VERSION ""

NS_ :

BS_:

BU_: AuxInput VT TECU TC Sprayer GPS
VAL_TABLE_ FMI 21 "Data Drifted Low" 20 "Data Drifted High" 31 "Not available" 19 "Received network data in error" 18 "Below normal (moderatels severe)" 17 "Below normal (least severe)" 16 "Above normal (moderately severe)" 15 "Above normal (least severe)" 14 "Special intstructions" 13 "Out of calibration" 12 "Bad intelligent device" 11 "Root cause not known" 10 "Abnormal rate of change" 9 "Abnormal update rate" 8 "Abnormal frequency" 7 "Mechanical system not responding" 6 "Current above normal" 5 "Current below normal" 4 "Voltage below normal" 3 "Voltage above normal" 2 "Data erratic" 1 "Below normal (most severe)" 0 "Above normal (most severe)" ;

BO_ 3221225472 VECTOR__INDEPENDENT_SIG_MSG: 0 Vector__XXX
 SG_ ErrorCodeLockUnlockMask9 : 0|1@1+ (1,0) [0|1] "" Vector__XXX
 SG_ CertificationYear : 0|6@1+ (1,2000) [2000|2061] "year" Vector__XXX
 SG_ CertificateRevision : 0|3@1+ (1,0) [0|7] "" Vector__XXX
 SG_ CertificateLaboratoryType : 0|3@1+ (1,0) [0|7] "" Vector__XXX
 SG_ CertificationLaboratoryID : 0|11@1+ (1,0) [0|2047] "" Vector__XXX
 SG_ CertTypeVTWorkingSetMember : 0|1@1+ (1,0) [0|1] "" Vector__XXX
 SG_ CertTypeVTWorkingSetMaster : 0|1@1+ (1,0) [0|1] "" Vector__XXX
 SG_ CertTypeVirtualTerminal : 0|1@1+ (1,0) [0|1] "" Vector__XXX
 SG_ CertTypeClass3ECU : 0|1@1+ (1,0) [0|1] "" Vector__XXX
 SG_ CertTypeTECUClass3 : 0|1@1+ (1,0) [0|1] "" Vector__XXX
 SG_ CertTypeTECUClass2 : 0|1@1+ (1,0) [0|1] "" Vector__XXX
 SG_ CertTypeTECUClass1 : 0|1@1+ (1,0) [0|1] "" Vector__XXX
 SG_ CertTypeMinimumECU : 0|1@1+ (1,0) [0|1] "" Vector__XXX
 SG_ CertTypeGPSReceiver : 0|1@1+ (1,0) [0|1] "" Vector__XXX
 SG_ CertTypeFileServer : 0|1@1+ (1,0) [0|1] "" Vector__XXX
 SG_ CertTypeTCWorkingSetMember : 0|1@1+ (1,0) [0|1] "" Vector__XXX
 SG_ CertTypeTCWorkingSetMaster : 0|1@1+ (1,0) [0|1] "" Vector__XXX
 SG_ CertTypeTaskController : 0|1@1+ (1,0) [0|1] "" Vector__XXX
 SG_ CertificationReferenceNumber : 0|16@1+ (1,0) [0|65535] "" Vector__XXX
 SG_ CertificationYear : 0|6@1+ (1,2000) [2000|2061] "year" Vector__XXX
 SG_ CertificateRevision : 0|3@1+ (1,0) [0|7] "" Vector__XXX
 SG_ CertificateLaboratoryType : 0|3@1+ (1,0) [0|7] "" Vector__XXX
 SG_ CertificationLaboratoryID : 0|11@1+ (1,0) [0|2047] "" Vector__XXX
 SG_ CertTypeVTWorkingSetMember : 0|1@1+ (1,0) [0|1] "" Vector__XXX
 SG_ CertTypeVTWorkingSetMaster : 0|1@1+ (1,0) [0|1] "" Vector__XXX
 SG_ CertTypeVirtualTerminal : 0|1@1+ (1,0) [0|1] "" Vector__XXX
 SG_ CertTypeClass3ECU : 0|1@1+ (1,0) [0|1] "" Vector__XXX
 SG_ CertTypeTECUClass3 : 0|1@1+ (1,0) [0|1] "" Vector__XXX
 SG_ CertTypeTECUClass2 : 0|1@1+ (1,0) [0|1] "" Vector__XXX
 SG_ CertTypeTECUClass1 : 0|1@1+ (1,0) [0|1] "" Vector__XXX
 SG_ CertTypeMinimumECU : 0|1@1+ (1,0) [0|1] "" Vector__XXX
 SG_ CertTypeGPSReceiver : 0|1@1+ (1,0) [0|1] "" Vector__XXX
 SG_ CertTypeFileServer : 0|1@1+ (1,0) [0|1] "" Vector__XXX
 SG_ CertTypeTCWorkingSetMember : 0|1@1+ (1,0) [0|1] "" Vector__XXX
 SG_ CertTypeTCWorkingSetMaster : 0|1@1+ (1,0) [0|1] "" Vector__XXX
 SG_ CertTypeTaskController : 0|1@1+ (1,0) [0|1] "" Vector__XXX
 SG_ CertificationReferenceNumber : 0|16@1+ (1,0) [0|65535] "" Vector__XXX
 SG_ CertificationYear : 0|6@1+ (1,2000) [2000|2061] "year" Vector__XXX
 SG_ CertificateRevision : 0|3@1+ (1,0) [0|7] "" Vector__XXX
 SG_ CertificateLaboratoryType : 0|3@1+ (1,0) [0|7] "" Vector__XXX

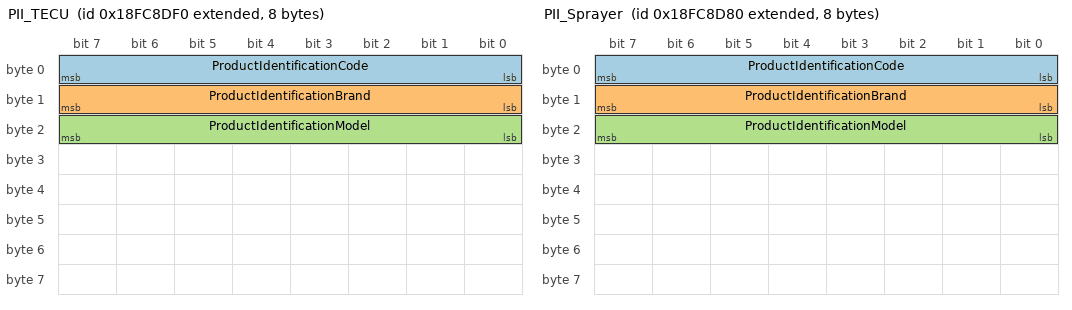
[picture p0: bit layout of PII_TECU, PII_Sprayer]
BO_ 2566688240 PII_TECU: 8 TECU
 SG_ ProductIdentificationCode : 0|8@1- (1,0) [0|0] "" Vector__XXX
 SG_ ProductIdentificationBrand : 8|8@1- (1,0) [0|0] "" Vector__XXX
 SG_ ProductIdentificationModel : 16|8@1- (1,0) [0|0] "" Vector__XXX

BO_ 2566688128 PII_Sprayer: 8 Sprayer
 SG_ ProductIdentificationCode : 0|8@1- (1,0) [0|0] "" Vector__XXX
 SG_ ProductIdentificationBrand : 8|8@1- (1,0) [0|0] "" Vector__XXX
 SG_ ProductIdentificationModel : 16|8@1- (1,0) [0|0] "" Vector__XXX

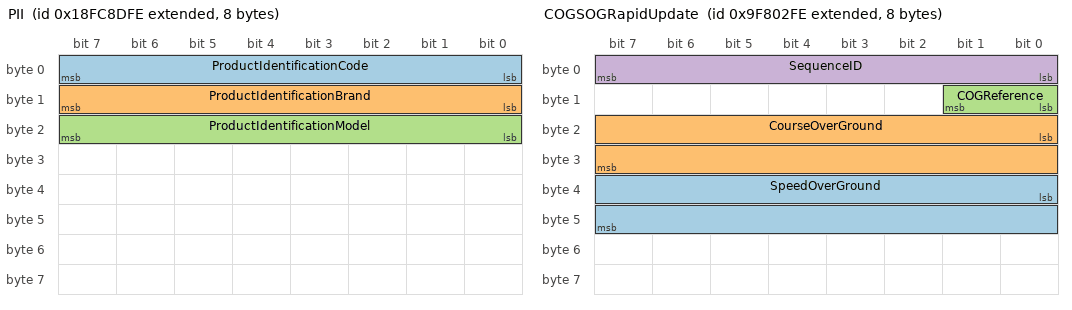
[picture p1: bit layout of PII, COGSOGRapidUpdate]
BO_ 2566688254 PII: 8 Vector__XXX
 SG_ ProductIdentificationCode : 0|8@1- (1,0) [0|0] "" Vector__XXX
 SG_ ProductIdentificationBrand : 8|8@1- (1,0) [0|0] "" Vector__XXX
 SG_ ProductIdentificationModel : 16|8@1- (1,0) [0|0] "" Vector__XXX

BO_ 2566734464 ICC_Sprayer: 8 Sprayer
 SG_ CertLaboratoryType_FirstDef m0 : 9|3@1+ (1,0) [0|7] "" Vector__XXX
 SG_ TestProtocolRevision_MSBits m1 : 11|2@1+ (1,0) [0|0] "" Vector__XXX
 SG_ MessageRevision M : 47|1@1+ (1,0) [0|0] "" Vector__XXX
 SG_ CertLaboratoryType_SecondDef m1 : 9|2@1+ (1,0) [0|3] "" Vector__XXX
 SG_ TestProtocolRevision : 6|3@1+ (1,0) [0|7] "" Vector__XXX
 SG_ TestProtocolPublicationYear : 0|6@1+ (1,2000) [2000|2061] "year" Vector__XXX
 SG_ CertificationLaboratoryID : 13|11@1+ (1,0) [0|2047] "" Vector__XXX
 SG_ CertTypeVTWorkingSetMember m0 : 24|1@1+ (1,0) [0|1] "" Vector__XXX
 SG_ CertTypeVTWorkingSetMaster m0 : 25|1@1+ (1,0) [0|1] "" Vector__XXX
 SG_ CertTypeVirtualTerminal m0 : 26|1@1+ (1,0) [0|1] "" Vector__XXX
 SG_ CertTypeClass3ECU m0 : 27|1@1+ (1,0) [0|1] "" Vector__XXX
 SG_ CertTypeTECUClass3 m0 : 28|1@1+ (1,0) [0|1] "" Vector__XXX
 SG_ CertTypeTECUClass2 m0 : 29|1@1+ (1,0) [0|1] "" Vector__XXX
 SG_ CertTypeTECUClass1 m0 : 30|1@1+ (1,0) [0|1] "" Vector__XXX
 SG_ CertTypeMinimumECU m0 : 31|1@1+ (1,0) [0|1] "" Vector__XXX
 SG_ CertTypeGPSReceiver m0 : 35|1@1+ (1,0) [0|1] "" Vector__XXX
 SG_ CertTypeFileServer m0 : 36|1@1+ (1,0) [0|1] "" Vector__XXX
 SG_ CertTypeTCWorkingSetMember m0 : 37|1@1+ (1,0) [0|1] "" Vector__XXX
 SG_ CertTypeTCWorkingSetMaster m0 : 38|1@1+ (1,0) [0|1] "" Vector__XXX
 SG_ CertTypeTaskController m0 : 39|1@1+ (1,0) [0|1] "" Vector__XXX
 SG_ CertificationReferenceNumber : 48|16@1+ (1,0) [0|65535] "" Vector__XXX

BO_ 2566734576 ICC_TECU: 8 TECU
 SG_ CertLaboratoryType_FirstDef m0 : 9|3@1+ (1,0) [0|7] "" Vector__XXX
 SG_ TestProtocolRevision_MSBits m1 : 11|2@1+ (1,0) [0|0] "" Vector__XXX
 SG_ MessageRevision M : 47|1@1+ (1,0) [0|0] "" Vector__XXX
 SG_ CertLaboratoryType_SecondDef m1 : 9|2@1+ (1,0) [0|3] "" Vector__XXX
 SG_ TestProtocolRevision : 6|3@1+ (1,0) [0|7] "" Vector__XXX
 SG_ TestProtocolPublicationYear : 0|6@1+ (1,2000) [2000|2061] "year" Vector__XXX
 SG_ CertificationLaboratoryID : 13|11@1+ (1,0) [0|2047] "" Vector__XXX
 SG_ CertTypeVTWorkingSetMember m0 : 24|1@1+ (1,0) [0|1] "" Vector__XXX
 SG_ CertTypeVTWorkingSetMaster m0 : 25|1@1+ (1,0) [0|1] "" Vector__XXX
 SG_ CertTypeVirtualTerminal m0 : 26|1@1+ (1,0) [0|1] "" Vector__XXX
 SG_ CertTypeClass3ECU m0 : 27|1@1+ (1,0) [0|1] "" Vector__XXX
 SG_ CertTypeTECUClass3 m0 : 28|1@1+ (1,0) [0|1] "" Vector__XXX
 SG_ CertTypeTECUClass2 m0 : 29|1@1+ (1,0) [0|1] "" Vector__XXX
 SG_ CertTypeTECUClass1 m0 : 30|1@1+ (1,0) [0|1] "" Vector__XXX
 SG_ CertTypeMinimumECU m0 : 31|1@1+ (1,0) [0|1] "" Vector__XXX
 SG_ CertTypeGPSReceiver m0 : 35|1@1+ (1,0) [0|1] "" Vector__XXX
 SG_ CertTypeFileServer m0 : 36|1@1+ (1,0) [0|1] "" Vector__XXX
 SG_ CertTypeTCWorkingSetMember m0 : 37|1@1+ (1,0) [0|1] "" Vector__XXX
 SG_ CertTypeTCWorkingSetMaster m0 : 38|1@1+ (1,0) [0|1] "" Vector__XXX
 SG_ CertTypeTaskController m0 : 39|1@1+ (1,0) [0|1] "" Vector__XXX
 SG_ CertificationReferenceNumber : 48|16@1+ (1,0) [0|65535] "" Vector__XXX

BO_ 2365391614 AISO: 8 Vector__XXX
 SG_ StopAllImplOpTransitionNum : 48|8@1+ (1,0) [0|0] "" Vector__XXX
 SG_ StopAllImplOpSwitchState : 56|2@1- (1,0) [0|3] "" Vector__XXX

BO_ 2632384130 VT12_AuxInput: 34 AuxInput
 SG_ UnsupportedVtFunction m253 : 8|8@1+ (1,0) [0|255] "" Vector__XXX
 SG_ AssignedAttribute2OfSet1 m39 : 105|1@1+ (1,0) [0|1] "" Vector__XXX
 SG_ AssignedAttribute1OfSet1 m39 : 104|1@1+ (1,0) [0|1] "" Vector__XXX
 SG_ FunctionAttributeOfSet1 m39 : 96|8@1+ (1,0) [0|255] "" Vector__XXX
 SG_ AuxiliaryFunctionObjectID m36 : 96|16@1+ (1,0) [0|65535] "" Vector__XXX
 SG_ NumberOfInstancesOfSet1 m39 : 88|8@1+ (1,0) [0|255] "" Vector__XXX
 SG_ NumberOfDifferentSetsOfUnit1 m39 : 80|8@1+ (1,0) [0|255] "" Vector__XXX
 SG_ AuxiliaryInputObjectID m36 : 80|16@1+ (1,0) [0|65535] "" Vector__XXX
 SG_ StoreAsPreferredAssignment m36 : 79|1@1+ (1,0) [0|1] "" Vector__XXX
 SG_ ErrorCodeChangeAttribute5 m175 : 76|1@1+ (1,0) [0|1] "" Vector__XXX
 SG_ AuxiliaryFunctionType m36 : 72|4@1+ (1,0) [0|15] "" Vector__XXX
 SG_ SelfConfigurableAddress m36 : 71|1@1+ (1,0) [0|1] "" Vector__XXX
 SG_ DeviceClassInstance m36 : 67|4@1+ (1,0) [0|15] "" Vector__XXX
 SG_ IndustryGroup m36 : 64|3@1+ (1,0) [0|7] "" Vector__XXX
 SG_ FontType_ProportionalFont m195 : 63|1@1+ (1,0) [0|1] "" Vector__XXX
 SG_ FontType_FlashHidden m195 : 62|1@1+ (1,0) [0|1] "" Vector__XXX
 SG_ FontType_FlashInverted m195 : 61|1@1+ (1,0) [0|1] "" Vector__XXX
 SG_ FontType_InvertedText m195 : 60|1@1+ (1,0) [0|1] "" Vector__XXX
 SG_ ErrorCodeChangePolygonScale5 m183 : 60|1@1+ (1,0) [0|1] "" Vector__XXX
 SG_ FontType_ItalicsText m195 : 59|1@1+ (1,0) [0|1] "" Vector__XXX
 SG_ FontType_UnderlinedText m195 : 58|1@1+ (1,0) [0|1] "" Vector__XXX
 SG_ FontType_CrossedOutText m195 : 57|1@1+ (1,0) [0|1] "" Vector__XXX
 SG_ DeviceClass m36 : 57|7@1+ (1,0) [0|127] "" Vector__XXX
 SG_ OperatingState2 m38 : 57|1@1+ (1,0) [0|1] "" Vector__XXX
 SG_ VTFunctionCode m254 : 56|8@1+ (1,0) [0|255] "" Vector__XXX
 SG_ FontType_BoldText m195 : 56|1@1+ (1,0) [0|1] "" Vector__XXX
 SG_ NumberOfPhysicalSoftKeys m194 : 56|8@1+ (1,0) [0|255] "" Vector__XXX
 SG_ NumberOfRanges m193 : 56|8@1+ (1,0) [0|255] "" Vector__XXX
 SG_ ErrorCodeChangePolygonScale1 m183 : 56|1@1+ (1,0) [0|1] "" Vector__XXX
 SG_ OperatingState1 m38 : 56|1@1+ (1,0) [0|1] "" Vector__XXX
 SG_ VTBusyCode8 m254 : 55|1@1+ (1,0) [0|1] "" Vector__XXX
 SG_ FontSize_128x192 m195 : 54|1@1+ (1,0) [0|1] "" Vector__XXX
 SG_ VTBusyCode7 m254 : 54|1@1+ (1,0) [0|1] "" Vector__XXX
 SG_ FontSize_128x128 m195 : 53|1@1+ (1,0) [0|1] "" Vector__XXX
 SG_ VTBusyCode5 m254 : 52|1@1+ (1,0) [0|1] "" Vector__XXX
 SG_ FontSize_96x128 m195 : 52|1@1+ (1,0) [0|1] "" Vector__XXX
 SG_ ErrorCodeGetSupportedWideChars2 m193 : 52|1@1+ (1,0) [0|1] "" Vector__XXX
 SG_ ErrorCodeChangeListItem5 m177 : 52|1@1+ (1,0) [0|1] "" Vector__XXX
 SG_ ErrorCodeChangeListItem4 m177 : 51|1@1+ (1,0) [0|1] "" Vector__XXX
 SG_ VTBusyCode4 m254 : 51|1@1+ (1,0) [0|1] "" Vector__XXX
 SG_ FontSize_64x96 m195 : 51|1@1+ (1,0) [0|1] "" Vector__XXX
 SG_ ErrorCodeObjectPool4 m18 : 51|1@1+ (1,0) [0|1] "" Vector__XXX
 SG_ VTBusyCode3 m254 : 50|1@1+ (1,0) [0|1] "" Vector__XXX
 SG_ FontSize_64x64 m195 : 50|1@1+ (1,0) [0|1] "" Vector__XXX
 SG_ ErrorCodeChangeListItem3 m177 : 50|1@1+ (1,0) [0|1] "" Vector__XXX
 SG_ ErrorCodeObjectPool3 m18 : 50|1@1+ (1,0) [0|1] "" Vector__XXX
 SG_ VTBusyCode2 m254 : 49|1@1+ (1,0) [0|1] "" Vector__XXX
 SG_ FontSize_48x64 m195 : 49|1@1+ (1,0) [0|1] "" Vector__XXX
 SG_ ErrorCodeChangeListItem2 m177 : 49|1@1+ (1,0) [0|1] "" Vector__XXX
 SG_ ErrorCodeObjectPool2 m18 : 49|1@1+ (1,0) [0|1] "" Vector__XXX
 SG_ VTBusyCode1 m254 : 48|1@1+ (1,0) [0|1] "" Vector__XXX
 SG_ NrOfYPixelsInDataAreaMask m199 : 48|16@1+ (1,0) [0|65535] "" Vector__XXX
 SG_ FontSize_32x48 m195 : 48|1@1+ (1,0) [0|1] "" Vector__XXX
 SG_ NumberOfPossibleVirtualSoftKeys m194 : 48|8@1+ (1,0) [0|255] "" Vector__XXX
 SG_ ErrorCodeGetSupportedWideChars1 m193 : 48|1@1+ (1,0) [0|1] "" Vector__XXX
 SG_ ErrorCodeChangeListItem1 m177 : 48|1@1+ (1,0) [0|1] "" Vector__XXX
 SG_ Function m36 : 48|8@1+ (1,0) [0|255] "" Vector__XXX
 SG_ ErrorCodeObjectPool1 m18 : 48|1@1+ (1,0) [0|1] "" Vector__XXX
 SG_ VTChangeActiveMaskParentID m6 : 48|16@1+ (1,0) [0|65535] "" Vector__XXX
 SG_ ButtonKeyCode m1 : 48|8@1+ (1,0) [0|255] "" Vector__XXX
 SG_ SoftKeyCode m0 : 48|8@1+ (1,0) [0|255] "" Vector__XXX
 SG_ BooleanValue m33 : 48|8@1+ (1,0) [0|2] "" Vector__XXX
 SG_ Status_2 m9 : 48|8@1+ (1,0) [0|1] "" Vector__XXX
 SG_ ErrorCodeVTChangeSoftKeyMask6 m7 : 46|1@1+ (1,0) [0|1] "" Vector__XXX
 SG_ FontSize_32x32 m195 : 46|1@1+ (1,0) [0|1] "" Vector__XXX
 SG_ FontSize_24x32 m195 : 45|1@1+ (1,0) [0|1] "" Vector__XXX
 SG_ FontSize_16x24 m195 : 44|1@1+ (1,0) [0|1] "" Vector__XXX
 SG_ ErrorCodeChangePosInvalidError m180 : 44|1@1+ (1,0) [0|1] "" Vector__XXX
 SG_ ErrorCodeChangeSoftKeyMask5 m174 : 44|1@1+ (1,0) [0|1] "" Vector__XXX
 SG_ ErrorCodeChangeChildLocation5 m165 : 44|1@1+ (1,0) [0|1] "" Vector__XXX
 SG_ ErrorCodeVTChangeSoftKeyMask5 m7 : 44|1@1+ (1,0) [0|1] "" Vector__XXX
 SG_ ErrorCodeChangeStrValueInUse m179 : 44|1@1+ (1,0) [0|1] "" Vector__XXX
 SG_ ErrorCodeVtObjPoolError4 m240 : 43|1@1+ (1,0) [0|1] "" Vector__XXX
 SG_ FontSize_16x16 m195 : 43|1@1+ (1,0) [0|1] "" Vector__XXX
 SG_ ErrorCodeChangeStrError m179 : 43|1@1+ (1,0) [0|1] "" Vector__XXX
 SG_ ErrorCodeChangeSoftKeyMask4 m174 : 43|1@1+ (1,0) [0|1] "" Vector__XXX
 SG_ FunctionInstance m36 : 43|5@1+ (1,0) [0|31] "" Vector__XXX
 SG_ ErrorCodeVTChangeSoftKeyMask4 m7 : 43|1@1+ (1,0) [0|1] "" Vector__XXX
 SG_ ErrorCodeVtObjPoolError3 m240 : 42|1@1+ (1,0) [0|1] "" Vector__XXX
 SG_ FontSize_12x16 m195 : 42|1@1+ (1,0) [0|1] "" Vector__XXX
 SG_ ErrorCodeChangeStrTooLong m179 : 42|1@1+ (1,0) [0|1] "" Vector__XXX
 SG_ ErrorCodeChangeSoftKeyMask3 m174 : 42|1@1+ (1,0) [0|1] "" Vector__XXX
 SG_ ErrorCodeVTChangeSoftKeyMask3 m7 : 42|1@1+ (1,0) [0|1] "" Vector__XXX
 SG_ ErrorCodeVtObjPoolError2 m240 : 41|1@1+ (1,0) [0|1] "" Vector__XXX
 SG_ FontSize_8x12 m195 : 41|1@1+ (1,0) [0|1] "" Vector__XXX
 SG_ ErrorCodeChangePosInvalidObject m180 : 41|1@1+ (1,0) [0|1] "" Vector__XXX
 SG_ ErrorCodeChangeStrObjectID m179 : 41|1@1+ (1,0) [0|1] "" Vector__XXX
 SG_ ErrorCodeChangeSoftKeyMask2 m174 : 41|1@1+ (1,0) [0|1] "" Vector__XXX
 SG_ ErrorCodeChangeChildLocation2 m165 : 41|1@1+ (1,0) [0|1] "" Vector__XXX
 SG_ ErrorCodeVTChangeSoftKeyMask2 m7 : 41|1@1+ (1,0) [0|1] "" Vector__XXX
 SG_ ErrorCodeVtObjPoolError1 m240 : 40|1@1+ (1,0) [0|1] "" Vector__XXX
 SG_ AcknowledgmentDeleteVersion m210 : 40|4@1+ (1,0) [0|8] "" Vector__XXX
 SG_ AcknowledgmentLoadVersion m209 : 40|4@1+ (1,0) [0|8] "" Vector__XXX
 SG_ AcknowledgmentStoreVersion m208 : 40|4@1+ (1,0) [0|8] "" Vector__XXX
 SG_ FontSize_8x8 m195 : 40|1@1+ (1,0) [0|1] "" Vector__XXX
 SG_ YDotsForSoftKeyDescriptor m194 : 40|8@1+ (1,0) [0|255] "" Vector__XXX
 SG_ NewHeigthAttribute m183 : 40|16@1+ (1,0) [0|0] "" Vector__XXX
 SG_ ErrorCodeChangePosInvalidParent m180 : 40|1@1+ (1,0) [0|1] "" Vector__XXX
 SG_ ErrorCodeChangeSoftKeyMask1 m174 : 40|1@1+ (1,0) [0|1] "" Vector__XXX
 SG_ ErrorCodeChangeChildLocation1 m165 : 40|1@1+ (1,0) [0|1] "" Vector__XXX
 SG_ Value2 m38 : 40|16@1+ (1,0) [0|65535] "" Vector__XXX
 SG_ ECUInstance m36 : 40|3@1+ (1,0) [0|7] "" Vector__XXX
 SG_ TouchState m2 : 40|8@1+ (1,0) [0|255] "" Vector__XXX
 SG_ ErrorCodeVTChangeSoftKeyMask1 m7 : 40|1@1+ (1,0) [0|1] "" Vector__XXX
 SG_ ErrorCodeSelectObject6 m162 : 37|1@1+ (1,0) [0|1] "" Vector__XXX
 SG_ ErrorCodeGraphicsContextCmd5 m184 : 36|1@1+ (1,0) [0|1] "" Vector__XXX
 SG_ ErrorCodeChangePriority3 m176 : 36|1@1+ (1,0) [0|1] "" Vector__XXX
 SG_ ErrorCodeChangeAttribute4 m175 : 35|1@1+ (1,0) [0|1] "" Vector__XXX
 SG_ ErrorCodeChangeColour3 m167 : 36|1@1+ (1,0) [0|1] "" Vector__XXX
 SG_ ErrorCodeSelectObject5 m162 : 36|1@1+ (1,0) [0|1] "" Vector__XXX
 SG_ ErrorCodeEnableDisableObj4 m161 : 36|1@1+ (1,0) [0|1] "" Vector__XXX
 SG_ ErrorCodeGraphicsContextCmd4 m184 : 35|1@1+ (1,0) [0|1] "" Vector__XXX
 SG_ ErrorCodeSelectObject4 m162 : 35|1@1+ (1,0) [0|1] "" Vector__XXX
 SG_ ErrorCodeEnableDisableObj3 m161 : 35|1@1+ (1,0) [0|1] "" Vector__XXX
 SG_ ErrorCodeHideShowObj3 m160 : 35|1@1+ (1,0) [0|1] "" Vector__XXX
 SG_ ErrorCodeGraphicsContextCmd3 m184 : 34|1@1+ (1,0) [0|1] "" Vector__XXX
 SG_ ErrorCodeChangeAttribute3 m175 : 34|1@1+ (1,0) [0|1] "" Vector__XXX
 SG_ ErrorCodeSelectObject3 m162 : 34|1@1+ (1,0) [0|1] "" Vector__XXX
 SG_ ErrorCodeEnableDisableObj2 m161 : 34|1@1+ (1,0) [0|1] "" Vector__XXX
 SG_ ErrorCodeGraphicsContextCmd2 m184 : 33|1@1+ (1,0) [0|1] "" Vector__XXX
 SG_ ErrorCodeChangePriority2 m176 : 33|1@1+ (1,0) [0|1] "" Vector__XXX
 SG_ ErrorCodeChangeAttribute2 m175 : 33|1@1+ (1,0) [0|1] "" Vector__XXX
 SG_ ErrorCodeChangeColour2 m167 : 33|1@1+ (1,0) [0|1] "" Vector__XXX
 SG_ ErrorCodeSelectObject2 m162 : 33|1@1+ (1,0) [0|1] "" Vector__XXX
 SG_ ErrorCodeEnableDisableObj1 m161 : 33|1@1+ (1,0) [0|1] "" Vector__XXX
 SG_ ErrorCodeHideShowObj2 m160 : 33|1@1+ (1,0) [0|1] "" Vector__XXX
 SG_ VisibleSoftKeyMaskObjectID m254 : 32|16@1+ (1,0) [0|65535] "" Vector__XXX
 SG_ NrOfXPixelsInDataAreaMask m199 : 32|16@1+ (1,0) [0|65535] "" Vector__XXX
 SG_ XDotsForSoftKeyDescriptor m194 : 32|8@1+ (1,0) [0|255] "" Vector__XXX
 SG_ LastWideChar m193 : 32|16@1+ (1,0) [0|65535] "" Vector__XXX
 SG_ ErrorCodeGraphicsContextCmd1 m184 : 32|1@1+ (1,0) [0|1] "" Vector__XXX
 SG_ NewObjectID m177 : 32|16@1+ (1,0) [0|65535] "" Vector__XXX
 SG_ ErrorCodeChangePriority1 m176 : 32|1@1+ (1,0) [0|1] "" Vector__XXX
 SG_ ErrorCodeChangeAttribute1 m175 : 32|1@1+ (1,0) [0|1] "" Vector__XXX
 SG_ ValueOfTheObject m168 : 32|32@1+ (1,0) [0|2704] "" Vector__XXX
 SG_ ErrorCodeChangeColour1 m167 : 32|1@1+ (1,0) [0|1] "" Vector__XXX
 SG_ ErrorCodeSelectObject1 m162 : 32|1@1+ (1,0) [0|1] "" Vector__XXX
 SG_ ErrorCodeHideShowObj1 m160 : 32|1@1+ (1,0) [0|1] "" Vector__XXX
 SG_ ObjectIdOfFaultyObject m18 : 32|16@1+ (1,0) [0|65535] "" Vector__XXX
 SG_ VTChangeActiveMaskErrorID m6 : 32|16@1+ (1,0) [0|65535] "" Vector__XXX
 SG_ VTChangeNumericValueValue m5 : 32|32@1+ (1,0) [0|4294967295] "" Vector__XXX
 SG_ VTSelectInputObjectIsEdited m3 : 32|1@1+ (1,0) [0|1] "" Vector__XXX
 SG_ ButtonObjectParentID m1 : 32|16@1+ (1,0) [0|65535] "" Vector__XXX
 SG_ KeyObjectParentID m0 : 32|16@1+ (1,0) [0|65535] "" Vector__XXX
 SG_ NumTransitionsDisabledToEnabled m33 : 32|16@1+ (1,0) [0|65535] "" Vector__XXX
 SG_ ObjectID_2 m9 : 32|16@1+ (1,0) [0|65535] "" Vector__XXX
 SG_ Hardware6 m199 : 29|1@1+ (1,0) [0|1] "" Vector__XXX
 SG_ ErrorCodeChangeFont6 m170 : 29|1@1+ (1,0) [0|1] "" Vector__XXX
 SG_ ManufacturerCode m36 : 29|11@1+ (1,0) [0|2047] "" Vector__XXX
 SG_ ErrorCodePoolDeleted m6 : 29|1@1+ (1,0) [0|1] "" Vector__XXX
 SG_ Hardware5 m199 : 28|1@1+ (1,0) [0|1] "" Vector__XXX
 SG_ ErrorCodeChangeActiveMask5 m173 : 28|1@1+ (1,0) [0|1] "" Vector__XXX
 SG_ ErrorCodeChangeFillAttributes5 m172 : 28|1@1+ (1,0) [0|1] "" Vector__XXX
 SG_ ErrorCodeChangeLineAttribute4 m171 : 28|1@1+ (1,0) [0|1] "" Vector__XXX
 SG_ ErrorCodeChangeFont5 m170 : 28|1@1+ (1,0) [0|1] "" Vector__XXX
 SG_ ErrorCodeChangeEditPoint3 m169 : 28|1@1+ (1,0) [0|1] "" Vector__XXX
 SG_ ErrorCodeObjToSize4 m166 : 28|1@1+ (1,0) [0|1] "" Vector__XXX
 SG_ ErrorCodeEscapeObj2 m146 : 28|1@1+ (1,0) [0|1] "" Vector__XXX
 SG_ ErrorCodeAnyOtherError m6 : 28|1@1+ (1,0) [0|1] "" Vector__XXX
 SG_ ErrorCodeVTEsc2 m4 : 28|1@1+ (1,0) [0|1] "" Vector__XXX
 SG_ ErrorCodeChangeNumValue4 m168 : 28|1@1+ (1,0) [0|1] "" Vector__XXX
 SG_ Hardware4 m199 : 27|1@1+ (1,0) [0|1] "" Vector__XXX
 SG_ ErrorCodeChangeActiveMask4 m173 : 27|1@1+ (1,0) [0|1] "" Vector__XXX
 SG_ ErrorCodeChangeFillAttributes4 m172 : 27|1@1+ (1,0) [0|1] "" Vector__XXX
 SG_ ErrorCodeChangeFont4 m170 : 27|1@1+ (1,0) [0|1] "" Vector__XXX
 SG_ ErrorCodeMaskOrChildObjectError m6 : 27|1@1+ (1,0) [0|1] "" Vector__XXX
 SG_ ErrorCodeChangeNumValue3 m168 : 26|1@1+ (1,0) [0|1] "" Vector__XXX
 SG_ Hardware3 m199 : 26|1@1+ (1,0) [0|1] "" Vector__XXX
 SG_ ErrorCodeChangePoygonPoint3 m182 : 26|1@1+ (1,0) [0|1] "" Vector__XXX
 SG_ ErrorCodeChangeActiveMask3 m173 : 26|1@1+ (1,0) [0|1] "" Vector__XXX
 SG_ ErrorCodeChangeFillAttributes3 m172 : 26|1@1+ (1,0) [0|1] "" Vector__XXX
 SG_ ErrorCodeChangeLineAttribute3 m171 : 26|1@1+ (1,0) [0|1] "" Vector__XXX
 SG_ ErrorCodeChangeFont3 m170 : 26|1@1+ (1,0) [0|1] "" Vector__XXX
 SG_ ErrorCodeObjToSize3 m166 : 26|1@1+ (1,0) [0|1] "" Vector__XXX
 SG_ ErrorCodeMissingObjects m6 : 26|1@1+ (1,0) [0|1] "" Vector__XXX
 SG_ ErrorCodeExecuteExtendedMacro3 m188 : 26|1@1+ (1,0) [0|1] "" Vector__XXX
 SG_ Hardware2 m199 : 25|1@1+ (1,0) [0|1] "" Vector__XXX
 SG_ ErrorCodeSelectColourMap2 m186 : 25|1@1+ (1,0) [0|1] "" Vector__XXX
 SG_ ErrorCodeChangePoygonPoint2 m182 : 25|1@1+ (1,0) [0|1] "" Vector__XXX
 SG_ ErrorCodeChangeActiveMask2 m173 : 25|1@1+ (1,0) [0|1] "" Vector__XXX
 SG_ ErrorCodeChangeFillAttributes2 m172 : 25|1@1+ (1,0) [0|1] "" Vector__XXX
 SG_ ErrorCodeChangeLineAttribute2 m171 : 25|1@1+ (1,0) [0|1] "" Vector__XXX
 SG_ ErrorCodeChangeFont2 m170 : 25|1@1+ (1,0) [0|1] "" Vector__XXX
 SG_ ErrorCodeChangeEditPoint2 m169 : 25|1@1+ (1,0) [0|1] "" Vector__XXX
 SG_ ErrorCodeChangeNumValue2 m168 : 25|1@1+ (1,0) [0|1] "" Vector__XXX
 SG_ ErrorCodeObjToSize2 m166 : 25|1@1+ (1,0) [0|1] "" Vector__XXX
 SG_ ErrorCodeExecuteExtendedMacro2 m188 : 25|1@1+ (1,0) [0|1] "" Vector__XXX
 SG_ ObjectIDOfFaultyObject m240 : 24|16@1+ (1,0) [0|65535] "" Vector__XXX
 SG_ Hardware1 m199 : 24|1@1+ (1,0) [0|1] "" Vector__XXX
 SG_ ErrorCodeSelectColourMap1 m186 : 24|1@1+ (1,0) [0|1] "" Vector__XXX
 SG_ AttributeID m185 : 24|8@1+ (1,0) [0|0] "" Vector__XXX
 SG_ SubCommandID m184 : 24|8@1+ (1,0) [0|0] "" Vector__XXX
 SG_ NewWidthAttribute m183 : 24|16@1+ (1,0) [0|65535] "" Vector__XXX
 SG_ ErrorCodeChangePoygonPoint1 m182 : 24|1@1+ (1,0) [0|1] "" Vector__XXX
 SG_ ChangeChildPositionObjectID m180 : 24|16@1+ (1,0) [0|65535] "" Vector__XXX
 SG_ ChangeStringValueObjectID m179 : 24|16@1+ (1,0) [0|65535] "" Vector__XXX
 SG_ ListIndex m177 : 24|8@1+ (1,0) [0|255] "" Vector__XXX
 SG_ NewPriority m176 : 24|8@1+ (1,0) [0|255] "" Vector__XXX
 SG_ AttributeToChangeID m175 : 24|8@1+ (1,0) [0|65535] "" Vector__XXX
 SG_ SoftKeyMaskObjectID m174 : 24|16@1+ (1,0) [0|65535] "" Vector__XXX
 SG_ ErrorCodeChangeActiveMask1 m173 : 24|1@1+ (1,0) [0|1] "" Vector__XXX
 SG_ ErrorCodeChangeFillAttributes1 m172 : 24|1@1+ (1,0) [0|1] "" Vector__XXX
 SG_ ErrorCodeChangeLineAttribute1 m171 : 24|1@1+ (1,0) [0|1] "" Vector__XXX
 SG_ ErrorCodeChangeFont1 m170 : 24|1@1+ (1,0) [0|1] "" Vector__XXX
 SG_ ErrorCodeChangeEditPoint1 m169 : 24|1@1+ (1,0) [0|1] "" Vector__XXX
 SG_ ErrorCodeChangeNumValue1 m168 : 24|1@1+ (1,0) [0|1] "" Vector__XXX
 SG_ NewBackgroundColour m167 : 24|8@1+ (1,0) [0|255] "" Vector__XXX
 SG_ ErrorCodeObjToSize1 m166 : 24|1@1+ (1,0) [0|1] "" Vector__XXX
 SG_ ChangeChildLocationObjectID m165 : 24|16@1+ (1,0) [0|65535] "" Vector__XXX
 SG_ ObjectSelectStatus m162 : 24|8@1+ (1,0) [0|2] "" Vector__XXX
 SG_ ObjectEnableStatus m161 : 24|8@1+ (1,0) [0|1] "" Vector__XXX
 SG_ ObjectShowStatus m160 : 24|8@1+ (1,0) [0|1] "" Vector__XXX
 SG_ ErrorCodeEscapeObj1 m146 : 24|1@1+ (1,0) [0|1] "" Vector__XXX
 SG_ AuxInputEnable m37 : 24|8@1+ (1,0) [0|1] "" Vector__XXX
 SG_ Value1 m38 : 24|16@1+ (1,0) [0|65535] "" Vector__XXX
 SG_ EnteredStringValue m8 : 24|8@1+ (1,0) [0|255] "" Vector__XXX
 SG_ VTChangeSoftKeyMaskObjectID m7 : 24|16@1+ (1,0) [0|65535] "" Vector__XXX
 SG_ ErrorCodeVTEsc1 m4 : 24|1@1+ (1,0) [0|1] "" Vector__XXX
 SG_ VTSelectInputObjectStatus m3 : 24|8@1+ (1,0) [0|1] "" Vector__XXX
 SG_ YPosition m2 : 24|16@1+ (1,0) [0|65535] "" Vector__XXX
 SG_ Status_1 m9 : 24|8@1+ (1,0) [0|1] "" Vector__XXX
 SG_ ErrorCodeExecuteExtendedMacro1 m188 : 24|1@1+ (1,0) [0|1] "" Vector__XXX
 SG_ ErrorCodeLockUnlockMask8 m189 : 23|1@1+ (1,0) [0|1] "" Vector__XXX
 SG_ ErrorCodeLockUnlockMask7 m189 : 22|1@1+ (1,0) [0|1] "" Vector__XXX
 SG_ ErrorCodeLockUnlockMask6 m189 : 21|1@1+ (1,0) [0|1] "" Vector__XXX
 SG_ ErrorCodeLockUnlockMask5 m189 : 20|1@1+ (1,0) [0|1] "" Vector__XXX
 SG_ ErrorCodeLockUnlockMask4 m189 : 19|1@1+ (1,0) [0|1] "" Vector__XXX
 SG_ ErrorCodeExecuteMacro3 m190 : 18|1@1+ (1,0) [0|1] "" Vector__XXX
 SG_ ErrorCodeLockUnlockMask3 m189 : 18|1@1+ (1,0) [0|1] "" Vector__XXX
 SG_ ErrorCodeExecuteMacro2 m190 : 17|1@1+ (1,0) [0|1] "" Vector__XXX
 SG_ ErrorCodeLockUnlockMask2 m189 : 17|1@1+ (1,0) [0|1] "" Vector__XXX
 SG_ NameOfAuxiliaryUnit1 m39 : 16|64@1+ (1,0) [0|0] "" Vector__XXX
 SG_ ExtendedVersionLables m211 : 16|256@1+ (1,0) [0|7.20575940379279E+016] "" Vector__XXX
 SG_ VisibleDataOrAlarmMaskObjectID m254 : 16|16@1+ (1,0) [0|65535] "" Vector__XXX
 SG_ VersionLables m224 : 16|56@1+ (1,0) [0|0] "" Vector__XXX
 SG_ SupportedGraphicMode m199 : 16|8@1+ (1,0) [0|2] "" Vector__XXX
 SG_ FirstWideChar m193 : 16|16@1+ (1,0) [0|65535] "" Vector__XXX
 SG_ MemoryStatus m192 : 16|8@1+ (1,0) [0|1] "" Vector__XXX
 SG_ ErrorCodeExecuteMacro1 m190 : 16|1@1+ (1,0) [0|1] "" Vector__XXX
 SG_ ErrorCodeLockUnlockMask1 m189 : 16|1@1+ (1,0) [0|1] "" Vector__XXX
 SG_ ParentObjectIDOfFaultyObject m18 : 16|16@1+ (1,0) [0|65535] "" Vector__XXX
 SG_ ButtonObjectID m1 : 16|16@1+ (1,0) [0|65535] "" Vector__XXX
 SG_ KeyObjectID m0 : 16|16@1+ (1,0) [0|65535] "" Vector__XXX
 SG_ AuxFunctObjOfFaultyAssignment m34 : 16|16@1- (1,0) [0|65535] "" Vector__XXX
 SG_ AnalogValue m33 : 16|16@1+ (1,0) [0|65535] "" Vector__XXX
 SG_ BckgndColourUserLayoutSoftkeyMas m196 : 16|8@1+ (1,0) [0|255] "" Vector__XXX
 SG_ ErrorCodeSetObjectLabel6 m181 : 13|1@1+ (1,0) [0|1] "" Vector__XXX
 SG_ ErrorCodeSetObjectLabel5 m181 : 12|1@1+ (1,0) [0|1] "" Vector__XXX
 SG_ ErrorCodeDeleteObjectPool2 m178 : 12|1@1+ (1,0) [0|1] "" Vector__XXX
 SG_ ErrorCodeAudioVolume2 m164 : 12|1@1+ (1,0) [0|1] "" Vector__XXX
 SG_ ErrorCodeControlAudioDevice2 m163 : 12|1@1+ (1,0) [0|1] "" Vector__XXX
 SG_ ErrorCodeEndOfObjectPool3 m18 : 12|1@1+ (1,0) [0|1] "" Vector__XXX
 SG_ AuxPreferredAssignmentRespError5 m34 : 12|1@1+ (1,0) [0|1] "" Vector__XXX
 SG_ ErrorCodeSetObjectLabel4 m181 : 11|1@1+ (1,0) [0|1] "" Vector__XXX
 SG_ AuxPreferredAssignmentRespError4 m34 : 11|1@1+ (1,0) [0|1] "" Vector__XXX
 SG_ ErrorCodeSetObjectLabel3 m181 : 10|1@1+ (1,0) [0|1] "" Vector__XXX
 SG_ AuxPreferredAssignmentRespError3 m34 : 10|1@1+ (1,0) [0|1] "" Vector__XXX
 SG_ ErrorCodeSetObjectLabel2 m181 : 9|1@1+ (1,0) [0|1] "" Vector__XXX
 SG_ AuxPreferredAssignmentRespError2 m34 : 9|1@1+ (1,0) [0|1] "" Vector__XXX
 SG_ ErrorCodeEndOfObjectPool2 m18 : 9|1@1+ (1,0) [0|1] "" Vector__XXX
 SG_ SourceAdressOfActiveWSM m254 : 8|8@1+ (1,0) [0|255] "" Vector__XXX
 SG_ ParentIDOfFaultyObject m240 : 8|16@1+ (1,0) [0|65535] "" Vector__XXX
 SG_ NrOfVersionStrings m224 : 8|8@1+ (1,0) [0|255] "" Vector__XXX
 SG_ NavigationSoftKeys m194 : 8|8@1+ (1,0) [0|254] "" Vector__XXX
 SG_ CodePlane m193 : 8|8@1+ (1,0) [0|16] "" Vector__XXX
 SG_ VersionNumberISO11783Part6 m192 : 8|8@1+ (1,0) [0|255] "" Vector__XXX
 SG_ MacroObjectID m190 : 8|8@1+ (1,0) [0|255] "" Vector__XXX
 SG_ LockUnlockCommand m189 : 8|8@1+ (1,0) [0|1] "" Vector__XXX
 SG_ ColourMapObjectID m186 : 8|16@1+ (1,0) [0|65535] "" Vector__XXX
 SG_ ObjectToGetAttributeID m185 : 8|16@1+ (1,0) [0|65535] "" Vector__XXX
 SG_ GraphicsContextObjectID m184 : 8|16@1+ (1,0) [0|65535] "" Vector__XXX
 SG_ PolygonObjectToScaleID m183 : 8|16@1+ (1,0) [0|65535] "" Vector__XXX
 SG_ PolygonObjectToChangeID m182 : 8|16@1+ (1,0) [0|65535] "" Vector__XXX
 SG_ ErrorCodeSetObjectLabel1 m181 : 8|1@1+ (1,0) [0|1] "" Vector__XXX
 SG_ ChangeChildPositionParentObjectI m180 : 8|16@1+ (1,0) [0|65535] "" Vector__XXX
 SG_ ErrorCodeDeleteObjectPool1 m178 : 8|1@1+ (1,0) [0|1] "" Vector__XXX
 SG_ ListInputObjectID m177 : 8|16@1+ (1,0) [0|65535] "" Vector__XXX
 SG_ AlarmMaskObjectID m176 : 8|16@1+ (1,0) [0|65535] "" Vector__XXX
 SG_ ObjectToChangeAttributeID m175 : 8|16@1+ (1,0) [0|65535] "" Vector__XXX
 SG_ DataOrAlarmMaskObjectID m174 : 8|16@1+ (1,0) [0|65535] "" Vector__XXX
 SG_ ActiveMaskObjectID m173 : 8|16@1+ (1,0) [0|0] "" Vector__XXX
 SG_ ObjectToChangeFillAttributesID m172 : 8|16@1+ (1,0) [0|65535] "" Vector__XXX
 SG_ ObjectToChangeLineAttributeID m171 : 8|16@1+ (1,0) [0|65535] "" Vector__XXX
 SG_ ObjectToChangeFontID m170 : 8|16@1+ (1,0) [0|65535] "" Vector__XXX
 SG_ ObjectToChangeEndPointID m169 : 8|16@1+ (1,0) [0|65535] "" Vector__XXX
 SG_ ObjectToChangeNumValueID m168 : 8|16@1+ (1,0) [0|65535] "" Vector__XXX
 SG_ ObjectToChangeColourID m167 : 8|16@1+ (1,0) [0|65535] "" Vector__XXX
 SG_ ObjectToSizeID m166 : 8|16@1+ (1,0) [0|65535] "" Vector__XXX
 SG_ ChangeChildLocationParentObjectI m165 : 8|16@1+ (1,0) [0|65535] "" Vector__XXX
 SG_ ErrorCodeAudioVolume1 m164 : 8|1@1+ (1,0) [0|1] "" Vector__XXX
 SG_ ErrorCodeControlAudioDevice1 m163 : 8|1@1+ (1,0) [0|1] "" Vector__XXX
 SG_ SelectInputObjectID m162 : 8|16@1+ (1,0) [0|65535] "" Vector__XXX
 SG_ ObjectToEnableDisableID m161 : 8|16@1+ (1,0) [0|65535] "" Vector__XXX
 SG_ ObjectToHideShowID m160 : 8|16@1+ (1,0) [0|65535] "" Vector__XXX
 SG_ ObjectEscapeID m146 : 8|16@1+ (1,0) [0|65535] "" Vector__XXX
 SG_ InputStatusObjectId m37 : 8|16@1+ (1,0) [0|255] "" Vector__XXX
 SG_ AuxPreferredAssignmentRespError1 m34 : 8|1@1+ (1,0) [0|1] "" Vector__XXX
 SG_ InputObjectId m38 : 8|16@1+ (1,0) [0|255] "" Vector__XXX
 SG_ IdentityNumber m36 : 8|21@1+ (1,0) [0|2097150] "" Vector__XXX
 SG_ ErrorCodeEndOfObjectPool1 m18 : 8|1@1+ (1,0) [0|1] "" Vector__XXX
 SG_ ObjectToChangeStringID m8 : 8|16@1+ (1,0) [0|65535] "" Vector__XXX
 SG_ VTChangeSoftKeyMaskParentID m7 : 8|16@1+ (1,0) [0|65535] "" Vector__XXX
 SG_ VTChangeActiveMaskObjectID m6 : 8|16@1+ (1,0) [0|65535] "" Vector__XXX
 SG_ VTChangeNumericValueObjectID m5 : 8|16@1+ (1,0) [0|65535] "" Vector__XXX
 SG_ VTEscObjectID m4 : 8|16@1+ (1,0) [0|65535] "" Vector__XXX
 SG_ VTSelectInputObjectID m3 : 8|16@1+ (1,0) [0|65535] "" Vector__XXX
 SG_ XPosition m2 : 8|16@1+ (1,0) [0|65535] "" Vector__XXX
 SG_ ButtonActivationCode m1 : 8|8@1+ (1,0) [0|2] "" Vector__XXX
 SG_ KeyActivationCode m0 : 8|8@1+ (1,0) [0|2] "" Vector__XXX
 SG_ TerminationCause m10 : 8|8@1+ (1,0) [0|255] "" Vector__XXX
 SG_ InputNumber m33 : 8|8@1+ (1,0) [0|250] "" Vector__XXX
 SG_ ObjectID_1 m9 : 8|16@1+ (1,0) [0|65535] "" Vector__XXX
 SG_ BckgndColourUserLayoutDataMask m196 : 8|8@1+ (1,0) [0|255] "" Vector__XXX
 SG_ NumberOfSupportedObjects m197 : 8|8@1+ (1,0) [0|255] "" Vector__XXX
 SG_ BootTime m199 : 8|8@1+ (1,0) [0|255] "s" Vector__XXX
 SG_ NumberOfAuxiliaryUnits m39 : 8|8@1+ (1,0) [0|255] "" Vector__XXX
 SG_ MacroObjectID_2 m188 : 8|16@1+ (1,0) [0|65535] "" Vector__XXX
 SG_ VTFunctionVTtoECU M : 0|8@1+ (1,0) [0|255] "" Vector__XXX

BO_ 2565799554 ACL_AuxInput: 8 AuxInput
 SG_ ArbitraryAddressCapable : 63|1@1+ (1,0) [0|1] "" Vector__XXX
 SG_ IndustryGroup M : 60|3@1+ (1,0) [0|7] "" Vector__XXX
 SG_ VehicleSystemInstance : 56|4@1+ (1,0) [0|15] "" Vector__XXX
 SG_ Function : 40|8@1+ (1,0) [0|255] "" Vector__XXX
 SG_ FunctionInstance : 35|5@1+ (1,0) [0|31] "" Vector__XXX
 SG_ ECUInstance : 32|3@1+ (1,0) [0|7] "" Vector__XXX
 SG_ ManufacturerCode : 21|11@1+ (1,0) [0|2047] "" Vector__XXX
 SG_ IdentityNumber : 0|21@1+ (1,0) [0|2097150] "" Vector__XXX
 SG_ VehicleSystem m0 : 49|7@1+ (1,0) [0|127] "" Vector__XXX
 SG_ VehicleSystem5 m5 : 49|7@1+ (1,0) [0|127] "" Vector__XXX
 SG_ VehicleSystem4 m4 : 49|7@1+ (1,0) [0|127] "" Vector__XXX
 SG_ VehicleSystem3 m3 : 49|7@1+ (1,0) [0|127] "" Vector__XXX
 SG_ VehicleSystem2 m2 : 49|7@1+ (1,0) [0|127] "" Vector__XXX
 SG_ VehicleSystem1 m1 : 49|7@1+ (1,0) [0|127] "" Vector__XXX

BO_ 2565340802 VT21_AuxInput: 8 AuxInput
 SG_ VTFunctionECUtoVT M : 0|8@1+ (1,0) [0|255] "" Vector__XXX
 SG_ KeyActivationCode m0 : 8|8@1+ (1,0) [0|2] "" Vector__XXX
 SG_ KeyObjectParentID m0 : 32|16@1+ (1,0) [0|65535] "" Vector__XXX
 SG_ KeyObjectID m0 : 16|16@1+ (1,0) [0|65535] "" Vector__XXX
 SG_ SoftKeyCode m0 : 48|8@1+ (1,0) [0|255] "" Vector__XXX
 SG_ ButtonActivationCode m1 : 8|8@1+ (1,0) [0|2] "" Vector__XXX
 SG_ ButtonObjectID m1 : 16|16@1+ (1,0) [0|65535] "" Vector__XXX
 SG_ ButtonObjectParentID m1 : 32|16@1+ (1,0) [0|65535] "" Vector__XXX
 SG_ ButtonKeyCode m1 : 48|8@1+ (1,0) [0|255] "" Vector__XXX
 SG_ XPosition m2 : 8|16@1+ (1,0) [0|65535] "" Vector__XXX
 SG_ YPosition m2 : 24|16@1+ (1,0) [0|65535] "" Vector__XXX
 SG_ TouchState m2 : 40|8@1+ (1,0) [0|255] "" Vector__XXX
 SG_ VTSelectInputObjectID m3 : 8|16@1+ (1,0) [0|65535] "" Vector__XXX
 SG_ VTSelectInputObjectStatus m3 : 24|8@1+ (1,0) [0|1] "" Vector__XXX
 SG_ VTEscObjectID m4 : 8|16@1+ (1,0) [0|65535] "" Vector__XXX
 SG_ VTChangeNumericValueObjectID m5 : 8|16@1+ (1,0) [0|65535] "" Vector__XXX
 SG_ VTChangeNumericValueValue m5 : 32|32@1+ (1,0) [0|4294967295] "" Vector__XXX
 SG_ VTChangeActiveMaskObjectID m6 : 8|16@1+ (1,0) [0|65535] "" Vector__XXX
 SG_ VTChangeSoftKeyMaskParentID m7 : 8|16@1+ (1,0) [0|65535] "" Vector__XXX
 SG_ VTChangeSoftKeyMaskObjectID m7 : 24|16@1+ (1,0) [0|65535] "" Vector__XXX
 SG_ ObjectToChangeStringValueID m8 : 24|16@1+ (1,0) [0|65535] "" Vector__XXX
 SG_ DisplayActivationStatus1 m9 : 8|1@1+ (1,0) [0|1] "" Vector__XXX
 SG_ VisibleDataAlarmMaskID m9 : 16|16@1+ (1,0) [0|65535] "" Vector__XXX
 SG_ VisibleSoftKeyMaskID m9 : 32|16@1+ (1,0) [0|65535] "" Vector__XXX
 SG_ ObjectPoolRecord m17 : 8|56@1+ (1,0) [0|3338120000] "" Vector__XXX
 SG_ AuxiliaryFunctionObjectID m32 : 8|16@1+ (1,0) [0|65535] "" Vector__XXX
 SG_ AssignmentErrorNotAccepted m32 : 24|1@1+ (1,0) [0|1] "" Vector__XXX
 SG_ NumberOfInpuUnits m34 : 8|8@1+ (1,0) [0|255] "" Vector__XXX
 SG_ IsEnabled m33 : 48|8@1+ (1,0) [0|255] "" Vector__XXX
 SG_ AuxModelIdentification m35 : 8|16@1+ (1,0) [0|65535] "" Vector__XXX
 SG_ InputStatusObjectId m37 : 8|16@1+ (1,0) [0|255] "" Vector__XXX
 SG_ AuxInputEnable m37 : 24|8@1+ (1,0) [0|1] "" Vector__XXX
 SG_ AuxErrorInvalidInputID m37 : 32|1@1+ (1,0) [0|1] "" Vector__XXX
 SG_ AuxErrorAnyOther m37 : 33|1@1+ (1,0) [0|1] "" Vector__XXX
 SG_ ObjectToShowHideID m160 : 8|16@1+ (1,0) [0|65535] "" Vector__XXX
 SG_ ShowOrHide m160 : 24|8@1+ (1,0) [0|1] "" Vector__XXX
 SG_ ObjectoEnableDisbaleID m161 : 8|16@1+ (1,0) [0|65535] "" Vector__XXX
 SG_ EnableOrDisable m161 : 24|8@1+ (1,0) [0|1] "" Vector__XXX
 SG_ SelectInputObjectID m162 : 8|16@1+ (1,0) [0|65535] "" Vector__XXX
 SG_ SetFocusOpenForEditing m162 : 24|8@1+ (1,0) [0|255] "" Vector__XXX
 SG_ NumberOfRepetitions_Audio m163 : 8|8@1+ (1,0) [0|255] "" Vector__XXX
 SG_ Frequency_Audio m163 : 16|16@1+ (1,0) [0|65535] "hz" Vector__XXX
 SG_ OnTimeDuration_Audio m163 : 32|16@1+ (1,0) [0|65535] "ms" Vector__XXX
 SG_ OffTimeDuration_Audio m163 : 48|16@1+ (1,0) [0|65535] "ms" Vector__XXX
 SG_ AudioVolume m164 : 8|8@1+ (1,0) [0|100] "%" Vector__XXX
 SG_ ParentObjectID m165 : 8|16@1+ (1,0) [0|65535] "" Vector__XXX
 SG_ ObjectToMoveID m165 : 24|16@1+ (1,0) [0|65535] "" Vector__XXX
 SG_ XPosChangeTopLeft m165 : 40|8@1+ (1,-127) [-127|128] "" Vector__XXX
 SG_ YPosChangeTopLeft m165 : 48|8@1+ (1,-127) [-127|128] "" Vector__XXX
 SG_ ObjectToSizeID m166 : 8|16@1+ (1,0) [0|65535] "" Vector__XXX
 SG_ NewWidth m166 : 24|16@1+ (1,0) [0|65535] "" Vector__XXX
 SG_ NewHeight m166 : 40|16@1+ (1,0) [0|65535] "" Vector__XXX
 SG_ ObjectToChangeColourID m167 : 8|16@1+ (1,0) [0|65535] "" Vector__XXX
 SG_ NewBackgroundColour m167 : 24|8@1+ (1,0) [0|255] "" Vector__XXX
 SG_ ObjectToChangeNumValueID m168 : 8|16@1+ (1,0) [0|65535] "" Vector__XXX
 SG_ NewValue m168 : 32|32@1+ (1,0) [0|65535] "" Vector__XXX
 SG_ ObjectToChangeEndPointID m169 : 8|16@1+ (1,0) [0|65535] "" Vector__XXX
 SG_ Width m169 : 24|16@1+ (1,0) [0|65535] "" Vector__XXX
 SG_ Height m169 : 40|16@1+ (1,0) [0|65535] "" Vector__XXX
 SG_ LineDirection m169 : 56|8@1+ (1,0) [0|1] "" Vector__XXX
 SG_ ObjectToChangeFontID m170 : 8|16@1+ (1,0) [0|65535] "" Vector__XXX
 SG_ FontColour m170 : 24|8@1+ (1,0) [0|255] "" Vector__XXX
 SG_ FontSize m170 : 32|8@1+ (1,0) [0|255] "" Vector__XXX
 SG_ FontType m170 : 40|8@1+ (1,0) [0|255] "" Vector__XXX
 SG_ FontStyle m170 : 48|8@1+ (1,0) [0|255] "" Vector__XXX
 SG_ ObjectToChangeLineAttributesID m171 : 8|16@1+ (1,0) [0|65535] "" Vector__XXX
 SG_ LineColour m171 : 24|8@1+ (1,0) [0|255] "" Vector__XXX
 SG_ LineWidth m171 : 32|8@1+ (1,0) [0|255] "" Vector__XXX
 SG_ LineArt m171 : 40|16@1+ (1,0) [0|65535] "" Vector__XXX
 SG_ ObjectToChangeFillAttributesID m172 : 8|16@1+ (1,0) [0|65535] "" Vector__XXX
 SG_ FillType m172 : 24|8@1+ (1,0) [0|255] "" Vector__XXX
 SG_ FillColour m172 : 32|8@1+ (1,0) [0|255] "" Vector__XXX
 SG_ FillPatternObjectID m172 : 40|16@1+ (1,0) [0|65535] "" Vector__XXX
 SG_ WorkingSetObjectID m173 : 8|16@1+ (1,0) [0|65535] "" Vector__XXX
 SG_ NewActiveMaskObjectID m173 : 24|16@1+ (1,0) [0|65535] "" Vector__XXX
 SG_ MaskType m174 : 8|8@1+ (1,0) [0|255] "" Vector__XXX
 SG_ DataOrAlarmMaskObjectID m174 : 16|16@1+ (1,0) [0|65535] "" Vector__XXX
 SG_ NewSoftKeyMaskObjectID m174 : 32|16@1+ (1,0) [0|65535] "" Vector__XXX
 SG_ ObjectToChangeAttributeID m175 : 8|16@1+ (1,0) [0|65535] "" Vector__XXX
 SG_ AttributeID m175 : 24|8@1+ (1,0) [0|16777200] "" Vector__XXX
 SG_ NewAttributeValue m175 : 32|32@1+ (1,0) [0|0] "" Vector__XXX
 SG_ AlarmMaskObjectID m176 : 8|16@1+ (1,0) [0|65535] "" Vector__XXX
 SG_ NewPriority m176 : 24|8@1+ (1,0) [0|255] "" Vector__XXX
 SG_ ListInputObjectID m177 : 8|16@1+ (1,0) [0|65535] "" Vector__XXX
 SG_ ListIndex m177 : 24|8@1+ (1,0) [0|255] "" Vector__XXX
 SG_ NewObjectID m177 : 32|16@1+ (1,0) [0|65535] "" Vector__XXX
 SG_ ObjectToChangeStringValueID m179 : 8|16@1+ (1,0) [0|65535] "" Vector__XXX
 SG_ NewStringValue m179 : 24|16@1+ (1,0) [0|65535] "" Vector__XXX
 SG_ ParentObjectID m180 : 8|16@1+ (1,0) [0|65535] "" Vector__XXX
 SG_ ObjectToMoveID m180 : 24|16@1+ (1,0) [0|65535] "" Vector__XXX
 SG_ XPosChangeTopLeftLong m180 : 40|16@1- (1,0) [-32768|32767] "" Vector__XXX
 SG_ YPosChangeTopLeftLong m180 : 56|16@1- (1,0) [-32768|32767] "" Vector__XXX
 SG_ ObjectToAssociateLabelWithID m181 : 8|16@1+ (1,0) [0|65535] "" Vector__XXX
 SG_ StringVariableObjectID m181 : 24|16@1+ (1,0) [0|65535] "" Vector__XXX
 SG_ GraphicRepresentationObjectID m181 : 48|16@1+ (1,0) [0|255] "" Vector__XXX
 SG_ FontType m181 : 40|8@1+ (1,0) [0|255] "" Vector__XXX
 SG_ PolygonObjectToChangeID m182 : 8|16@1+ (1,0) [0|65535] "" Vector__XXX
 SG_ IndexOfThePointToReplace m182 : 24|8@1+ (1,0) [0|255] "" Vector__XXX
 SG_ NewValueX m182 : 32|16@1+ (1,0) [0|65535] "" Vector__XXX
 SG_ NewValueY m182 : 48|16@1+ (1,0) [0|65535] "" Vector__XXX
 SG_ PolygonObjectToScaleID m183 : 8|16@1+ (1,0) [0|65535] "" Vector__XXX
 SG_ NewWidthAttribute m183 : 24|16@1+ (1,0) [0|65535] "" Vector__XXX
 SG_ NewHeigthAttribute m183 : 40|16@1+ (1,0) [0|0] "" Vector__XXX
 SG_ GraphicsContextObjectID m184 : 8|16@1+ (1,0) [0|65535] "" Vector__XXX
 SG_ SubCommandID m184 : 24|8@1+ (1,0) [0|0] "" Vector__XXX
 SG_ ObjectToGetAttributeID m185 : 8|16@1+ (1,0) [0|65535] "" Vector__XXX
 SG_ AttributeID m185 : 24|8@1+ (1,0) [0|0] "" Vector__XXX
 SG_ ColourMapObjectID m186 : 8|16@1+ (1,0) [0|65535] "" Vector__XXX
 SG_ LockUnlockCommand m189 : 8|8@1+ (1,0) [0|1] "" Vector__XXX
 SG_ ObjectIDOfDataMaskToLock m189 : 16|16@1+ (1,0) [0|65535] "" Vector__XXX
 SG_ LockTimeout m189 : 32|16@1+ (1,0) [0|65535] "" Vector__XXX
 SG_ MacroObjecID m190 : 8|8@1+ (1,0) [0|255] "" Vector__XXX
 SG_ MemoryRequired m192 : 16|24@1+ (1,0) [0|16777200] "" Vector__XXX
 SG_ CodePlane m193 : 8|8@1+ (1,0) [0|16] "" Vector__XXX
 SG_ FirstWideChar m193 : 16|16@1+ (1,0) [0|65535] "" Vector__XXX
 SG_ LastWideChar m193 : 32|16@1+ (1,0) [0|65535] "" Vector__XXX
 SG_ VersionLabelToStore m208 : 8|56@1+ (1,0) [0|3338120000] "" Vector__XXX
 SG_ VersionLabelToLoad m209 : 8|56@1+ (1,0) [0|3338120000] "" Vector__XXX
 SG_ VersionLabelToDelete m210 : 8|56@1+ (1,0) [0|3338120000] "" Vector__XXX
 SG_ WSMaintenanceInitiating m255 : 8|1@1+ (1,0) [0|1] "" Vector__XXX
 SG_ WSMaintenanceBitmask m255 : 15|1@1+ (1,0) [0|1] "" Vector__XXX

BO_ 2314732286 COGSOGRapidUpdate: 8 Vector__XXX
 SG_ SpeedOverGround : 32|16@1+ (0.01,0) [0|655.35] "m/s" Vector__XXX
 SG_ CourseOverGround : 16|16@1+ (0.005729577,0) [0|0] "deg" Vector__XXX
 SG_ COGReference : 8|2@1+ (1,0) [0|3] "" Vector__XXX
 SG_ SequenceID : 0|8@1+ (1,0) [0|255] "" Vector__XXX

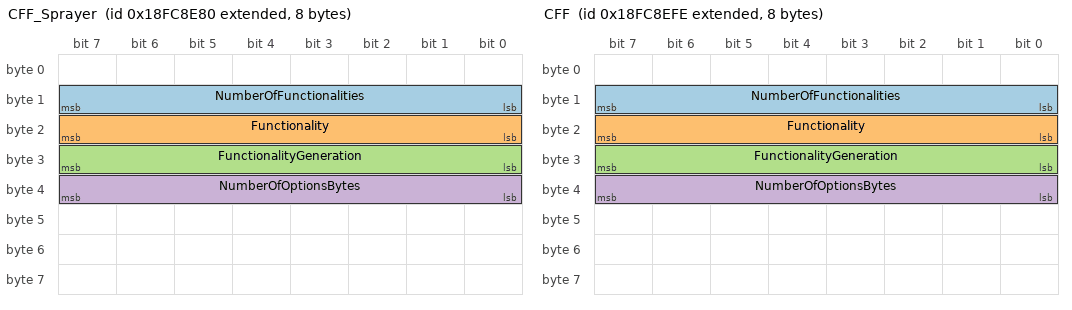
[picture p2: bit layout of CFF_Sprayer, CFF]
BO_ 2566688384 CFF_Sprayer: 8 Sprayer
 SG_ NumberOfFunctionalities : 8|8@1- (1,0) [1|255] "" Vector__XXX
 SG_ Functionality : 16|8@1- (1,0) [0|255] "" Vector__XXX
 SG_ FunctionalityGeneration : 24|8@1- (1,0) [1|255] "" Vector__XXX
 SG_ NumberOfOptionsBytes : 32|8@1- (1,0) [0|255] "" Vector__XXX

BO_ 2566688510 CFF: 8 Vector__XXX
 SG_ NumberOfFunctionalities : 8|8@1- (1,0) [1|255] "" Vector__XXX
 SG_ Functionality : 16|8@1- (1,0) [0|255] "" Vector__XXX
 SG_ FunctionalityGeneration : 24|8@1- (1,0) [1|255] "" Vector__XXX
 SG_ NumberOfOptionsBytes : 32|8@1- (1,0) [0|255] "" Vector__XXX

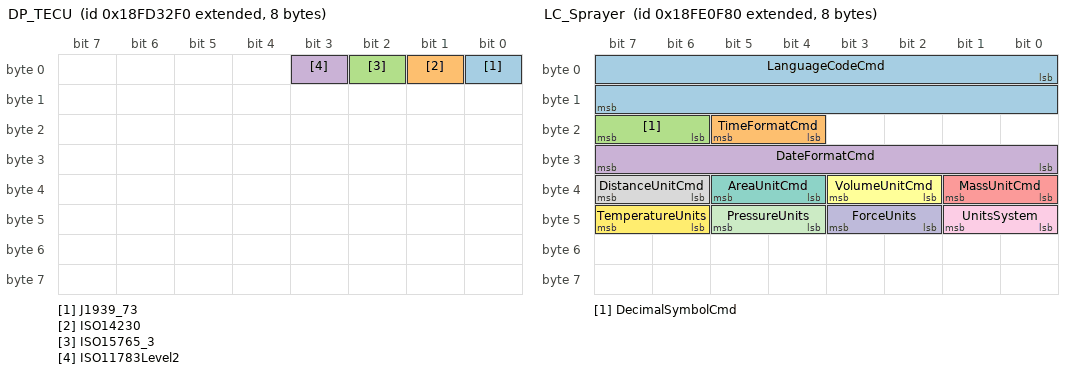
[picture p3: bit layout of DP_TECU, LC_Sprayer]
BO_ 2566730480 DP_TECU: 8 TECU
 SG_ J1939_73 : 0|1@1+ (1,0) [0|1] "" Vector__XXX
 SG_ ISO14230 : 1|1@1+ (1,0) [0|1] "" Vector__XXX
 SG_ ISO15765_3 : 2|1@1+ (1,0) [0|1] "" Vector__XXX
 SG_ ISO11783Level2 : 3|1@1+ (1,0) [0|1] "" Vector__XXX

BO_ 2566839024 SOFT_TECU: 1700 TECU
 SG_ SoftwareID3 : 24|8@1+ (1,0) [0|255] "" Vector__XXX
 SG_ SoftwareID2 : 16|8@1+ (1,0) [0|255] "" Vector__XXX
 SG_ SoftwareID1 : 8|8@1+ (1,0) [0|255] "" Vector__XXX
 SG_ NmbrOfSftwrIdentificationFields : 0|8@1+ (1,0) [0|250] "steps" Vector__XXX

BO_ 2566768112 ECUID_TECU: 1024 TECU
 SG_ ECUHardwareID : 40|8@1+ (1,0) [0|255] "" Vector__XXX
 SG_ ECUManufacturerName : 32|8@1+ (1,0) [0|255] "" Vector__XXX
 SG_ ECUType : 24|8@1+ (1,0) [0|255] "" Vector__XXX
 SG_ ECULocation : 16|8@1+ (1,0) [0|255] "" Vector__XXX
 SG_ ECUSerialNumber : 8|8@1+ (1,0) [0|255] "" Vector__XXX
 SG_ ECUPartNumber : 0|8@1+ (1,0) [0|255] "" Vector__XXX

BO_ 2566786944 LC_Sprayer: 8 Sprayer
 SG_ LanguageCodeCmd : 0|16@1+ (1,0) [0|16383] "" Vector__XXX
 SG_ TimeFormatCmd : 20|2@1+ (1,0) [0|3] "" Vector__XXX
 SG_ DecimalSymbolCmd : 22|2@1+ (1,0) [0|3] "" Vector__XXX
 SG_ DateFormatCmd : 24|8@1+ (1,0) [0|255] "" Vector__XXX
 SG_ MassUnitCmd : 32|2@1+ (1,0) [0|3] "" Vector__XXX
 SG_ VolumeUnitCmd : 34|2@1+ (1,0) [0|3] "" Vector__XXX
 SG_ AreaUnitCmd : 36|2@1+ (1,0) [0|3] "" Vector__XXX
 SG_ DistanceUnitCmd : 38|2@1+ (1,0) [0|3] "" Vector__XXX
 SG_ UnitsSystem : 40|2@1+ (1,0) [0|3] "" Vector__XXX
 SG_ ForceUnits : 42|2@1+ (1,0) [0|3] "" Vector__XXX
 SG_ PressureUnits : 44|2@1+ (1,0) [0|3] "" Vector__XXX
 SG_ TemperatureUnits : 46|2@1+ (1,0) [0|3] "" Vector__XXX

BO_ 2566843632 VI_TECU: 200 TECU
 SG_ VehicleIdentificationNumber : 0|8@1+ (1,0) [0|255] "" Vector__XXX

BO_ 2566843520 VI_Sprayer: 200 Sprayer
 SG_ VehicleIdentificationNumber : 0|8@1+ (1,0) [0|255] "" Vector__XXX

BO_ 2566835328 DM3_Sprayer: 0 Sprayer

BO_ 2566835072 DM2_Sprayer: 22 Sprayer
 SG_ DTC5 : 144|32@1+ (1,0) [0|4294967295] "" Vector__XXX
 SG_ DTC4 : 112|32@1+ (1,0) [0|4294967295] "" Vector__XXX
 SG_ DTC3 : 80|32@1+ (1,0) [0|4294967295] "" Vector__XXX
 SG_ DTC2 : 48|32@1+ (1,0) [0|4294967295] "" Vector__XXX
 SG_ DTC1 : 16|32@1+ (1,0) [0|4294967295] "" Vector__XXX
 SG_ MalfunctionIndicatorLampStatus : 6|2@1+ (1,0) [0|3] "" Vector__XXX
 SG_ RedStopLampState : 4|2@1+ (1,0) [0|3] "" Vector__XXX
 SG_ AmberWarningLampStatus : 2|2@1+ (1,0) [0|3] "" Vector__XXX
 SG_ ProtectLampStatus : 0|2@1+ (1,0) [0|3] "" Vector__XXX
 SG_ FlashRedStopLamp : 12|2@1+ (1,0) [0|3] "" Vector__XXX
 SG_ FlashProtectLamp : 8|2@1+ (1,0) [0|3] "" Vector__XXX
 SG_ FlashMalfuncIndicatorLamp : 14|2@1+ (1,0) [0|3] "" Vector__XXX
 SG_ FlashAmberWarningLamp : 10|2@1+ (1,0) [0|3] "" Vector__XXX

BO_ 2566834816 DM1_Sprayer: 22 Sprayer
 SG_ DTC5 : 144|32@1+ (1,0) [0|4294967295] "" Vector__XXX
 SG_ DTC4 : 112|32@1+ (1,0) [0|4294967295] "" Vector__XXX
 SG_ DTC3 : 80|32@1+ (1,0) [0|4294967295] "" Vector__XXX
 SG_ DTC2 : 48|32@1+ (1,0) [0|4294967295] "" Vector__XXX
 SG_ DTC1 : 16|32@1+ (1,0) [0|4294967295] "" Vector__XXX
 SG_ FlashRedStopLamp : 12|2@1+ (1,0) [0|3] "" Vector__XXX
 SG_ FlashProtectLamp : 8|2@1+ (1,0) [0|3] "" Vector__XXX
 SG_ FlashMalfuncIndicatorLamp : 14|2@1+ (1,0) [0|3] "" Vector__XXX
 SG_ FlashAmberWarningLamp : 10|2@1+ (1,0) [0|3] "" Vector__XXX
 SG_ MalfunctionIndicatorLampStatus : 6|2@1+ (1,0) [0|3] "" Vector__XXX
 SG_ AmberWarningLampStatus : 2|2@1+ (1,0) [0|3] "" Vector__XXX
 SG_ RedStopLampState : 4|2@1+ (1,0) [0|3] "" Vector__XXX
 SG_ ProtectLampStatus : 0|2@1+ (1,0) [0|3] "" Vector__XXX

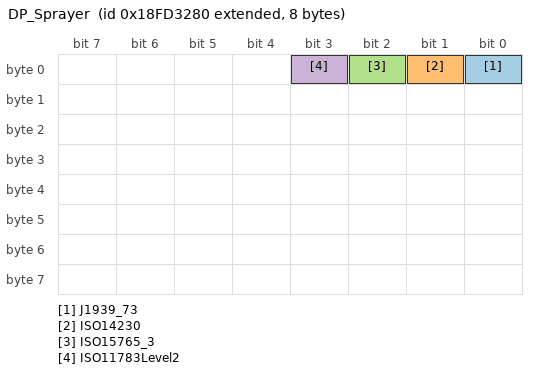
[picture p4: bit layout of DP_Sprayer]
BO_ 2566730368 DP_Sprayer: 8 Sprayer
 SG_ J1939_73 : 0|1@1+ (1,0) [0|1] "" Vector__XXX
 SG_ ISO14230 : 1|1@1+ (1,0) [0|1] "" Vector__XXX
 SG_ ISO15765_3 : 2|1@1+ (1,0) [0|1] "" Vector__XXX
 SG_ ISO11783Level2 : 3|1@1+ (1,0) [0|1] "" Vector__XXX

BO_ 2566838912 SOFT_Sprayer: 1700 Sprayer
 SG_ SoftwareID3 : 24|8@1+ (1,0) [0|255] "" Vector__XXX
 SG_ SoftwareID2 : 16|8@1+ (1,0) [0|255] "" Vector__XXX
 SG_ SoftwareID1 : 8|8@1+ (1,0) [0|255] "" Vector__XXX
 SG_ NmbrOfSftwrIdentificationFields : 0|8@1+ (1,0) [0|250] "steps" Vector__XXX

BO_ 2566768000 ECUID_Sprayer: 1024 Sprayer
 SG_ ECUHardwareID : 40|8@1+ (1,0) [0|255] "" Vector__XXX
 SG_ ECUManufacturerName : 32|8@1+ (1,0) [0|255] "" Vector__XXX
 SG_ ECUType : 24|8@1+ (1,0) [0|255] "" Vector__XXX
 SG_ ECULocation : 16|8@1+ (1,0) [0|255] "" Vector__XXX
 SG_ ECUSerialNumber : 8|8@1+ (1,0) [0|255] "" Vector__XXX
 SG_ ECUPartNumber : 0|8@1+ (1,0) [0|255] "" Vector__XXX

BO_ 2566835440 DM3_TECU: 0 TECU

BO_ 2566835184 DM2_TECU: 22 TECU
 SG_ DTC5 : 144|32@1+ (1,0) [0|4294967295] "" Vector__XXX
 SG_ DTC4 : 112|32@1+ (1,0) [0|4294967295] "" Vector__XXX
 SG_ DTC3 : 80|32@1+ (1,0) [0|4294967295] "" Vector__XXX
 SG_ DTC2 : 48|32@1+ (1,0) [0|4294967295] "" Vector__XXX
 SG_ DTC1 : 16|32@1+ (1,0) [0|4294967295] "" Vector__XXX
 SG_ MalfunctionIndicatorLampStatus : 6|2@1+ (1,0) [0|3] "" Vector__XXX
 SG_ RedStopLampState : 4|2@1+ (1,0) [0|3] "" Vector__XXX
 SG_ AmberWarningLampStatus : 2|2@1+ (1,0) [0|3] "" Vector__XXX
 SG_ ProtectLampStatus : 0|2@1+ (1,0) [0|3] "" Vector__XXX
 SG_ FlashRedStopLamp : 12|2@1+ (1,0) [0|3] "" Vector__XXX
 SG_ FlashProtectLamp : 8|2@1+ (1,0) [0|3] "" Vector__XXX
 SG_ FlashMalfuncIndicatorLamp : 14|2@1+ (1,0) [0|3] "" Vector__XXX
 SG_ FlashAmberWarningLamp : 10|2@1+ (1,0) [0|3] "" Vector__XXX

BO_ 2566834928 DM1_TECU: 22 TECU
 SG_ DTC5 : 144|32@1+ (1,0) [0|4294967295] "" Vector__XXX
 SG_ DTC4 : 112|32@1+ (1,0) [0|4294967295] "" Vector__XXX
 SG_ DTC3 : 80|32@1+ (1,0) [0|4294967295] "" Vector__XXX
 SG_ DTC2 : 48|32@1+ (1,0) [0|4294967295] "" Vector__XXX
 SG_ DTC1 : 16|32@1+ (1,0) [0|4294967295] "" Vector__XXX
 SG_ FlashRedStopLamp : 12|2@1+ (1,0) [0|3] "" Vector__XXX
 SG_ FlashProtectLamp : 8|2@1+ (1,0) [0|3] "" Vector__XXX
 SG_ FlashMalfuncIndicatorLamp : 14|2@1+ (1,0) [0|3] "" Vector__XXX
 SG_ FlashAmberWarningLamp : 10|2@1+ (1,0) [0|3] "" Vector__XXX
 SG_ MalfunctionIndicatorLampStatus : 6|2@1+ (1,0) [0|3] "" Vector__XXX
 SG_ AmberWarningLampStatus : 2|2@1+ (1,0) [0|3] "" Vector__XXX
 SG_ RedStopLampState : 4|2@1+ (1,0) [0|3] "" Vector__XXX
 SG_ ProtectLampStatus : 0|2@1+ (1,0) [0|3] "" Vector__XXX

CM_ BU_ AuxInput "Auxiliary Key Input";
CM_ BU_ VT "Virtual Terminal";
CM_ BU_ TECU "Tractor ECU";
CM_ BU_ TC "Task Controller";
CM_ BU_ Sprayer "Sprayer Implement";
CM_ BU_ GPS "GPS Receiver";
CM_ BO_ 3221225472 "This is a message for not used signals, created by Vector CANdb++ DBC OLE DB Provider.";
CM_ SG_ 3221225472 CertificationYear "ISOBUS compliance certification yearISOBUS compliance certification yearISOBUS compliance certification year";
CM_ SG_ 3221225472 CertificateRevision "ISOBUS compliance certificate revisionISOBUS compliance certificate revisionISOBUS compliance certificate revision";
CM_ SG_ 3221225472 CertificateLaboratoryType "ISOBUS compliance certificate laboratory typeISOBUS compliance certificate laboratory typeISOBUS compliance certificate laboratory type";
CM_ SG_ 3221225472 CertificationLaboratoryID "ISOBUS Compliance certification laboratory IDISOBUS Compliance certification laboratory ID";
CM_ SG_ 3221225472 CertTypeVTWorkingSetMember "ISOBUS Compliance certification type - VT working set memberISOBUS Compliance certification type - VT working set member";
CM_ SG_ 3221225472 CertTypeVTWorkingSetMaster "ISOBUS Compliance certification type - VT working set masterISOBUS Compliance certification type - VT working set master";
CM_ SG_ 3221225472 CertTypeVirtualTerminal "ISOBUS Compliance certification type - Virtual terminalISOBUS Compliance certification type - Virtual terminal";
CM_ SG_ 3221225472 CertTypeClass3ECU "ISOBUS Compliance certification type - Class 3 ECUISOBUS Compliance certification type - Class 3 ECU";
CM_ SG_ 3221225472 CertTypeTECUClass3 "ISOBUS Compliance certification type - TECU Class 3ISOBUS Compliance certification type - TECU Class 3";
CM_ SG_ 3221225472 CertTypeTECUClass2 "ISOBUS Compliance certification type - TECU Class 2ISOBUS Compliance certification type - TECU Class 2";
CM_ SG_ 3221225472 CertTypeTECUClass1 "ISOBUS Compliance certification type - TECU Class 1ISOBUS Compliance certification type - TECU Class 1";
CM_ SG_ 3221225472 CertTypeMinimumECU "ISOBUS Compliance certification type - Minimum ECUISOBUS Compliance certification type - Minimum ECU";
CM_ SG_ 3221225472 CertTypeGPSReceiver "ISOBUS Compliance certification type - GPS receiverISOBUS Compliance certification type - GPS receiver";
CM_ SG_ 3221225472 CertTypeFileServer "ISOBUS Compliance certification type - File serverISOBUS Compliance certification type - File server";
CM_ SG_ 3221225472 CertTypeTCWorkingSetMember "ISOBUS Compliance certification type - TC working set memberISOBUS Compliance certification type - TC working set member";
CM_ SG_ 3221225472 CertTypeTCWorkingSetMaster "ISOBUS Compliance certification type - TC working set masterISOBUS Compliance certification type - TC working set master";
CM_ SG_ 3221225472 CertTypeTaskController "ISOBUS Compliance certification type - Task ControllerISOBUS Compliance certification type - Task Controller";
CM_ SG_ 3221225472 CertificationReferenceNumber "ISOBUS Compliance certification reference numberISOBUS Compliance certification reference number";
CM_ BO_ 2566688240 "Product Identification Information: Each control function of a product shall respond with the same product identification information when it 
receives the Request PGN message for this PGN.";
CM_ SG_ 2566688240 ProductIdentificationCode "The Product Identification Code as assigned by the manufacturer correspondents with the number on the type 
plate of a product.";
CM_ SG_ 2566688240 ProductIdentificationBrand "Specifies  the  brand  of  a  product.  
The  combination  of  the  Product Identification Code and the Product Identification Brand shall make the product unique in the world.";
CM_ SG_ 2566688240 ProductIdentificationModel "The Product Identification Model specifies a unique product within a Brand. ";
CM_ BO_ 2566688128 "Product Identification Information: Each control function of a product shall respond with the same product identification information when it 
receives the Request PGN message for this PGN.";
CM_ SG_ 2566688128 ProductIdentificationCode "The Product Identification Code as assigned by the manufacturer correspondents with the number on the type 
plate of a product.";
CM_ SG_ 2566688128 ProductIdentificationBrand "Specifies  the  brand  of  a  product.  
The  combination  of  the  Product Identification Code and the Product Identification Brand shall make the product unique in the world.";
CM_ SG_ 2566688128 ProductIdentificationModel "The Product Identification Model specifies a unique product within a Brand. ";
CM_ BO_ 2566688254 "Product Identification Information: Each control function of a product shall respond with the same product identification information when it 
receives the Request PGN message for this PGN.";
CM_ SG_ 2566688254 ProductIdentificationCode "The Product Identification Code as assigned by the manufacturer correspondents with the number on the type 
plate of a product.";
CM_ SG_ 2566688254 ProductIdentificationBrand "Specifies  the  brand  of  a  product.  
The  combination  of  the  Product Identification Code and the Product Identification Brand shall make the product unique in the world.";
CM_ SG_ 2566688254 ProductIdentificationModel "The Product Identification Model specifies a unique product within a Brand. ";
CM_ BO_ 2566734464 "ISOBUS compliance certification";
CM_ SG_ 2566734464 CertLaboratoryType_FirstDef "Approving body for the certification laboratory.";
CM_ SG_ 2566734464 MessageRevision "This parameter distinguishes the format of the ISOBUS Compliance Certification message in the second 
edition from the format in the third and later editions.";
CM_ SG_ 2566734464 CertLaboratoryType_SecondDef "Approving body for the certification laboratory.";
CM_ SG_ 2566734464 TestProtocolRevision "ISOBUS compliance certificate revision";
CM_ SG_ 2566734464 TestProtocolPublicationYear "ISOBUS compliance certification year";
CM_ SG_ 2566734464 CertificationLaboratoryID "ISOBUS Compliance certification laboratory ID";
CM_ SG_ 2566734464 CertTypeVTWorkingSetMember "ISOBUS Compliance certification type - VT working set member";
CM_ SG_ 2566734464 CertTypeVTWorkingSetMaster "ISOBUS Compliance certification type - VT working set master";
CM_ SG_ 2566734464 CertTypeVirtualTerminal "ISOBUS Compliance certification type - Virtual terminal";
CM_ SG_ 2566734464 CertTypeClass3ECU "ISOBUS Compliance certification type - Class 3 ECU";
CM_ SG_ 2566734464 CertTypeTECUClass3 "ISOBUS Compliance certification type - TECU Class 3";
CM_ SG_ 2566734464 CertTypeTECUClass2 "ISOBUS Compliance certification type - TECU Class 2";
CM_ SG_ 2566734464 CertTypeTECUClass1 "ISOBUS Compliance certification type - TECU Class 1";
CM_ SG_ 2566734464 CertTypeMinimumECU "ISOBUS Compliance certification type - Minimum ECU";
CM_ SG_ 2566734464 CertTypeGPSReceiver "ISOBUS Compliance certification type - GPS receiver";
CM_ SG_ 2566734464 CertTypeFileServer "ISOBUS Compliance certification type - File server";
CM_ SG_ 2566734464 CertTypeTCWorkingSetMember "ISOBUS Compliance certification type - TC working set member";
CM_ SG_ 2566734464 CertTypeTCWorkingSetMaster "ISOBUS Compliance certification type - TC working set master";
CM_ SG_ 2566734464 CertTypeTaskController "ISOBUS Compliance certification type - Task Controller";
CM_ SG_ 2566734464 CertificationReferenceNumber "ISOBUS Compliance certification reference number";
CM_ BO_ 2566734576 "ISOBUS compliance certification";
CM_ SG_ 2566734576 CertLaboratoryType_FirstDef "Approving body for the certification laboratory.";
CM_ SG_ 2566734576 MessageRevision "This parameter distinguishes the format of the ISOBUS Compliance Certification message in the second 
edition from the format in the third and later editions.";
CM_ SG_ 2566734576 CertLaboratoryType_SecondDef "Approving body for the certification laboratory.";
CM_ SG_ 2566734576 TestProtocolRevision "ISOBUS compliance certificate revision";
CM_ SG_ 2566734576 TestProtocolPublicationYear "ISOBUS compliance certification year";
CM_ SG_ 2566734576 CertificationLaboratoryID "ISOBUS Compliance certification laboratory ID";
CM_ SG_ 2566734576 CertTypeVTWorkingSetMember "ISOBUS Compliance certification type - VT working set member";
CM_ SG_ 2566734576 CertTypeVTWorkingSetMaster "ISOBUS Compliance certification type - VT working set master";
CM_ SG_ 2566734576 CertTypeVirtualTerminal "ISOBUS Compliance certification type - Virtual terminal";
CM_ SG_ 2566734576 CertTypeClass3ECU "ISOBUS Compliance certification type - Class 3 ECU";
CM_ SG_ 2566734576 CertTypeTECUClass3 "ISOBUS Compliance certification type - TECU Class 3";
CM_ SG_ 2566734576 CertTypeTECUClass2 "ISOBUS Compliance certification type - TECU Class 2";
CM_ SG_ 2566734576 CertTypeTECUClass1 "ISOBUS Compliance certification type - TECU Class 1";
CM_ SG_ 2566734576 CertTypeMinimumECU "ISOBUS Compliance certification type - Minimum ECU";
CM_ SG_ 2566734576 CertTypeGPSReceiver "ISOBUS Compliance certification type - GPS receiver";
CM_ SG_ 2566734576 CertTypeFileServer "ISOBUS Compliance certification type - File server";
CM_ SG_ 2566734576 CertTypeTCWorkingSetMember "ISOBUS Compliance certification type - TC working set member";
CM_ SG_ 2566734576 CertTypeTCWorkingSetMaster "ISOBUS Compliance certification type - TC working set master";
CM_ SG_ 2566734576 CertTypeTaskController "ISOBUS Compliance certification type - Task Controller";
CM_ SG_ 2566734576 CertificationReferenceNumber "ISOBUS Compliance certification reference number";
CM_ BO_ 2365391614 " All implements stop operations switch state";
CM_ SG_ 2365391614 StopAllImplOpTransitionNum "This parameter indicates the number of transitions from Permit (01) to Stop (00) since power up of 
the Stop all implement operations parameter. The parameter resets to zero on the next transition after 
reporting the maximum value.";
CM_ BO_ 2632384130 "VT to ECU";
CM_ SG_ 2632384130 AuxiliaryFunctionType "Auxiliary function type of assigned auxiliary input";
CM_ SG_ 2632384130 VTChangeActiveMaskParentID "Parent object ID of error object ID";
CM_ SG_ 2632384130 VTChangeActiveMaskErrorID "Object ID containing error";
CM_ SG_ 2632384130 NumTransitionsDisabledToEnabled "Number of transitions of disabled to enabled";
CM_ SG_ 2632384130 ErrorCodePoolDeleted "VT change mask error code: Pool being deleted";
CM_ SG_ 2632384130 ErrorCodeAnyOtherError "VT change mask error code: Any other error";
CM_ SG_ 2632384130 AuxInputEnable "Auxiliary Input Enable";
CM_ SG_ 2632384130 AnalogValue "Analog value of 0xFFFF if input type is boolean";
CM_ BO_ 2565799554 "Address Claimed";
CM_ BO_ 2565340802 "ECU to VT";
CM_ SG_ 2565340802 AuxModelIdentification "Model Identification Code of the Auxiliary Input Unit";
CM_ SG_ 2565340802 AuxInputEnable "Auxiliary Input Enable";
CM_ SG_ 2565340802 AuxErrorInvalidInputID "Invalid Auxiliary Input Object ID";
CM_ SG_ 2565340802 AuxErrorAnyOther "Any other error";
CM_ BO_ 2314732286 "Course Over Ground (COG) and Speed Over Ground (SOG).";
CM_ SG_ 2314732286 CourseOverGround "The direction of the path over ground actually followed by a vessel.";
CM_ BO_ 2566688384 "This message identifies all the functionalities, functionality generation and functionality options, supported by 
control functions.";
CM_ SG_ 2566688384 Functionality "This parameter reports which functionalities are supported by a control function connected to the ISO 11783 
network. ";
CM_ SG_ 2566688384 FunctionalityGeneration "This parameter reports the generation of the functionality provided by a control function connected to the ISO 11783 network.";
CM_ SG_ 2566688384 NumberOfOptionsBytes "This parameter reports the number of bytes that follow to report which options are supported by a functionality 
provided  by  a  control  function  connected  to  the  ISO  11783  network.";
CM_ BO_ 2566688510 "This message identifies all the functionalities, functionality generation and functionality options, supported by 
control functions.";
CM_ SG_ 2566688510 Functionality "This parameter reports which functionalities are supported by a control function connected to the ISO 11783 
network. ";
CM_ SG_ 2566688510 FunctionalityGeneration "This parameter reports the generation of the functionality provided by a control function connected to the ISO 11783 network.";
CM_ SG_ 2566688510 NumberOfOptionsBytes "This parameter reports the number of bytes that follow to report which options are supported by a functionality 
provided  by  a  control  function  connected  to  the  ISO  11783  network.";
CM_ BO_ 2566730480 "ECU diagnostic protocol";
CM_ SG_ 2566730480 J1939_73 "J1939-73";
CM_ SG_ 2566730480 ISO14230 "ISO 14230 (KWP 2000 over K line)";
CM_ SG_ 2566730480 ISO15765_3 "ISO 15765-3 (UDS on CAN)";
CM_ SG_ 2566730480 ISO11783Level2 "ISO 11783 Level 2";
CM_ BO_ 2566839024 "Software Identification";
CM_ SG_ 2566839024 SoftwareID3 "Software ID";
CM_ SG_ 2566839024 SoftwareID2 "Software ID";
CM_ SG_ 2566839024 SoftwareID1 "Software ID";
CM_ SG_ 2566839024 NmbrOfSftwrIdentificationFields "Number of software identification designators represented in the software identification parameter group.";
CM_ BO_ 2566768112 "ECU Identification Information";
CM_ BO_ 2566786944 "Language Command";
CM_ BO_ 2566843632 "Vehicle Identification";
CM_ BO_ 2566843520 "Vehicle Identification";
CM_ BO_ 2566835328 "Diagnostic data clear/reset of previously active DTCs.";
CM_ BO_ 2566835072 "Previously active diagnostic trouble codes";
CM_ SG_ 2566835072 DTC5 "Diagnostic Trouble Code";
CM_ SG_ 2566835072 DTC4 "Diagnostic Trouble Code";
CM_ SG_ 2566835072 DTC3 "Diagnostic Trouble Code";
CM_ SG_ 2566835072 DTC2 "Diagnostic Trouble Code";
CM_ SG_ 2566835072 DTC1 "Diagnostic Trouble Code";
CM_ SG_ 2566835072 MalfunctionIndicatorLampStatus "A lamp used to relay only emissions-related trouble code information.";
CM_ SG_ 2566835072 RedStopLampState "This lamp is uesed to relay trouble code information that is of a severe enought condition that it warrants stopping the vehicle.";
CM_ SG_ 2566835072 AmberWarningLampStatus "This lamp is used to relay trouble code information that is reporting a problem with the vehicle system but the vehicle need
not be immediately stopped.";
CM_ SG_ 2566835072 ProtectLampStatus "This lamp is used to relay trouble code informatio that is reporting a problem with a vehicle system that is most
probably not electronic subsystem related.";
CM_ SG_ 2566835072 FlashRedStopLamp "This parameter provides the capability to flash the RSL (SPN 3039).";
CM_ SG_ 2566835072 FlashProtectLamp "This parameter provides the capability to flash the engine protect lamp (SPN 3041).";
CM_ SG_ 2566835072 FlashMalfuncIndicatorLamp "This parameter provides the capability to flash the MIL (SPN 3038).";
CM_ SG_ 2566835072 FlashAmberWarningLamp "This parameter provides the capability to flash the AWL (SPN 3040). ";
CM_ BO_ 2566834816 "Active diagnostic trouble codes";
CM_ SG_ 2566834816 DTC5 "Diagnostic Trouble Code";
CM_ SG_ 2566834816 DTC4 "Diagnostic Trouble Code";
CM_ SG_ 2566834816 DTC3 "Diagnostic Trouble Code";
CM_ SG_ 2566834816 DTC2 "Diagnostic Trouble Code";
CM_ SG_ 2566834816 DTC1 "Diagnostic Trouble Code";
CM_ SG_ 2566834816 FlashRedStopLamp "This parameter provides the capability to flash the RSL (SPN 3039).";
CM_ SG_ 2566834816 FlashProtectLamp "This parameter provides the capability to flash the engine protect lamp (SPN 3041).";
CM_ SG_ 2566834816 FlashMalfuncIndicatorLamp "This parameter provides the capability to flash the MIL (SPN 3038).";
CM_ SG_ 2566834816 FlashAmberWarningLamp "This parameter provides the capability to flash the AWL (SPN 3040). ";
CM_ SG_ 2566834816 MalfunctionIndicatorLampStatus "A lamp used to relay only emissions-related trouble code information.";
CM_ SG_ 2566834816 AmberWarningLampStatus "This lamp is used to relay trouble code information that is reporting a problem with the vehicle system but the vehicle need
not be immediately stopped.";
CM_ SG_ 2566834816 RedStopLampState "This lamp is uesed to relay trouble code information that is of a severe enought condition that it warrants stopping the vehicle.";
CM_ SG_ 2566834816 ProtectLampStatus "This lamp is used to relay trouble code informatio that is reporting a problem with a vehicle system that is most
probably not electronic subsystem related.";
CM_ BO_ 2566730368 "ECU diagnostic protocol";
CM_ SG_ 2566730368 J1939_73 "J1939-73";
CM_ SG_ 2566730368 ISO14230 "ISO 14230 (KWP 2000 over K line)";
CM_ SG_ 2566730368 ISO15765_3 "ISO 15765-3 (UDS on CAN)";
CM_ SG_ 2566730368 ISO11783Level2 "ISO 11783 Level 2";
CM_ BO_ 2566838912 "Software Identification";
CM_ SG_ 2566838912 SoftwareID3 "Software ID";
CM_ SG_ 2566838912 SoftwareID2 "Software ID";
CM_ SG_ 2566838912 SoftwareID1 "Software ID";
CM_ SG_ 2566838912 NmbrOfSftwrIdentificationFields "Number of software identification designators represented in the software identification parameter group.";
CM_ BO_ 2566768000 "ECU Identification Information";
CM_ BO_ 2566835440 "Diagnostic data clear/reset of previously active DTCs.";
CM_ BO_ 2566835184 "Previously active diagnostic trouble codes";
CM_ SG_ 2566835184 DTC5 "Diagnostic Trouble Code";
CM_ SG_ 2566835184 DTC4 "Diagnostic Trouble Code";
CM_ SG_ 2566835184 DTC3 "Diagnostic Trouble Code";
CM_ SG_ 2566835184 DTC2 "Diagnostic Trouble Code";
CM_ SG_ 2566835184 DTC1 "Diagnostic Trouble Code";
CM_ SG_ 2566835184 MalfunctionIndicatorLampStatus "A lamp used to relay only emissions-related trouble code information.";
CM_ SG_ 2566835184 RedStopLampState "This lamp is uesed to relay trouble code information that is of a severe enought condition that it warrants stopping the vehicle.";
CM_ SG_ 2566835184 AmberWarningLampStatus "This lamp is used to relay trouble code information that is reporting a problem with the vehicle system but the vehicle need
not be immediately stopped.";
CM_ SG_ 2566835184 ProtectLampStatus "This lamp is used to relay trouble code informatio that is reporting a problem with a vehicle system that is most
probably not electronic subsystem related.";
CM_ SG_ 2566835184 FlashRedStopLamp "This parameter provides the capability to flash the RSL (SPN 3039).";
CM_ SG_ 2566835184 FlashProtectLamp "This parameter provides the capability to flash the engine protect lamp (SPN 3041).";
CM_ SG_ 2566835184 FlashMalfuncIndicatorLamp "This parameter provides the capability to flash the MIL (SPN 3038).";
CM_ SG_ 2566835184 FlashAmberWarningLamp "This parameter provides the capability to flash the AWL (SPN 3040). ";
CM_ BO_ 2566834928 "Active diagnostic trouble codes";
CM_ SG_ 2566834928 DTC5 "Diagnostic Trouble Code";
CM_ SG_ 2566834928 DTC4 "Diagnostic Trouble Code";
CM_ SG_ 2566834928 DTC3 "Diagnostic Trouble Code";
CM_ SG_ 2566834928 DTC2 "Diagnostic Trouble Code";
CM_ SG_ 2566834928 DTC1 "Diagnostic Trouble Code";
CM_ SG_ 2566834928 FlashRedStopLamp "This parameter provides the capability to flash the RSL (SPN 3039).";
CM_ SG_ 2566834928 FlashProtectLamp "This parameter provides the capability to flash the engine protect lamp (SPN 3041).";
CM_ SG_ 2566834928 FlashMalfuncIndicatorLamp "This parameter provides the capability to flash the MIL (SPN 3038).";
CM_ SG_ 2566834928 FlashAmberWarningLamp "This parameter provides the capability to flash the AWL (SPN 3040). ";
CM_ SG_ 2566834928 MalfunctionIndicatorLampStatus "A lamp used to relay only emissions-related trouble code information.";
CM_ SG_ 2566834928 AmberWarningLampStatus "This lamp is used to relay trouble code information that is reporting a problem with the vehicle system but the vehicle need
not be immediately stopped.";
CM_ SG_ 2566834928 RedStopLampState "This lamp is uesed to relay trouble code information that is of a severe enought condition that it warrants stopping the vehicle.";
CM_ SG_ 2566834928 ProtectLampStatus "This lamp is used to relay trouble code informatio that is reporting a problem with a vehicle system that is most
probably not electronic subsystem related.";
BA_DEF_ SG_  "GenSigStartValue" INT -2147483648 2147483647;
BA_DEF_ SG_  "GenSigSendType" ENUM  "Cyclic","OnWrite","OnWriteWithRepetition","OnChange","OnChangeWithRepetition","IfActive","IfActiveWithRepetition","NoSigSendType";
BA_DEF_ BU_  "ISO11783PDDVersion" ENUM  "0","1","2","3";
BA_DEF_ BU_  "ISO11783IOPVersion" ENUM  "0","1","2","3","4";
BA_DEF_  "ISO11783_12_SpecVersion" STRING ;
BA_DEF_ SG_  "SigType" ENUM  "Default","Range","RangeSigned","ASCII","Discrete","Control","ReferencePGN","DTC","StringDelimiter","StringLength","StringLengthControl";
BA_DEF_  "DatabaseVersion" STRING ;
BA_DEF_ SG_  "SPN" INT 0 524287;
BA_DEF_ BO_  "GenMsgRequestable" INT 0 1;
BA_DEF_ BO_  "GenMsgCycleTime" INT 0 3600000;
BA_DEF_ BO_  "GenMsgSendType" ENUM  "cyclic","reserved","cyclicIfActive","reserved","reserved","reserved","reserved","reserved","noMsgSendType","vector_leerstring";
BA_DEF_ BO_  "VFrameFormat" ENUM  "StandardCAN","ExtendedCAN","reserved","J1939PG","vector_leerstring";
BA_DEF_ BU_  "ECU" STRING ;
BA_DEF_ BU_  "NmJ1939IdentityNumber" INT 0 2097151;
BA_DEF_ BU_  "NmJ1939ManufacturerCode" INT 0 2047;
BA_DEF_ BU_  "NmJ1939ECUInstance" INT 0 7;
BA_DEF_ BU_  "NmJ1939FunctionInstance" INT 0 7;
BA_DEF_ BU_  "NmJ1939Function" INT 0 255;
BA_DEF_ BU_  "NmJ1939SystemInstance" INT 0 15;
BA_DEF_ BU_  "NmJ1939System" INT 0 127;
BA_DEF_ BU_  "NmJ1939IndustryGroup" INT 0 7;
BA_DEF_ BU_  "NmJ1939AAC" INT 0 1;
BA_DEF_ BU_  "NmStationAddress" INT 0 255;
BA_DEF_  "BusType" STRING ;
BA_DEF_  "ProtocolType" STRING ;
BA_DEF_ BU_  "NodeLayerModules" STRING ;
BA_DEF_ BO_  "SingleFrame" INT 0 1;
BA_DEF_ SG_  "DDI" INT 0 65535;
BA_DEF_  "ISO11783_6_SpecVersion" STRING ;
BA_DEF_  "ISO11783_7_SpecVersion" STRING ;
BA_DEF_  "ISO11783_11_SpecVersion" STRING ;
BA_DEF_ SG_  "SystemSignalLongSymbol" STRING ;
BA_DEF_DEF_  "GenSigStartValue" 0;
BA_DEF_DEF_  "GenSigSendType" "NoSigSendType";
BA_DEF_DEF_  "ISO11783PDDVersion" "3";
BA_DEF_DEF_  "ISO11783IOPVersion" "3";
BA_DEF_DEF_  "ISO11783_12_SpecVersion" "";
BA_DEF_DEF_  "SigType" "Default";
BA_DEF_DEF_  "DatabaseVersion" "";
BA_DEF_DEF_  "SPN" 0;
BA_DEF_DEF_  "GenMsgRequestable" 1;
BA_DEF_DEF_  "GenMsgCycleTime" 0;
BA_DEF_DEF_  "GenMsgSendType" "noMsgSendType";
BA_DEF_DEF_  "VFrameFormat" "J1939PG";
BA_DEF_DEF_  "ECU" "";
BA_DEF_DEF_  "NmJ1939IdentityNumber" 0;
BA_DEF_DEF_  "NmJ1939ManufacturerCode" 0;
BA_DEF_DEF_  "NmJ1939ECUInstance" 0;
BA_DEF_DEF_  "NmJ1939FunctionInstance" 0;
BA_DEF_DEF_  "NmJ1939Function" 0;
BA_DEF_DEF_  "NmJ1939SystemInstance" 0;
BA_DEF_DEF_  "NmJ1939System" 0;
BA_DEF_DEF_  "NmJ1939IndustryGroup" 0;
BA_DEF_DEF_  "NmJ1939AAC" 0;
BA_DEF_DEF_  "NmStationAddress" 254;
BA_DEF_DEF_  "BusType" "";
BA_DEF_DEF_  "ProtocolType" "";
BA_DEF_DEF_  "NodeLayerModules" "";
BA_DEF_DEF_  "SingleFrame" 1;
BA_DEF_DEF_  "DDI" 0;
BA_DEF_DEF_  "ISO11783_6_SpecVersion" "";
BA_DEF_DEF_  "ISO11783_7_SpecVersion" "";
BA_DEF_DEF_  "ISO11783_11_SpecVersion" "";
BA_DEF_DEF_  "SystemSignalLongSymbol" "";
BA_ "BusType" "CAN";
BA_ "ISO11783_11_SpecVersion" "2007-01-15 DIS";
BA_ "ISO11783_7_SpecVersion" "2007-03-17 DIS";
BA_ "ISO11783_6_SpecVersion" "2007-02-26 DIS";
BA_ "ProtocolType" "ISO11783";
BA_ "DatabaseVersion" "4.1";
BA_ "ISO11783_12_SpecVersion" "2006-10-24 DIS";
BA_ "NodeLayerModules" BU_ AuxInput "Iso11783_IL.dll";
BA_ "NmStationAddress" BU_ AuxInput 130;
BA_ "NmJ1939AAC" BU_ AuxInput 1;
BA_ "NmJ1939IndustryGroup" BU_ AuxInput 2;
BA_ "NmJ1939Function" BU_ AuxInput 66;
BA_ "NmJ1939ManufacturerCode" BU_ AuxInput 1861;
BA_ "NmJ1939IdentityNumber" BU_ AuxInput 701233;
BA_ "NmStationAddress" BU_ VT 38;
BA_ "NmJ1939AAC" BU_ VT 1;
BA_ "NmJ1939IndustryGroup" BU_ VT 2;
BA_ "NmJ1939System" BU_ VT 1;
BA_ "NmJ1939Function" BU_ VT 29;
BA_ "NmJ1939ManufacturerCode" BU_ VT 1861;
BA_ "ECU" BU_ VT "VT";
BA_ "NodeLayerModules" BU_ TECU "ISO11783_IL.dll";
BA_ "NmStationAddress" BU_ TECU 240;
BA_ "NmJ1939IndustryGroup" BU_ TECU 2;
BA_ "NmJ1939Function" BU_ TECU 134;
BA_ "NmJ1939ManufacturerCode" BU_ TECU 1861;
BA_ "NmJ1939IdentityNumber" BU_ TECU 701224;
BA_ "ECU" BU_ TECU "TECU";
BA_ "NmStationAddress" BU_ TC 247;
BA_ "NmJ1939IndustryGroup" BU_ TC 2;
BA_ "NmJ1939Function" BU_ TC 130;
BA_ "NmJ1939ManufacturerCode" BU_ TC 1861;
BA_ "ECU" BU_ TC "TC";
BA_ "NodeLayerModules" BU_ Sprayer "ISO11783_IL.dll";
BA_ "NmStationAddress" BU_ Sprayer 128;
BA_ "NmJ1939AAC" BU_ Sprayer 1;
BA_ "NmJ1939IndustryGroup" BU_ Sprayer 2;
BA_ "NmJ1939System" BU_ Sprayer 6;
BA_ "NmJ1939Function" BU_ Sprayer 132;
BA_ "NmJ1939ManufacturerCode" BU_ Sprayer 1861;
BA_ "NmJ1939IdentityNumber" BU_ Sprayer 702222;
BA_ "ECU" BU_ Sprayer "Sprayer";
BA_ "NodeLayerModules" BU_ GPS "GNSS_NL.dll";
BA_ "NmStationAddress" BU_ GPS 28;
BA_ "NmJ1939AAC" BU_ GPS 1;
BA_ "NmJ1939IndustryGroup" BU_ GPS 2;
BA_ "NmJ1939Function" BU_ GPS 23;
BA_ "NmJ1939ManufacturerCode" BU_ GPS 1861;
BA_ "NmJ1939IdentityNumber" BU_ GPS 701221;
BA_ "ECU" BU_ GPS "GPS";
BA_ "GenMsgCycleTime" BO_ 2632384130 100;
BA_ "GenMsgCycleTime" BO_ 2565340802 1000;
BA_ "GenMsgSendType" BO_ 2565340802 2;
BA_ "GenMsgCycleTime" BO_ 2566786944 100;
BA_ "SPN" SG_ 3221225472 CertificationYear 4313;
BA_ "SPN" SG_ 3221225472 CertificateRevision 4314;
BA_ "SPN" SG_ 3221225472 CertificateLaboratoryType 4315;
BA_ "SPN" SG_ 3221225472 CertificationLaboratoryID 4316;
BA_ "SPN" SG_ 3221225472 CertTypeVTWorkingSetMember 4324;
BA_ "SPN" SG_ 3221225472 CertTypeVTWorkingSetMaster 4323;
BA_ "SPN" SG_ 3221225472 CertTypeVirtualTerminal 4322;
BA_ "SPN" SG_ 3221225472 CertTypeClass3ECU 4321;
BA_ "SPN" SG_ 3221225472 CertTypeTECUClass3 4320;
BA_ "SPN" SG_ 3221225472 CertTypeTECUClass2 4319;
BA_ "SPN" SG_ 3221225472 CertTypeTECUClass1 4318;
BA_ "SPN" SG_ 3221225472 CertTypeMinimumECU 4317;
BA_ "SPN" SG_ 3221225472 CertTypeGPSReceiver 4329;
BA_ "SPN" SG_ 3221225472 CertTypeFileServer 4328;
BA_ "SPN" SG_ 3221225472 CertTypeTCWorkingSetMember 4327;
BA_ "SPN" SG_ 3221225472 CertTypeTCWorkingSetMaster 4326;
BA_ "SPN" SG_ 3221225472 CertTypeTaskController 4325;
BA_ "SPN" SG_ 3221225472 CertificationReferenceNumber 4330;
BA_ "SigType" SG_ 2566688240 ProductIdentificationCode 8;
BA_ "SPN" SG_ 2566688240 ProductIdentificationCode 6699;
BA_ "SigType" SG_ 2566688240 ProductIdentificationBrand 8;
BA_ "SPN" SG_ 2566688240 ProductIdentificationBrand 6700;
BA_ "SigType" SG_ 2566688240 ProductIdentificationModel 8;
BA_ "SPN" SG_ 2566688240 ProductIdentificationModel 6701;
BA_ "SigType" SG_ 2566688128 ProductIdentificationCode 8;
BA_ "SPN" SG_ 2566688128 ProductIdentificationCode 6699;
BA_ "SigType" SG_ 2566688128 ProductIdentificationBrand 8;
BA_ "SPN" SG_ 2566688128 ProductIdentificationBrand 6700;
BA_ "SigType" SG_ 2566688128 ProductIdentificationModel 8;
BA_ "SPN" SG_ 2566688128 ProductIdentificationModel 6701;
BA_ "SigType" SG_ 2566688254 ProductIdentificationCode 8;
BA_ "SPN" SG_ 2566688254 ProductIdentificationCode 6699;
BA_ "SigType" SG_ 2566688254 ProductIdentificationBrand 8;
BA_ "SPN" SG_ 2566688254 ProductIdentificationBrand 6700;
BA_ "SigType" SG_ 2566688254 ProductIdentificationModel 8;
BA_ "SPN" SG_ 2566688254 ProductIdentificationModel 6701;
BA_ "SPN" SG_ 2566734464 CertLaboratoryType_FirstDef 4315;
BA_ "SPN" SG_ 2566734464 MessageRevision 7446;
BA_ "SPN" SG_ 2566734464 CertLaboratoryType_SecondDef 4315;
BA_ "SPN" SG_ 2566734464 TestProtocolRevision 4314;
BA_ "SPN" SG_ 2566734464 TestProtocolPublicationYear 4313;
BA_ "SPN" SG_ 2566734464 CertificationLaboratoryID 4316;
BA_ "SPN" SG_ 2566734464 CertTypeVTWorkingSetMember 4324;
BA_ "SPN" SG_ 2566734464 CertTypeVTWorkingSetMaster 4323;
BA_ "SPN" SG_ 2566734464 CertTypeVirtualTerminal 4322;
BA_ "SPN" SG_ 2566734464 CertTypeClass3ECU 4321;
BA_ "SPN" SG_ 2566734464 CertTypeTECUClass3 4320;
BA_ "SPN" SG_ 2566734464 CertTypeTECUClass2 4319;
BA_ "SPN" SG_ 2566734464 CertTypeTECUClass1 4318;
BA_ "SPN" SG_ 2566734464 CertTypeMinimumECU 4317;
BA_ "SPN" SG_ 2566734464 CertTypeGPSReceiver 4329;
BA_ "SPN" SG_ 2566734464 CertTypeFileServer 4328;
BA_ "SPN" SG_ 2566734464 CertTypeTCWorkingSetMember 4327;
BA_ "SPN" SG_ 2566734464 CertTypeTCWorkingSetMaster 4326;
BA_ "SPN" SG_ 2566734464 CertTypeTaskController 4325;
BA_ "SPN" SG_ 2566734464 CertificationReferenceNumber 4330;
BA_ "SPN" SG_ 2566734576 CertLaboratoryType_FirstDef 4315;
BA_ "SPN" SG_ 2566734576 MessageRevision 7446;
BA_ "SPN" SG_ 2566734576 CertLaboratoryType_SecondDef 4315;
BA_ "SPN" SG_ 2566734576 TestProtocolRevision 4314;
BA_ "SPN" SG_ 2566734576 TestProtocolPublicationYear 4313;
BA_ "SPN" SG_ 2566734576 CertificationLaboratoryID 4316;
BA_ "SPN" SG_ 2566734576 CertTypeVTWorkingSetMember 4324;
BA_ "SPN" SG_ 2566734576 CertTypeVTWorkingSetMaster 4323;
BA_ "SPN" SG_ 2566734576 CertTypeVirtualTerminal 4322;
BA_ "SPN" SG_ 2566734576 CertTypeClass3ECU 4321;
BA_ "SPN" SG_ 2566734576 CertTypeTECUClass3 4320;
BA_ "SPN" SG_ 2566734576 CertTypeTECUClass2 4319;
BA_ "SPN" SG_ 2566734576 CertTypeTECUClass1 4318;
BA_ "SPN" SG_ 2566734576 CertTypeMinimumECU 4317;
BA_ "SPN" SG_ 2566734576 CertTypeGPSReceiver 4329;
BA_ "SPN" SG_ 2566734576 CertTypeFileServer 4328;
BA_ "SPN" SG_ 2566734576 CertTypeTCWorkingSetMember 4327;
BA_ "SPN" SG_ 2566734576 CertTypeTCWorkingSetMaster 4326;
BA_ "SPN" SG_ 2566734576 CertTypeTaskController 4325;
BA_ "SPN" SG_ 2566734576 CertificationReferenceNumber 4330;
BA_ "SPN" SG_ 2365391614 StopAllImplOpTransitionNum 7443;
BA_ "SPN" SG_ 2365391614 StopAllImplOpSwitchState 5140;
BA_ "SigType" SG_ 2632384130 AuxiliaryFunctionObjectID 1;
BA_ "SigType" SG_ 2632384130 AuxiliaryInputObjectID 1;
BA_ "SigType" SG_ 2632384130 SelfConfigurableAddress 4;
BA_ "SigType" SG_ 2632384130 DeviceClassInstance 4;
BA_ "SigType" SG_ 2632384130 IndustryGroup 4;
BA_ "SigType" SG_ 2632384130 FontType_ProportionalFont 4;
BA_ "SigType" SG_ 2632384130 FontType_FlashHidden 4;
BA_ "SigType" SG_ 2632384130 FontType_FlashInverted 4;
BA_ "SigType" SG_ 2632384130 FontType_InvertedText 4;
BA_ "SigType" SG_ 2632384130 FontType_ItalicsText 4;
BA_ "SigType" SG_ 2632384130 FontType_UnderlinedText 4;
BA_ "SigType" SG_ 2632384130 FontType_CrossedOutText 4;
BA_ "SigType" SG_ 2632384130 DeviceClass 1;
BA_ "SigType" SG_ 2632384130 VTFunctionCode 1;
BA_ "SigType" SG_ 2632384130 FontType_BoldText 4;
BA_ "SigType" SG_ 2632384130 NumberOfPhysicalSoftKeys 1;
BA_ "SigType" SG_ 2632384130 VTBusyCode8 4;
BA_ "SigType" SG_ 2632384130 FontSize_128x192 4;
BA_ "SigType" SG_ 2632384130 FontSize_128x128 4;
BA_ "SigType" SG_ 2632384130 VTBusyCode5 4;
BA_ "SigType" SG_ 2632384130 FontSize_96x128 4;
BA_ "SigType" SG_ 2632384130 ErrorCodeChangeListItem4 4;
BA_ "SigType" SG_ 2632384130 VTBusyCode4 4;
BA_ "SigType" SG_ 2632384130 FontSize_64x96 4;
BA_ "SigType" SG_ 2632384130 ErrorCodeObjectPool4 4;
BA_ "SigType" SG_ 2632384130 VTBusyCode3 4;
BA_ "SigType" SG_ 2632384130 FontSize_64x64 4;
BA_ "SigType" SG_ 2632384130 ErrorCodeChangeListItem3 4;
BA_ "SigType" SG_ 2632384130 ErrorCodeObjectPool3 4;
BA_ "SigType" SG_ 2632384130 VTBusyCode2 4;
BA_ "SigType" SG_ 2632384130 FontSize_48x64 4;
BA_ "SigType" SG_ 2632384130 ErrorCodeChangeListItem2 4;
BA_ "SigType" SG_ 2632384130 ErrorCodeObjectPool2 4;
BA_ "SigType" SG_ 2632384130 VTBusyCode1 4;
BA_ "SigType" SG_ 2632384130 NrOfYPixelsInDataAreaMask 1;
BA_ "SigType" SG_ 2632384130 FontSize_32x48 4;
BA_ "SigType" SG_ 2632384130 NumberOfPossibleVirtualSoftKeys 1;
BA_ "SigType" SG_ 2632384130 ErrorCodeChangeListItem1 4;
BA_ "SigType" SG_ 2632384130 Function 1;
BA_ "SigType" SG_ 2632384130 ErrorCodeObjectPool1 4;
BA_ "SigType" SG_ 2632384130 VTChangeActiveMaskParentID 1;
BA_ "SigType" SG_ 2632384130 ButtonKeyCode 1;
BA_ "SigType" SG_ 2632384130 SoftKeyCode 1;
BA_ "SigType" SG_ 2632384130 FontSize_32x32 4;
BA_ "SigType" SG_ 2632384130 FontSize_24x32 4;
BA_ "SigType" SG_ 2632384130 FontSize_16x24 4;
BA_ "SigType" SG_ 2632384130 ErrorCodeChangePosInvalidError 4;
BA_ "SigType" SG_ 2632384130 ErrorCodeChangeSoftKeyMask5 4;
BA_ "SigType" SG_ 2632384130 ErrorCodeChangeChildLocation5 4;
BA_ "SigType" SG_ 2632384130 ErrorCodeVTChangeSoftKeyMask5 4;
BA_ "SigType" SG_ 2632384130 ErrorCodeVtObjPoolError4 4;
BA_ "SigType" SG_ 2632384130 FontSize_16x16 4;
BA_ "SigType" SG_ 2632384130 ErrorCodeChangeStrError 4;
BA_ "SigType" SG_ 2632384130 ErrorCodeChangeSoftKeyMask4 4;
BA_ "SigType" SG_ 2632384130 FunctionInstance 1;
BA_ "SigType" SG_ 2632384130 ErrorCodeVTChangeSoftKeyMask4 4;
BA_ "SigType" SG_ 2632384130 ErrorCodeVtObjPoolError3 4;
BA_ "SigType" SG_ 2632384130 FontSize_12x16 4;
BA_ "SigType" SG_ 2632384130 ErrorCodeChangeStrTooLong 4;
BA_ "SigType" SG_ 2632384130 ErrorCodeChangeSoftKeyMask3 4;
BA_ "SigType" SG_ 2632384130 ErrorCodeVTChangeSoftKeyMask3 4;
BA_ "SigType" SG_ 2632384130 ErrorCodeVtObjPoolError2 4;
BA_ "SigType" SG_ 2632384130 FontSize_8x12 4;
BA_ "SigType" SG_ 2632384130 ErrorCodeChangePosInvalidObject 4;
BA_ "SigType" SG_ 2632384130 ErrorCodeChangeStrObjectID 4;
BA_ "SigType" SG_ 2632384130 ErrorCodeChangeSoftKeyMask2 4;
BA_ "SigType" SG_ 2632384130 ErrorCodeChangeChildLocation2 4;
BA_ "SigType" SG_ 2632384130 ErrorCodeVTChangeSoftKeyMask2 4;
BA_ "SigType" SG_ 2632384130 ErrorCodeVtObjPoolError1 4;
BA_ "SigType" SG_ 2632384130 AcknowledgmentDeleteVersion 4;
BA_ "SigType" SG_ 2632384130 AcknowledgmentLoadVersion 4;
BA_ "SigType" SG_ 2632384130 AcknowledgmentStoreVersion 4;
BA_ "SigType" SG_ 2632384130 FontSize_8x8 4;
BA_ "SigType" SG_ 2632384130 YDotsForSoftKeyDescriptor 1;
BA_ "SigType" SG_ 2632384130 ErrorCodeChangePosInvalidParent 4;
BA_ "SigType" SG_ 2632384130 ErrorCodeChangeSoftKeyMask1 4;
BA_ "SigType" SG_ 2632384130 ErrorCodeChangeChildLocation1 4;
BA_ "SigType" SG_ 2632384130 Value2 1;
BA_ "SigType" SG_ 2632384130 ECUInstance 4;
BA_ "SigType" SG_ 2632384130 ErrorCodeVTChangeSoftKeyMask1 4;
BA_ "SigType" SG_ 2632384130 ErrorCodeChangePriority3 4;
BA_ "SigType" SG_ 2632384130 ErrorCodeChangeAttribute4 4;
BA_ "SigType" SG_ 2632384130 ErrorCodeChangeColour3 4;
BA_ "SigType" SG_ 2632384130 ErrorCodeSelectObject5 4;
BA_ "SigType" SG_ 2632384130 ErrorCodeEnableDisableObj4 4;
BA_ "SigType" SG_ 2632384130 ErrorCodeSelectObject4 4;
BA_ "SigType" SG_ 2632384130 ErrorCodeEnableDisableObj3 4;
BA_ "SigType" SG_ 2632384130 ErrorCodeHideShowObj3 4;
BA_ "SigType" SG_ 2632384130 ErrorCodeChangeAttribute3 4;
BA_ "SigType" SG_ 2632384130 ErrorCodeSelectObject3 4;
BA_ "SigType" SG_ 2632384130 ErrorCodeEnableDisableObj2 4;
BA_ "SigType" SG_ 2632384130 ErrorCodeChangePriority2 4;
BA_ "SigType" SG_ 2632384130 ErrorCodeChangeAttribute2 4;
BA_ "SigType" SG_ 2632384130 ErrorCodeChangeColour2 4;
BA_ "SigType" SG_ 2632384130 ErrorCodeSelectObject2 4;
BA_ "SigType" SG_ 2632384130 ErrorCodeEnableDisableObj1 4;
BA_ "SigType" SG_ 2632384130 ErrorCodeHideShowObj2 4;
BA_ "SigType" SG_ 2632384130 VisibleSoftKeyMaskObjectID 1;
BA_ "SigType" SG_ 2632384130 NrOfXPixelsInDataAreaMask 1;
BA_ "SigType" SG_ 2632384130 XDotsForSoftKeyDescriptor 1;
BA_ "SigType" SG_ 2632384130 NewObjectID 1;
BA_ "SigType" SG_ 2632384130 ErrorCodeChangePriority1 4;
BA_ "SigType" SG_ 2632384130 ErrorCodeChangeAttribute1 4;
BA_ "SigType" SG_ 2632384130 ValueOfTheObject 1;
BA_ "SigType" SG_ 2632384130 ErrorCodeChangeColour1 4;
BA_ "SigType" SG_ 2632384130 ErrorCodeSelectObject1 4;
BA_ "SigType" SG_ 2632384130 ErrorCodeHideShowObj1 4;
BA_ "SigType" SG_ 2632384130 ObjectIdOfFaultyObject 1;
BA_ "SigType" SG_ 2632384130 VTChangeActiveMaskErrorID 1;
BA_ "SigType" SG_ 2632384130 VTChangeNumericValueValue 1;
BA_ "SigType" SG_ 2632384130 VTSelectInputObjectIsEdited 1;
BA_ "SigType" SG_ 2632384130 ButtonObjectParentID 1;
BA_ "SigType" SG_ 2632384130 KeyObjectParentID 1;
BA_ "SigType" SG_ 2632384130 ErrorCodeChangeFont6 4;
BA_ "SigType" SG_ 2632384130 ManufacturerCode 1;
BA_ "SPN" SG_ 2632384130 ManufacturerCode 2838;
BA_ "SigType" SG_ 2632384130 ErrorCodePoolDeleted 4;
BA_ "SigType" SG_ 2632384130 ErrorCodeChangeActiveMask5 4;
BA_ "SigType" SG_ 2632384130 ErrorCodeChangeFillAttributes5 4;
BA_ "SigType" SG_ 2632384130 ErrorCodeChangeLineAttribute4 4;
BA_ "SigType" SG_ 2632384130 ErrorCodeChangeFont5 4;
BA_ "SigType" SG_ 2632384130 ErrorCodeChangeEditPoint3 4;
BA_ "SigType" SG_ 2632384130 ErrorCodeObjToSize4 4;
BA_ "SigType" SG_ 2632384130 ErrorCodeEscapeObj2 4;
BA_ "SigType" SG_ 2632384130 ErrorCodeAnyOtherError 4;
BA_ "SigType" SG_ 2632384130 ErrorCodeVTEsc2 4;
BA_ "SigType" SG_ 2632384130 Hardware4 4;
BA_ "SigType" SG_ 2632384130 ErrorCodeChangeActiveMask4 4;
BA_ "SigType" SG_ 2632384130 ErrorCodeChangeFillAttributes4 4;
BA_ "SigType" SG_ 2632384130 ErrorCodeChangeFont4 4;
BA_ "SigType" SG_ 2632384130 ErrorCodeMaskOrChildObjectError 4;
BA_ "SigType" SG_ 2632384130 ErrorCodeChangeNumValue3 4;
BA_ "SigType" SG_ 2632384130 Hardware3 4;
BA_ "SigType" SG_ 2632384130 ErrorCodeChangeActiveMask3 4;
BA_ "SigType" SG_ 2632384130 ErrorCodeChangeFillAttributes3 4;
BA_ "SigType" SG_ 2632384130 ErrorCodeChangeLineAttribute3 4;
BA_ "SigType" SG_ 2632384130 ErrorCodeChangeFont3 4;
BA_ "SigType" SG_ 2632384130 ErrorCodeObjToSize3 4;
BA_ "SigType" SG_ 2632384130 ErrorCodeMissingObjects 4;
BA_ "SigType" SG_ 2632384130 Hardware2 4;
BA_ "SigType" SG_ 2632384130 ErrorCodeChangeActiveMask2 4;
BA_ "SigType" SG_ 2632384130 ErrorCodeChangeFillAttributes2 4;
BA_ "SigType" SG_ 2632384130 ErrorCodeChangeLineAttribute2 4;
BA_ "SigType" SG_ 2632384130 ErrorCodeChangeFont2 4;
BA_ "SigType" SG_ 2632384130 ErrorCodeChangeEditPoint2 4;
BA_ "SigType" SG_ 2632384130 ErrorCodeChangeNumValue2 4;
BA_ "SigType" SG_ 2632384130 ErrorCodeObjToSize2 4;
BA_ "SigType" SG_ 2632384130 ObjectIDOfFaultyObject 1;
BA_ "SigType" SG_ 2632384130 Hardware1 4;
BA_ "SigType" SG_ 2632384130 ListIndex 1;
BA_ "SigType" SG_ 2632384130 NewPriority 1;
BA_ "SigType" SG_ 2632384130 SoftKeyMaskObjectID 1;
BA_ "SigType" SG_ 2632384130 ErrorCodeChangeActiveMask1 4;
BA_ "SigType" SG_ 2632384130 ErrorCodeChangeFillAttributes1 4;
BA_ "SigType" SG_ 2632384130 ErrorCodeChangeLineAttribute1 4;
BA_ "SigType" SG_ 2632384130 ErrorCodeChangeFont1 4;
BA_ "SigType" SG_ 2632384130 ErrorCodeChangeEditPoint1 4;
BA_ "SigType" SG_ 2632384130 ErrorCodeChangeNumValue1 4;
BA_ "SigType" SG_ 2632384130 NewBackgroundColour 1;
BA_ "SigType" SG_ 2632384130 ErrorCodeObjToSize1 4;
BA_ "SigType" SG_ 2632384130 ObjectSelectStatus 1;
BA_ "SigType" SG_ 2632384130 ObjectEnableStatus 1;
BA_ "SigType" SG_ 2632384130 ObjectShowStatus 1;
BA_ "SigType" SG_ 2632384130 ErrorCodeEscapeObj1 4;
BA_ "SigType" SG_ 2632384130 Value1 1;
BA_ "SigType" SG_ 2632384130 EnteredStringValue 9;
BA_ "SigType" SG_ 2632384130 VTChangeSoftKeyMaskObjectID 1;
BA_ "SigType" SG_ 2632384130 ErrorCodeVTEsc1 4;
BA_ "SigType" SG_ 2632384130 VTSelectInputObjectStatus 1;
BA_ "SigType" SG_ 2632384130 YPosition 1;
BA_ "SigType" SG_ 2632384130 VisibleDataOrAlarmMaskObjectID 1;
BA_ "SigType" SG_ 2632384130 VersionLables 3;
BA_ "SigType" SG_ 2632384130 MemoryStatus 1;
BA_ "SigType" SG_ 2632384130 ButtonObjectID 1;
BA_ "SigType" SG_ 2632384130 KeyObjectID 1;
BA_ "SystemSignalLongSymbol" SG_ 2632384130 BckgndColourUserLayoutSoftkeyMas "BckgndColourUserLayoutSoftkeyMask";
BA_ "SigType" SG_ 2632384130 ErrorCodeDeleteObjectPool2 4;
BA_ "SigType" SG_ 2632384130 ErrorCodeAudioVolume2 4;
BA_ "SigType" SG_ 2632384130 ErrorCodeControlAudioDevice2 4;
BA_ "SigType" SG_ 2632384130 ErrorCodeEndOfObjectPool3 4;
BA_ "SigType" SG_ 2632384130 ErrorCodeEndOfObjectPool2 4;
BA_ "SigType" SG_ 2632384130 SourceAdressOfActiveWSM 1;
BA_ "SigType" SG_ 2632384130 NrOfVersionStrings 1;
BA_ "SigType" SG_ 2632384130 VersionNumberISO11783Part6 1;
BA_ "SystemSignalLongSymbol" SG_ 2632384130 ChangeChildPositionParentObjectI "ChangeChildPositionParentObjectID";
BA_ "SigType" SG_ 2632384130 ErrorCodeDeleteObjectPool1 4;
BA_ "SigType" SG_ 2632384130 ListInputObjectID 1;
BA_ "SigType" SG_ 2632384130 AlarmMaskObjectID 1;
BA_ "SigType" SG_ 2632384130 ObjectToChangeAttributeID 1;
BA_ "SigType" SG_ 2632384130 DataOrAlarmMaskObjectID 1;
BA_ "SigType" SG_ 2632384130 ActiveMaskObjectID 1;
BA_ "SigType" SG_ 2632384130 ObjectToChangeFillAttributesID 1;
BA_ "SigType" SG_ 2632384130 ObjectToChangeLineAttributeID 1;
BA_ "SigType" SG_ 2632384130 ObjectToChangeFontID 1;
BA_ "SigType" SG_ 2632384130 ObjectToChangeEndPointID 1;
BA_ "SigType" SG_ 2632384130 ObjectToChangeNumValueID 1;
BA_ "SigType" SG_ 2632384130 ObjectToChangeColourID 1;
BA_ "SigType" SG_ 2632384130 ObjectToSizeID 1;
BA_ "SystemSignalLongSymbol" SG_ 2632384130 ChangeChildLocationParentObjectI "ChangeChildLocationParentObjectID";
BA_ "SigType" SG_ 2632384130 ErrorCodeAudioVolume1 4;
BA_ "SigType" SG_ 2632384130 ErrorCodeControlAudioDevice1 4;
BA_ "SigType" SG_ 2632384130 SelectInputObjectID 1;
BA_ "SigType" SG_ 2632384130 ObjectToEnableDisableID 1;
BA_ "SigType" SG_ 2632384130 ObjectToHideShowID 1;
BA_ "SigType" SG_ 2632384130 ObjectEscapeID 1;
BA_ "SigType" SG_ 2632384130 InputStatusObjectId 1;
BA_ "SigType" SG_ 2632384130 InputObjectId 1;
BA_ "SigType" SG_ 2632384130 IdentityNumber 1;
BA_ "SigType" SG_ 2632384130 ErrorCodeEndOfObjectPool1 4;
BA_ "SigType" SG_ 2632384130 ObjectToChangeStringID 1;
BA_ "SigType" SG_ 2632384130 VTChangeSoftKeyMaskParentID 1;
BA_ "SigType" SG_ 2632384130 VTChangeActiveMaskObjectID 1;
BA_ "SigType" SG_ 2632384130 VTChangeNumericValueObjectID 1;
BA_ "SigType" SG_ 2632384130 VTEscObjectID 1;
BA_ "SigType" SG_ 2632384130 VTSelectInputObjectID 1;
BA_ "SigType" SG_ 2632384130 XPosition 1;
BA_ "SigType" SG_ 2632384130 ButtonActivationCode 1;
BA_ "SigType" SG_ 2632384130 KeyActivationCode 1;
BA_ "SigType" SG_ 2632384130 VTFunctionVTtoECU 1;
BA_ "SigType" SG_ 2565799554 Function 1;
BA_ "SigType" SG_ 2565799554 ManufacturerCode 1;
BA_ "SigType" SG_ 2565799554 IdentityNumber 1;
BA_ "SigType" SG_ 2565340802 VTFunctionECUtoVT 1;
BA_ "SigType" SG_ 2565340802 KeyActivationCode 1;
BA_ "SigType" SG_ 2565340802 KeyObjectParentID 1;
BA_ "SigType" SG_ 2565340802 KeyObjectID 1;
BA_ "SigType" SG_ 2565340802 SoftKeyCode 1;
BA_ "SigType" SG_ 2565340802 ButtonActivationCode 1;
BA_ "SigType" SG_ 2565340802 ButtonObjectID 1;
BA_ "SigType" SG_ 2565340802 ButtonObjectParentID 1;
BA_ "SigType" SG_ 2565340802 ButtonKeyCode 1;
BA_ "SigType" SG_ 2565340802 XPosition 1;
BA_ "SigType" SG_ 2565340802 YPosition 1;
BA_ "SigType" SG_ 2565340802 VTSelectInputObjectID 1;
BA_ "SigType" SG_ 2565340802 VTSelectInputObjectStatus 1;
BA_ "SigType" SG_ 2565340802 VTEscObjectID 1;
BA_ "SigType" SG_ 2565340802 VTChangeNumericValueObjectID 1;
BA_ "SigType" SG_ 2565340802 VTChangeNumericValueValue 1;
BA_ "SigType" SG_ 2565340802 VTChangeActiveMaskObjectID 1;
BA_ "SigType" SG_ 2565340802 VTChangeSoftKeyMaskParentID 1;
BA_ "SigType" SG_ 2565340802 VTChangeSoftKeyMaskObjectID 1;
BA_ "SigType" SG_ 2565340802 ObjectToChangeStringValueID 1;
BA_ "SigType" SG_ 2565340802 ObjectPoolRecord 1;
BA_ "SigType" SG_ 2565340802 AuxiliaryFunctionObjectID 1;
BA_ "SigType" SG_ 2565340802 AssignmentErrorNotAccepted 4;
BA_ "SigType" SG_ 2565340802 IsEnabled 1;
BA_ "SigType" SG_ 2565340802 InputStatusObjectId 1;
BA_ "SigType" SG_ 2565340802 ObjectToShowHideID 1;
BA_ "SigType" SG_ 2565340802 ShowOrHide 1;
BA_ "SigType" SG_ 2565340802 ObjectoEnableDisbaleID 1;
BA_ "SigType" SG_ 2565340802 EnableOrDisable 1;
BA_ "SigType" SG_ 2565340802 SelectInputObjectID 1;
BA_ "SigType" SG_ 2565340802 NumberOfRepetitions_Audio 1;
BA_ "SigType" SG_ 2565340802 Frequency_Audio 1;
BA_ "SigType" SG_ 2565340802 OnTimeDuration_Audio 1;
BA_ "SigType" SG_ 2565340802 OffTimeDuration_Audio 1;
BA_ "SigType" SG_ 2565340802 AudioVolume 1;
BA_ "SigType" SG_ 2565340802 ObjectToMoveID 1;
BA_ "SigType" SG_ 2565340802 XPosChangeTopLeft 1;
BA_ "SigType" SG_ 2565340802 YPosChangeTopLeft 1;
BA_ "SigType" SG_ 2565340802 ObjectToSizeID 1;
BA_ "SigType" SG_ 2565340802 NewWidth 1;
BA_ "SigType" SG_ 2565340802 NewHeight 1;
BA_ "SigType" SG_ 2565340802 ObjectToChangeColourID 1;
BA_ "SigType" SG_ 2565340802 NewBackgroundColour 1;
BA_ "SigType" SG_ 2565340802 ObjectToChangeNumValueID 1;
BA_ "SigType" SG_ 2565340802 NewValue 1;
BA_ "SigType" SG_ 2565340802 ObjectToChangeEndPointID 1;
BA_ "SigType" SG_ 2565340802 Width 1;
BA_ "SigType" SG_ 2565340802 Height 1;
BA_ "SigType" SG_ 2565340802 LineDirection 1;
BA_ "SigType" SG_ 2565340802 ObjectToChangeFontID 1;
BA_ "SigType" SG_ 2565340802 FontColour 1;
BA_ "SigType" SG_ 2565340802 FontSize 1;
BA_ "SigType" SG_ 2565340802 FontType 1;
BA_ "SigType" SG_ 2565340802 FontStyle 1;
BA_ "SigType" SG_ 2565340802 ObjectToChangeLineAttributesID 1;
BA_ "SigType" SG_ 2565340802 LineColour 1;
BA_ "SigType" SG_ 2565340802 LineWidth 1;
BA_ "SigType" SG_ 2565340802 LineArt 1;
BA_ "SigType" SG_ 2565340802 ObjectToChangeFillAttributesID 1;
BA_ "SigType" SG_ 2565340802 FillType 1;
BA_ "SigType" SG_ 2565340802 FillColour 1;
BA_ "SigType" SG_ 2565340802 FillPatternObjectID 1;
BA_ "SigType" SG_ 2565340802 WorkingSetObjectID 1;
BA_ "SigType" SG_ 2565340802 NewActiveMaskObjectID 1;
BA_ "SigType" SG_ 2565340802 MaskType 1;
BA_ "SigType" SG_ 2565340802 DataOrAlarmMaskObjectID 1;
BA_ "SigType" SG_ 2565340802 NewSoftKeyMaskObjectID 1;
BA_ "SigType" SG_ 2565340802 ObjectToChangeAttributeID 1;
BA_ "SigType" SG_ 2565340802 AttributeID 1;
BA_ "SigType" SG_ 2565340802 NewAttributeValue 1;
BA_ "SigType" SG_ 2565340802 AlarmMaskObjectID 1;
BA_ "SigType" SG_ 2565340802 NewPriority 1;
BA_ "SigType" SG_ 2565340802 ListInputObjectID 1;
BA_ "SigType" SG_ 2565340802 ListIndex 1;
BA_ "SigType" SG_ 2565340802 NewObjectID 1;
BA_ "SigType" SG_ 2565340802 NewStringValue 9;
BA_ "SigType" SG_ 2565340802 MemoryRequired 1;
BA_ "SigType" SG_ 2565340802 VersionLabelToStore 3;
BA_ "SigType" SG_ 2565340802 VersionLabelToLoad 3;
BA_ "SigType" SG_ 2565340802 VersionLabelToDelete 3;
BA_ "GenSigStartValue" SG_ 2566688384 NumberOfFunctionalities 1;
BA_ "GenSigStartValue" SG_ 2566688384 FunctionalityGeneration 1;
BA_ "GenSigStartValue" SG_ 2566688510 NumberOfFunctionalities 1;
BA_ "GenSigStartValue" SG_ 2566688510 FunctionalityGeneration 1;
BA_ "SPN" SG_ 2566839024 SoftwareID3 234;
BA_ "SigType" SG_ 2566839024 SoftwareID3 8;
BA_ "SPN" SG_ 2566839024 SoftwareID2 234;
BA_ "SigType" SG_ 2566839024 SoftwareID2 8;
BA_ "SPN" SG_ 2566839024 SoftwareID1 234;
BA_ "SigType" SG_ 2566839024 SoftwareID1 8;
BA_ "SPN" SG_ 2566839024 NmbrOfSftwrIdentificationFields 965;
BA_ "SigType" SG_ 2566839024 NmbrOfSftwrIdentificationFields 1;
BA_ "SigType" SG_ 2566768112 ECUHardwareID 8;
BA_ "SPN" SG_ 2566768112 ECUManufacturerName 4304;
BA_ "SigType" SG_ 2566768112 ECUManufacturerName 8;
BA_ "SPN" SG_ 2566768112 ECUType 2904;
BA_ "SigType" SG_ 2566768112 ECUType 8;
BA_ "SPN" SG_ 2566768112 ECULocation 2903;
BA_ "SigType" SG_ 2566768112 ECULocation 8;
BA_ "SPN" SG_ 2566768112 ECUSerialNumber 2902;
BA_ "SigType" SG_ 2566768112 ECUSerialNumber 8;
BA_ "SPN" SG_ 2566768112 ECUPartNumber 2901;
BA_ "SigType" SG_ 2566768112 ECUPartNumber 8;
BA_ "SigType" SG_ 2566786944 LanguageCodeCmd 3;
BA_ "SPN" SG_ 2566786944 LanguageCodeCmd 2410;
BA_ "SigType" SG_ 2566786944 TimeFormatCmd 4;
BA_ "SPN" SG_ 2566786944 TimeFormatCmd 2413;
BA_ "SigType" SG_ 2566786944 DecimalSymbolCmd 4;
BA_ "SPN" SG_ 2566786944 DecimalSymbolCmd 2411;
BA_ "SigType" SG_ 2566786944 DateFormatCmd 1;
BA_ "SPN" SG_ 2566786944 DateFormatCmd 2412;
BA_ "SigType" SG_ 2566786944 MassUnitCmd 4;
BA_ "SPN" SG_ 2566786944 MassUnitCmd 2417;
BA_ "SigType" SG_ 2566786944 VolumeUnitCmd 4;
BA_ "SPN" SG_ 2566786944 VolumeUnitCmd 2416;
BA_ "SigType" SG_ 2566786944 AreaUnitCmd 4;
BA_ "SPN" SG_ 2566786944 AreaUnitCmd 2415;
BA_ "SigType" SG_ 2566786944 DistanceUnitCmd 4;
BA_ "SPN" SG_ 2566786944 DistanceUnitCmd 2414;
BA_ "SigType" SG_ 2566786944 UnitsSystem 4;
BA_ "SigType" SG_ 2566786944 ForceUnits 4;
BA_ "SigType" SG_ 2566786944 PressureUnits 4;
BA_ "SigType" SG_ 2566786944 TemperatureUnits 4;
BA_ "SPN" SG_ 2566843632 VehicleIdentificationNumber 237;
BA_ "SigType" SG_ 2566843632 VehicleIdentificationNumber 8;
BA_ "SPN" SG_ 2566843520 VehicleIdentificationNumber 237;
BA_ "SigType" SG_ 2566843520 VehicleIdentificationNumber 8;
BA_ "SigType" SG_ 2566835072 DTC5 7;
BA_ "SigType" SG_ 2566835072 DTC4 7;
BA_ "SigType" SG_ 2566835072 DTC3 7;
BA_ "SigType" SG_ 2566835072 DTC2 7;
BA_ "SigType" SG_ 2566835072 DTC1 7;
BA_ "SPN" SG_ 2566835072 MalfunctionIndicatorLampStatus 1213;
BA_ "SigType" SG_ 2566835072 MalfunctionIndicatorLampStatus 4;
BA_ "SPN" SG_ 2566835072 RedStopLampState 623;
BA_ "SigType" SG_ 2566835072 RedStopLampState 4;
BA_ "SPN" SG_ 2566835072 AmberWarningLampStatus 624;
BA_ "SigType" SG_ 2566835072 AmberWarningLampStatus 4;
BA_ "SPN" SG_ 2566835072 ProtectLampStatus 987;
BA_ "SigType" SG_ 2566835072 ProtectLampStatus 4;
BA_ "SPN" SG_ 2566835072 FlashRedStopLamp 3039;
BA_ "SPN" SG_ 2566835072 FlashProtectLamp 3041;
BA_ "SPN" SG_ 2566835072 FlashMalfuncIndicatorLamp 3038;
BA_ "SigType" SG_ 2566835072 FlashMalfuncIndicatorLamp 4;
BA_ "SPN" SG_ 2566835072 FlashAmberWarningLamp 3040;
BA_ "SigType" SG_ 2566834816 DTC5 7;
BA_ "SigType" SG_ 2566834816 DTC4 7;
BA_ "SigType" SG_ 2566834816 DTC3 7;
BA_ "SigType" SG_ 2566834816 DTC2 7;
BA_ "SigType" SG_ 2566834816 DTC1 7;
BA_ "SPN" SG_ 2566834816 FlashRedStopLamp 3039;
BA_ "SPN" SG_ 2566834816 FlashProtectLamp 3041;
BA_ "SPN" SG_ 2566834816 FlashMalfuncIndicatorLamp 3038;
BA_ "SigType" SG_ 2566834816 FlashMalfuncIndicatorLamp 4;
BA_ "SPN" SG_ 2566834816 FlashAmberWarningLamp 3040;
BA_ "SPN" SG_ 2566834816 MalfunctionIndicatorLampStatus 1213;
BA_ "SigType" SG_ 2566834816 MalfunctionIndicatorLampStatus 4;
BA_ "SPN" SG_ 2566834816 AmberWarningLampStatus 624;
BA_ "SigType" SG_ 2566834816 AmberWarningLampStatus 4;
BA_ "SPN" SG_ 2566834816 RedStopLampState 623;
BA_ "SigType" SG_ 2566834816 RedStopLampState 4;
BA_ "SPN" SG_ 2566834816 ProtectLampStatus 987;
BA_ "SigType" SG_ 2566834816 ProtectLampStatus 4;
BA_ "SPN" SG_ 2566838912 SoftwareID3 234;
BA_ "SigType" SG_ 2566838912 SoftwareID3 8;
BA_ "SPN" SG_ 2566838912 SoftwareID2 234;
BA_ "SigType" SG_ 2566838912 SoftwareID2 8;
BA_ "SPN" SG_ 2566838912 SoftwareID1 234;
BA_ "SigType" SG_ 2566838912 SoftwareID1 8;
BA_ "SPN" SG_ 2566838912 NmbrOfSftwrIdentificationFields 965;
BA_ "SigType" SG_ 2566838912 NmbrOfSftwrIdentificationFields 1;
BA_ "SigType" SG_ 2566768000 ECUHardwareID 8;
BA_ "SPN" SG_ 2566768000 ECUManufacturerName 4304;
BA_ "SigType" SG_ 2566768000 ECUManufacturerName 8;
BA_ "SPN" SG_ 2566768000 ECUType 2904;
BA_ "SigType" SG_ 2566768000 ECUType 8;
BA_ "SPN" SG_ 2566768000 ECULocation 2903;
BA_ "SigType" SG_ 2566768000 ECULocation 8;
BA_ "SPN" SG_ 2566768000 ECUSerialNumber 2902;
BA_ "SigType" SG_ 2566768000 ECUSerialNumber 8;
BA_ "SPN" SG_ 2566768000 ECUPartNumber 2901;
BA_ "SigType" SG_ 2566768000 ECUPartNumber 8;
BA_ "SigType" SG_ 2566835184 DTC5 7;
BA_ "SigType" SG_ 2566835184 DTC4 7;
BA_ "SigType" SG_ 2566835184 DTC3 7;
BA_ "SigType" SG_ 2566835184 DTC2 7;
BA_ "SigType" SG_ 2566835184 DTC1 7;
BA_ "SPN" SG_ 2566835184 MalfunctionIndicatorLampStatus 1213;
BA_ "SigType" SG_ 2566835184 MalfunctionIndicatorLampStatus 4;
BA_ "SPN" SG_ 2566835184 RedStopLampState 623;
BA_ "SigType" SG_ 2566835184 RedStopLampState 4;
BA_ "SPN" SG_ 2566835184 AmberWarningLampStatus 624;
BA_ "SigType" SG_ 2566835184 AmberWarningLampStatus 4;
BA_ "SPN" SG_ 2566835184 ProtectLampStatus 987;
BA_ "SigType" SG_ 2566835184 ProtectLampStatus 4;
BA_ "SPN" SG_ 2566835184 FlashRedStopLamp 3039;
BA_ "SPN" SG_ 2566835184 FlashProtectLamp 3041;
BA_ "SPN" SG_ 2566835184 FlashMalfuncIndicatorLamp 3038;
BA_ "SigType" SG_ 2566835184 FlashMalfuncIndicatorLamp 4;
BA_ "SPN" SG_ 2566835184 FlashAmberWarningLamp 3040;
BA_ "SigType" SG_ 2566834928 DTC5 7;
BA_ "SigType" SG_ 2566834928 DTC4 7;
BA_ "SigType" SG_ 2566834928 DTC3 7;
BA_ "SigType" SG_ 2566834928 DTC2 7;
BA_ "SigType" SG_ 2566834928 DTC1 7;
BA_ "SPN" SG_ 2566834928 FlashRedStopLamp 3039;
BA_ "SPN" SG_ 2566834928 FlashProtectLamp 3041;
BA_ "SPN" SG_ 2566834928 FlashMalfuncIndicatorLamp 3038;
BA_ "SigType" SG_ 2566834928 FlashMalfuncIndicatorLamp 4;
BA_ "SPN" SG_ 2566834928 FlashAmberWarningLamp 3040;
BA_ "SPN" SG_ 2566834928 MalfunctionIndicatorLampStatus 1213;
BA_ "SigType" SG_ 2566834928 MalfunctionIndicatorLampStatus 4;
BA_ "SPN" SG_ 2566834928 AmberWarningLampStatus 624;
BA_ "SigType" SG_ 2566834928 AmberWarningLampStatus 4;
BA_ "SPN" SG_ 2566834928 RedStopLampState 623;
BA_ "SigType" SG_ 2566834928 RedStopLampState 4;
BA_ "SPN" SG_ 2566834928 ProtectLampStatus 987;
BA_ "SigType" SG_ 2566834928 ProtectLampStatus 4;
VAL_ 3221225472 ErrorCodeLockUnlockMask9 1 "GeneralError" 0 "NoError" ;
VAL_ 3221225472 CertificateRevision 7 "NotAvailable" 3 "FourthRevision" 2 "ThirdRevision" 1 "SecondRevision" 0 "FirstRevision" ;
VAL_ 3221225472 CertificateLaboratoryType 7 "Not available" 2 "NA certifeid Laboratory" 1 "EU certified Laboratory" 0 "Non-certified Laboratory" ;
VAL_ 3221225472 CertTypeVTWorkingSetMember 1 "CertificationTestPerformed" 0 "NotCertified" ;
VAL_ 3221225472 CertTypeVTWorkingSetMaster 1 "CertificationTestPerformed" 0 "NotCertified" ;
VAL_ 3221225472 CertTypeVirtualTerminal 1 "CertificationTestPerformed" 0 "NotCertified" ;
VAL_ 3221225472 CertTypeClass3ECU 1 "CertificationTestPerformed" 0 "NotCertified" ;
VAL_ 3221225472 CertTypeTECUClass3 1 "CertificationTestPerformed" 0 "NotCertified" ;
VAL_ 3221225472 CertTypeTECUClass2 1 "CertificationTestPerformed" 0 "NotCertified" ;
VAL_ 3221225472 CertTypeTECUClass1 1 "CertificationTestPerformed" 0 "NotCertified" ;
VAL_ 3221225472 CertTypeMinimumECU 1 "CertificationTestPerformed" 0 "NotCertified" ;
VAL_ 3221225472 CertTypeGPSReceiver 1 "CertificationTestPerformed" 0 "NotCertified" ;
VAL_ 3221225472 CertTypeFileServer 1 "CertificationTestPerformed" 0 "NotCertified" ;
VAL_ 3221225472 CertTypeTCWorkingSetMember 1 "CertificationTestPerformed" 0 "NotCertified" ;
VAL_ 3221225472 CertTypeTCWorkingSetMaster 1 "CertificationTestPerformed" 0 "NotCertified" ;
VAL_ 3221225472 CertTypeTaskController 1 "CertificationTestPerformed" 0 "NotCertified" ;
VAL_ 3221225472 CertificationReferenceNumber 1 "CertificationTestPerformed" 0 "NotCertified" ;
VAL_ 2566734464 CertLaboratoryType_FirstDef 7 "Not available (not certified) " 0 "Non-certified laboratory/self-test" 1 "AEF certified laboratory " 2 "Reserved " ;
VAL_ 2566734464 MessageRevision 1 "Third and later edition message revision" 0 "Format of message in second edition." ;
VAL_ 2566734464 CertLaboratoryType_SecondDef 3 "Not available (not certified) " 0 "Non-certified Laboratory/self-certification" 1 "AEF certified laboratory " 2 "Reserved " ;
VAL_ 2566734464 TestProtocolRevision 0 "FirstRevision" 1 "SecondRevision" 2 "ThirdRevision" 3 "NotAvailable" ;
VAL_ 2566734464 CertTypeVTWorkingSetMember 0 "NotCertified" 1 "CertificationTestPerformed" ;
VAL_ 2566734464 CertTypeVTWorkingSetMaster 0 "NotCertified" 1 "CertificationTestPerformed" ;
VAL_ 2566734464 CertTypeVirtualTerminal 0 "NotCertified" 1 "CertificationTestPerformed" ;
VAL_ 2566734464 CertTypeClass3ECU 0 "NotCertified" 1 "CertificationTestPerformed" ;
VAL_ 2566734464 CertTypeTECUClass3 0 "NotCertified" 1 "CertificationTestPerformed" ;
VAL_ 2566734464 CertTypeTECUClass2 0 "NotCertified" 1 "CertificationTestPerformed" ;
VAL_ 2566734464 CertTypeTECUClass1 0 "NotCertified" 1 "CertificationTestPerformed" ;
VAL_ 2566734464 CertTypeMinimumECU 0 "NotCertified" 1 "CertificationTestPerformed" ;
VAL_ 2566734464 CertTypeGPSReceiver 0 "NotCertified" 1 "CertificationTestPerformed" ;
VAL_ 2566734464 CertTypeFileServer 0 "NotCertified" 1 "CertificationTestPerformed" ;
VAL_ 2566734464 CertTypeTCWorkingSetMember 0 "NotCertified" 1 "CertificationTestPerformed" ;
VAL_ 2566734464 CertTypeTCWorkingSetMaster 0 "NotCertified" 1 "CertificationTestPerformed" ;
VAL_ 2566734464 CertTypeTaskController 0 "NotCertified" 1 "CertificationTestPerformed" ;
VAL_ 2566734464 CertificationReferenceNumber 0 "NotCertified" 1 "CertificationTestPerformed" ;
VAL_ 2566734576 CertLaboratoryType_FirstDef 7 "Not available (not certified) " 0 "Non-certified laboratory/self-test" 1 "AEF certified laboratory " 2 "Reserved " ;
VAL_ 2566734576 MessageRevision 1 "Third and later edition message revision" 0 "Format of message in second edition." ;
VAL_ 2566734576 CertLaboratoryType_SecondDef 3 "Not available (not certified) " 0 "Non-certified Laboratory/self-certification" 1 "AEF certified laboratory " 2 "Reserved " ;
VAL_ 2566734576 TestProtocolRevision 0 "FirstRevision" 1 "SecondRevision" 2 "ThirdRevision" 3 "NotAvailable" ;
VAL_ 2566734576 CertTypeVTWorkingSetMember 0 "NotCertified" 1 "CertificationTestPerformed" ;
VAL_ 2566734576 CertTypeVTWorkingSetMaster 0 "NotCertified" 1 "CertificationTestPerformed" ;
VAL_ 2566734576 CertTypeVirtualTerminal 0 "NotCertified" 1 "CertificationTestPerformed" ;
VAL_ 2566734576 CertTypeClass3ECU 0 "NotCertified" 1 "CertificationTestPerformed" ;
VAL_ 2566734576 CertTypeTECUClass3 0 "NotCertified" 1 "CertificationTestPerformed" ;
VAL_ 2566734576 CertTypeTECUClass2 0 "NotCertified" 1 "CertificationTestPerformed" ;
VAL_ 2566734576 CertTypeTECUClass1 0 "NotCertified" 1 "CertificationTestPerformed" ;
VAL_ 2566734576 CertTypeMinimumECU 0 "NotCertified" 1 "CertificationTestPerformed" ;
VAL_ 2566734576 CertTypeGPSReceiver 0 "NotCertified" 1 "CertificationTestPerformed" ;
VAL_ 2566734576 CertTypeFileServer 0 "NotCertified" 1 "CertificationTestPerformed" ;
VAL_ 2566734576 CertTypeTCWorkingSetMember 0 "NotCertified" 1 "CertificationTestPerformed" ;
VAL_ 2566734576 CertTypeTCWorkingSetMaster 0 "NotCertified" 1 "CertificationTestPerformed" ;
VAL_ 2566734576 CertTypeTaskController 0 "NotCertified" 1 "CertificationTestPerformed" ;
VAL_ 2566734576 CertificationReferenceNumber 0 "NotCertified" 1 "CertificationTestPerformed" ;
VAL_ 2365391614 StopAllImplOpSwitchState 0 "StopImplementOperations" 1 "PermitAllImplementsToON " 2 "ErrorIndication" 3 "NotAvailable " ;
VAL_ 2632384130 AssignedAttribute2OfSet1 1 "InputIsAssigned" ;
VAL_ 2632384130 AssignedAttribute1OfSet1 0 "AuxiliaryInput" 1 "AuxiliaryFunction" ;
VAL_ 2632384130 StoreAsPreferredAssignment 0 "StoreAssignment" 1 "DoNotStoreAssignment" ;
VAL_ 2632384130 ErrorCodeChangeAttribute5 1 "GeneralError" 0 "NoErrors" ;
VAL_ 2632384130 IndustryGroup 7 "Reserved for SAE" 5 "IndustrialProcessCtrlStationary" 4 "Marine" 3 "Construction" 2 "Agricultural and Forestry" 1 "On-Highway" 0 "Global" ;
VAL_ 2632384130 FontType_ProportionalFont 1 "Supported" 0 "NotSupported" ;
VAL_ 2632384130 FontType_FlashHidden 1 "Supported" 0 "NotSupported" ;
VAL_ 2632384130 FontType_FlashInverted 1 "Supported" 0 "NotSupported" ;
VAL_ 2632384130 FontType_InvertedText 1 "Supported" 0 "NotSupported" ;
VAL_ 2632384130 ErrorCodeChangePolygonScale5 0 "NoError" 1 "GeneralError" ;
VAL_ 2632384130 FontType_ItalicsText 1 "Supported" 0 "NotSupported" ;
VAL_ 2632384130 FontType_UnderlinedText 1 "Supported" 0 "NotSupported" ;
VAL_ 2632384130 FontType_CrossedOutText 1 "Supported" 0 "NotSupported" ;
VAL_ 2632384130 OperatingState2 0 "InputNotActivatedInLearnMode" 1 "InputActivatedInLearnMode" ;
VAL_ 2632384130 FontType_BoldText 1 "Supported" 0 "NotSupported" ;
VAL_ 2632384130 ErrorCodeChangePolygonScale1 0 "NoError" 1 "InvalidObjectId" ;
VAL_ 2632384130 OperatingState1 0 "LearnModeInactive" 1 "LearnModeActive" ;
VAL_ 2632384130 VTBusyCode8 1 "VTIsOutOfMemory" ;
VAL_ 2632384130 FontSize_128x192 1 "Supported" 0 "NotSupported" ;
VAL_ 2632384130 VTBusyCode7 1 "AuxiliaryControlsLearnModeActive" ;
VAL_ 2632384130 FontSize_128x128 1 "Supported" 0 "NotSupported" ;
VAL_ 2632384130 VTBusyCode5 1 "VTIsBusyParsingAnObjectPool" ;
VAL_ 2632384130 FontSize_96x128 1 "Supported" 0 "NotSupported" ;
VAL_ 2632384130 ErrorCodeGetSupportedWideChars2 0 "NoError" 1 "GeneralError" ;
VAL_ 2632384130 ErrorCodeChangeListItem5 1 "ValueInUse" 0 "NoErrors" ;
VAL_ 2632384130 ErrorCodeChangeListItem4 1 "ValueInUse" 0 "NoErrors" ;
VAL_ 2632384130 VTBusyCode4 1 "VTIsBusyExecutingMacro" ;
VAL_ 2632384130 FontSize_64x96 1 "Supported" 0 "NotSupported" ;
VAL_ 2632384130 ErrorCodeObjectPool4 1 "ObjectPoolWasDeletedFromVolatile" 0 "NoErrors" ;
VAL_ 2632384130 VTBusyCode3 1 "VTIsBusyExecutingCommand" ;
VAL_ 2632384130 FontSize_64x64 1 "Supported" 0 "NotSupported" ;
VAL_ 2632384130 ErrorCodeChangeListItem3 1 "InvalidNewListItemObjectID" 0 "NoErrors" ;
VAL_ 2632384130 ErrorCodeObjectPool3 1 "GeneralError" 0 "NoErrors" ;
VAL_ 2632384130 VTBusyCode2 1 "VTIsBusySavingDataToNonVolMemory" ;
VAL_ 2632384130 FontSize_48x64 1 "Supported" 0 "NotSupported" ;
VAL_ 2632384130 ErrorCodeChangeListItem2 1 "InvalidListIndex" 0 "NoErrors" ;
VAL_ 2632384130 ErrorCodeObjectPool2 1 "UnknownObjectReference" 0 "NoErrors" ;
VAL_ 2632384130 VTBusyCode1 1 "VTIsBusyUpdatingVisibleMask" ;
VAL_ 2632384130 FontSize_32x48 1 "Supported" 0 "NotSupported" ;
VAL_ 2632384130 ErrorCodeGetSupportedWideChars1 0 "NoError" 1 "TooManyRanges" ;
VAL_ 2632384130 ErrorCodeChangeListItem1 1 "InvalidListObjectID" 0 "NoErrors" ;
VAL_ 2632384130 Function 43 "Transmission Display" 44 "Exhaust Emission Control" 45 "Vehicle Dynamic Stability Control" 46 "Oil Sensor Unit" 47 "Information System Controller" 48 "Ramp Control" 49 "Clutch/Converter Control" 50 "Auxiliary Heater" 51 "Forward-Looking Collision Warning System" 52 "Chassis Controller" 53 "Alternator/Charging System" 54 "Communications Unit, Cellular" 55 "Communications Unit, Satellite" 56 "Communications Unit, Radio" 57 "Steering Column Unit" 58 "Fan Drive Control" 59 "Starter" 60 "Cab Display" 61 "File Server/Printer" 62 "On-Board Diagnostic Unit" 63 "Engine Valve Controller" 64 "Endurance Braking" 65 "Gas Flow Measurement" 66 "I/O Controller" 67 "Electrical System Controller" 68 "Aftertreatment system gas measurement" 69 "Engine Emission Aftertreatement System" 70 "Auxiliary Regeneration Device" 71 "Transfer Case Control" 72 "Coolant Valve Controller" 73 "Rollover Detection Control" 74 "Lubrication System" 75 "Supplemental Fan" 76 "Temperature Sensor" 77 "Fuel Properties Sensor" 78 "Fire Suppression System" 79 "Power Systems Manager" 80 "Electric Powertrain" 81 "Hydraulic Powertrain" 82 "File Server" 83 "Printer" 84 "Start Aid Device" 85 "Engine Injection Control Module" 86 "Reserved" 87 "Reserved" 88 "Reserved" 89 "Reserved" 90 "Reserved" 91 "Reserved" 92 "Reserved" 93 "Reserved" 94 "Reserved" 95 "Reserved" 96 "Reserved" 97 "Reserved" 98 "Reserved" 99 "Reserved" 100 "Reserved" 0 "Engine" 1 "Auxiliary Power Unit (APU)" 2 "Electric Propulsion Control" 3 "Transmission" 4 "Battery Pack Monitor" 5 "Shift Control/Console" 6 "Power TakeOff - (Main or Rear)" 7 "Axle - Steering" 8 "Axle - Drive" 9 "Brakes - System Controller" 10 "Brakes - Steer Axle" 11 "Brakes - Drive Axle" 12 "Retarder - Engine" 13 "Retarder - Driveline" 14 "Cruise Control" 15 "Fuel System" 16 "Steering Controller" 17 "Suspension - Steer Axle" 18 "Suspension - Drive Axle" 19 "Instrument Cluster" 20 "Trip Recorder" 21 "Cab Climate Control" 22 "Aerodynamic Control" 23 "Vehicle Navigation" 24 "Vehicle Security" 25 "Network Interconnect ECU" 26 "Body Controller" 27 "Power TakeOff (Secondary or Front)" 28 "Off Vehicle Gateway" 29 "Virtual Terminal (in cab)" 30 "Management Computer" 31 "Propulsion Battery Charger" 32 "Headway Controller" 33 "System Monitor" 34 "Hydraulic Pump Controller" 35 "Suspension - System Controller" 36 "Pneumatic - System Controller" 37 "Cab Controller" 38 "Tire Pressure Control" 39 "Ignition Control Module" 40 "Seat Control" 41 "Lighting - Operator Controls" 42 "Water Pump Control" 101 "Reserved" 102 "Reserved" 103 "Reserved" 104 "Reserved" 105 "Reserved" 106 "Reserved" 107 "Reserved" 108 "Reserved" 109 "Reserved" 110 "Reserved" 111 "Reserved" 112 "Reserved" 113 "Reserved" 114 "Reserved" 115 "Reserved" 116 "Reserved" 117 "Reserved" 118 "Reserved" 119 "Reserved" 120 "Reserved" 121 "Reserved" 122 "Reserved" 123 "Reserved" 124 "Reserved" 125 "Reserved" 126 "Reserved" 127 "Reserved" 255 "Not Available" ;
VAL_ 2632384130 ErrorCodeObjectPool1 1 "MethodOrAttributeNotSupportedByV" 0 "NoErrors" ;
VAL_ 2632384130 SoftKeyCode 0 "AlarmACK" ;
VAL_ 2632384130 BooleanValue 0 "Disabled" 1 "Enabled" 2 "EnabledStillHeld" ;
VAL_ 2632384130 Status_2 0 "Hidden" 1 "Shown" ;
VAL_ 2632384130 ErrorCodeVTChangeSoftKeyMask6 1 "PoolBeingDeleted" 0 "NoError" ;
VAL_ 2632384130 FontSize_32x32 1 "Supported" 0 "NotSupported" ;
VAL_ 2632384130 FontSize_24x32 1 "Supported" 0 "NotSupported" ;
VAL_ 2632384130 FontSize_16x24 1 "Supported" 0 "NotSupported" ;
VAL_ 2632384130 ErrorCodeChangePosInvalidError 1 "GeneralError" 0 "NoErrors" ;
VAL_ 2632384130 ErrorCodeChangeSoftKeyMask5 1 "GeneralError" 0 "NoErrors" ;
VAL_ 2632384130 ErrorCodeChangeChildLocation5 1 "GeneralError" 0 "NoErrors" ;
VAL_ 2632384130 ErrorCodeVTChangeSoftKeyMask5 1 "GeneralError" 0 "NoError" ;
VAL_ 2632384130 ErrorCodeChangeStrValueInUse 1 "ValueInUse" 0 "NoErrors" ;
VAL_ 2632384130 ErrorCodeVtObjPoolError4 1 "OtherError" 0 "NoErrors" ;
VAL_ 2632384130 FontSize_16x16 1 "Supported" 0 "NotSupported" ;
VAL_ 2632384130 ErrorCodeChangeStrError 1 "GeneralError" 0 "NoErrors" ;
VAL_ 2632384130 ErrorCodeChangeSoftKeyMask4 1 "Mask or child object has errors" 0 "NoErrors" ;
VAL_ 2632384130 ErrorCodeVTChangeSoftKeyMask4 1 "MaskOrChildObjectHasErrors" 0 "NoError" ;
VAL_ 2632384130 ErrorCodeVtObjPoolError3 1 "RecursiveObjectReference" 0 "NoErrors" ;
VAL_ 2632384130 FontSize_12x16 1 "Supported" 0 "NotSupported" ;
VAL_ 2632384130 ErrorCodeChangeStrTooLong 1 "StringTooLong" 0 "NoErrors" ;
VAL_ 2632384130 ErrorCodeChangeSoftKeyMask3 1 "Missing Objects" 0 "NoErrors" ;
VAL_ 2632384130 ErrorCodeVTChangeSoftKeyMask3 1 "MissingObjects" 0 "NoError" ;
VAL_ 2632384130 ErrorCodeVtObjPoolError2 1 "UnknownObjectReference" 0 "NoErrors" ;
VAL_ 2632384130 FontSize_8x12 1 "Supported" 0 "NotSupported" ;
VAL_ 2632384130 ErrorCodeChangePosInvalidObject 1 "InvalidObjectID" 0 "NoErrors" ;
VAL_ 2632384130 ErrorCodeChangeStrObjectID 1 "InvalidObjectID" 0 "NoErrors" ;
VAL_ 2632384130 ErrorCodeChangeSoftKeyMask2 1 "InvalidSoftKeyMaskObjectID" 0 "NoErrors" ;
VAL_ 2632384130 ErrorCodeChangeChildLocation2 1 "InvalidObjectID" 0 "NoErrors" ;
VAL_ 2632384130 ErrorCodeVTChangeSoftKeyMask2 1 "InvalidSoftKeyMaskObjectID" 0 "NoError" ;
VAL_ 2632384130 ErrorCodeVtObjPoolError1 1 "UnsupportedMethodOrAttribute" 0 "NoErrors" ;
VAL_ 2632384130 AcknowledgmentDeleteVersion 8 "GeneralError" 4 "NA" 2 "VersionLabelIsNotCorrect" 0 "SuccessfullyDeleted" ;
VAL_ 2632384130 AcknowledgmentLoadVersion 8 "GeneralError" 4 "InsufficientMemoryAvailable" 2 "VersionLabelNotCorrectOrUnknown" 0 "SuccessfullyLoaded" ;
VAL_ 2632384130 AcknowledgmentStoreVersion 8 "GeneralError" 4 "InsufficientMemoryAvailable" 2 "VersionLabelIsNotCorrect" 0 "SuccessfullyStored" ;
VAL_ 2632384130 FontSize_8x8 1 "Supported" 0 "NotSupported" ;
VAL_ 2632384130 ErrorCodeChangePosInvalidParent 1 "InvalidParentObjectID" 0 "NoErrors" ;
VAL_ 2632384130 ErrorCodeChangeSoftKeyMask1 1 "InvalidDataOrAlarmMaskObjectID" 0 "NoErrors" ;
VAL_ 2632384130 ErrorCodeChangeChildLocation1 1 "InvalidParentObjectID" 0 "NoErrors" ;
VAL_ 2632384130 TouchState 0 "Released" 1 "Pressed" 2 "Held" 255 "Pressed" ;
VAL_ 2632384130 ErrorCodeVTChangeSoftKeyMask1 1 "InvalidDataOrAlarmMaskObjectID" 0 "NoError" ;
VAL_ 2632384130 ErrorCodeSelectObject6 1 "InvalidOptionValue" 0 "NoErrors" ;
VAL_ 2632384130 ErrorCodeGraphicsContextCmd5 0 "NoError" 1 "GeneralError" ;
VAL_ 2632384130 ErrorCodeChangePriority3 1 "GeneralError" 0 "NoErrors" ;
VAL_ 2632384130 ErrorCodeChangeAttribute4 1 "ValueInUse" 0 "NoErrors" ;
VAL_ 2632384130 ErrorCodeChangeColour3 1 "GeneralError" 0 "NoErrors" ;
VAL_ 2632384130 ErrorCodeSelectObject5 1 "GeneralError" 0 "NoErrors" ;
VAL_ 2632384130 ErrorCodeEnableDisableObj4 1 "GeneralError" 0 "NoErrors" ;
VAL_ 2632384130 ErrorCodeGraphicsContextCmd4 0 "NoError" 1 "CommandWillProduceInvalidResults" ;
VAL_ 2632384130 ErrorCodeSelectObject4 1 "CouldNotComplete" 0 "NoErrors" ;
VAL_ 2632384130 ErrorCodeEnableDisableObj3 0 "NoErrors" 1 "Could not complete. Operator inp" ;
VAL_ 2632384130 ErrorCodeHideShowObj3 1 "GeneralError" 0 "NoErrors" ;
VAL_ 2632384130 ErrorCodeGraphicsContextCmd3 0 "NoError" 1 "InvalidParameter" ;
VAL_ 2632384130 ErrorCodeChangeAttribute3 1 "InvalidValue" 0 "NoErrors" ;
VAL_ 2632384130 ErrorCodeSelectObject3 1 "ObjectIsNotVisible" 0 "NoErrors" ;
VAL_ 2632384130 ErrorCodeEnableDisableObj2 1 "CommandError" 0 "NoErrors" ;
VAL_ 2632384130 ErrorCodeGraphicsContextCmd2 0 "NoError" 1 "InvalidCommandID" ;
VAL_ 2632384130 ErrorCodeChangePriority2 1 "InvalidPriority" 0 "NoErrors" ;
VAL_ 2632384130 ErrorCodeChangeAttribute2 1 "InvalidAttributeID" 0 "NoErrors" ;
VAL_ 2632384130 ErrorCodeChangeColour2 1 "InvalidColourCode" 0 "NoErrors" ;
VAL_ 2632384130 ErrorCodeSelectObject2 1 "InvalidObjectID" 0 "NoErrors" ;
VAL_ 2632384130 ErrorCodeEnableDisableObj1 1 "InvalidObjectID" 0 "NoErrors" ;
VAL_ 2632384130 ErrorCodeHideShowObj2 1 "InvalidObjectID" 0 "NoErrors" ;
VAL_ 2632384130 ErrorCodeGraphicsContextCmd1 0 "NoError" 1 "InvalidObjectID" ;
VAL_ 2632384130 ErrorCodeChangePriority1 1 "InvalidObjectID" 0 "NoErrors" ;
VAL_ 2632384130 ErrorCodeChangeAttribute1 1 "InvalidObjectID" 0 "NoErrors" ;
VAL_ 2632384130 ErrorCodeChangeColour1 1 "InvalidObjectID" 0 "NoErrors" ;
VAL_ 2632384130 ErrorCodeSelectObject1 0 "NoErrors" 1 "ObjectIsDisabled" ;
VAL_ 2632384130 ErrorCodeHideShowObj1 1 "ReferencesToMissingObjects" 0 "NoErrors" ;
VAL_ 2632384130 VTSelectInputObjectIsEdited 1 "ObjectIsOpenForEditing" 0 "ObjectIsNotEdited" ;
VAL_ 2632384130 ButtonObjectParentID 2 "KeyIsStillPressed" 1 "KeyHasBeenPressed" 0 "KeyHasBeenReleased" ;
VAL_ 2632384130 KeyObjectParentID 2 "KeyIsStillPressed" 1 "KeyHasBeenPressed" 0 "KeyHasBeenReleased" ;
VAL_ 2632384130 Hardware6 1 "VT supports intermediate coordinates during a drag operation" 0 "VT does not support intermediate coordinates during a drag operation" ;
VAL_ 2632384130 ErrorCodeChangeFont6 1 "GeneralError" 0 "NoErrors" ;
VAL_ 2632384130 ManufacturerCode 234 "Mondial electronic GmbH" 235 "SailorMade Marine Telemetry - Tetra Technology Ltd." 236 "Norac Systems International Inc" 237 "Agtron Enterprises Inc" 238 "ZF Friedrichshafen AG" 239 "May & Scofield Ltd" 240 "Vanair Mfg" 241 "Schneider Automation SAS " 242 "Kokusandenki Co. Ltd" 243 "eRide, Inc." 244 "Techno-Matic" 245 "Capstan Ag Systems, Inc." 246 "Class 1, Inc" 247 "ePULSE" 248 "Cooper Standard Automotive Active Systems Group" 264 "Autolync" 265 "MTS Sensor Technologie GmbH" 266 "International Thermal Research Ltd" 267 "Red Lion Controls, Inc" 268 "Accurate Technologies" 269 "Saft America Inc.,  Space & Defense Division" 270 "Tennant" 271 "Cole Hersee" 312 "Lectronix, Inc." 313 "Ilmor Engineering, Inc" 314 "CSM GmbH" 315 "Icom Incorporated" 316 "ITT Flow Control" 317 "Navtronics Bvba" 318 "SAT Plan" 319 "Cadec Global" 320 "Miedema Landbouwwerktuigenfabriek B.V." 321 "Ultra Electronics, Electrics" 322 "MICHENKA s.r.o." 323 "Mobileye Vision Technologies Ltd." 324 "Snap-on Diagnostics" 325 "ASM Automation Sensorik Messtechnik GmbH" 326 "Akron Brass Company" 327 "Sonceboz SA" 272 "Gross Mechanical Laboratories, Inc" 273 "Active Research Limited" 274 "LTW Technology Co., LTD" 275 "Navico Egersund AS" 276 "Aqua-Hot Heating Systems" 277 "LHP Telematics" 278 "Takata Electronics" 279 "Geometris LP" 280 "Leica Geosystems Pty Ltd" 299 "Rauch Landmaschinen GmbH" 300 "Systron Donner Automotive" 301 "Parker Hannifin (UK) Ltd FDE group" 302 "Nissin Kogyo Co., LTD" 303 "CTS Corporation" 304 "EmpirBus AB" 305 "NovAtel Inc" 306 "Sleipner Motor AB" 307 "MBW Technologies" 308 "Cyntrx" 309 "Krauss-Maffei Wegmann GmbH & Co. KG" 310 "TECNORD srl" 311 "Patrick Power Products" 281 "Precision Governors LLC" 282 "Medallion Instrumentation Systems" 283 "CWF Hamilton & Co Ltd" 284 "Mobile Tech Chile" 285 "Sea Recovery Corp" 286 "Coelmo srl" 287 "NTech Industries, Inc" 288 "Mitsubishi FUSO Truck & Bus Corp." 289 "Watlow" 290 "Kuebler GmbH" 291 "Groeneveld Transport Efficiency BV" 292 "IKUSI - Angel Iglesias S.A." 293 "Spyder Controls Corp." 294 "Grayhill Inc." 295 "BEP Marine" 296 "micro dynamics GmbH" 297 "Zonar Systems Inc" 298 "Holley Performance" 253 "Mobile Control Systems" 254 "GE Sensing" 255 "MEAS France" 256 "Tyco Electronics AMP" 257 "Honda Motor Co., Ltd" 258 "ARAG" 259 "Jetter AG" 260 "Reichhardt GmbH" 261 "Red Dot Corporation" 262 "HydraForce, Inc" 263 "IMMI" 223 "Vaueo Retarder Co., Ltd." 224 "EMMI Network, S.L." 225 "SKF" 226 "Monaco Coach Corporation" 227 "Lykketronic A/S" 228 "ZF Marine Electronics" 229 "Garmin International Inc." 230 "Saucon Technologies" 231 "Topcon Positioning Systems, Inc." 0 "Reserved" 1 "Allied Signal Inc." 2 "Allison Transmission, GMC" 3 "Ametek, US Gauge Division" 4 "Ametek-Dixson" 5 "AMP Inc." 6 "Berifors Electronics AB" 7 "Case Corp." 8 "Caterpillar Inc." 9 "Chrysler Corp." 10 "Cummins Engine Co." 11 "Dearborn Group Inc." 12 "Deere & Company, Precision Farming" 13 "Delco Electronics" 14 "Detroit Diesel Corporation" 15 "Dickey-John Corp." 16 "Eaton Corp." 17 "Eaton Corp. Res & Dev" 18 "Eaton Corp, Transmission Division" 19 "Eaton Corp. Trucking Info Services" 20 "Eaton Ltd" 21 "Echilin Inc., Midland Brake Inc." 22 "Ford Motor Co., Electronic Concepts $ Systems" 23 "Ford Motor Co., Heavy Truck" 24 "Ford Motor Co., Vehicle Controls" 25 "Daimler Trucks North America LLC" 26 "General Motors Corp., Service Technology Group" 27 "GMC" 28 "Grote Ind. Inc." 29 "Hino Motors Ltd." 30 "Isuzu Motors Ltd." 31 "J Pollak Corp." 32 "Jacobs Vehicle Systems" 33 "John Deere" 34 "Kelsey Hayes Co." 35 "Kenworth Truck Co." 36 "Lucas Ltd." 37 "Mack Trucks Inc." 38 "Micro Processor Systems Inc." 39 "Microfirm Inc." 40 "Motorola AIEG Inc." 41 "Motorola Inc." 42 "International Truck and Engine Corp. Engine Electronics" 43 "International Truck and Engine Corp. Vehicle Electronics" 44 "Nippondenso Co. Ltd." 45 "PACCAR" 46 "Noregon Systems, Inc" 47 "Phillips Semiconductor" 48 "Pollak Alphabet" 49 "RE America Inc." 50 "Robert Bosch Corp" 51 "Robert Bosch GmbH" 52 "Meritor Automotive, Inc." 53 "Continental Automotive Systems US, Inc." 54 "Meritor Wabco" 55 "Ryder System Inc." 56 "SAIC" 57 "Sauer-Danfoss Co." 58 "SPX Corporation, OTC Division" 59 "VES Inc." 60 "Volvo Trucks North America Inc." 61 "Volvo Truck Corp." 62 "Wabco" 63 "ZF Industries Inc." 64 "unused" 65 "MAN Nutzfahrzeuge AG" 66 "John Deere Construction Equipment Division" 67 "Funk Manufacturing Company" 68 "Scania" 69 "Trimble Navigation" 70 "Flex-Coil Limited" 71 "Vansco Electronics Ltd." 72 "Sisu Corporation" 73 "LeTourneau, Inc." 74 "Eaton Axle-Brake Division" 75 "Deere & Co. Agricultural Division" 76 "unused" 77 "Deere Power Systems Group" 78 "Frank W. Murphy Manufacturing, Inc." 79 "Daimler Benz AG - Engine Division (PBM)" 80 "Twin Disc, Inc." 81 "Fire Research Corp" 82 "Bobcat/Ingersoll-Rand" 83 "Bendix VORAD Technologies" 84 "New Holland UK Limited" 85 "Kohler Co." 86 "C.E. Niehoff & Company" 87 "J.C. Bamford Excavators Ltd (JCB)" 88 "Satloc Precision GPS" 89 "Kverneland Group, Electronics Division" 90 "Knorr-Bremse SfN GmbH" 91 "BSG Bodensee Steuergeraete GmbH" 92 "Ag-Chem Equipment Co., Inc." 93 "Perkins Engines Company Ltd." 94 "CNH Global N.V." 95 "Pacific Insight Electronics Corp." 96 "Mech@tronic IT GmbH" 97 "Ag Leader Technology, Inc." 98 "Mueller-Elektronik GmbH & Co." 99 "International Transmissions Ltd (ITL)" 100 "VDO Technik AG" 101 "Sensoria" 102 "AGCO GmbH & Co." 103 "CLAAS Agrosystems GmbH & Co. KG" 104 "Claas Selbstfahrende Erntemaschinen GmbH" 105 "Kiepe Elektrik GmbH & Co. KG" 106 "BAE Systems Controls, Inc." 107 "Grimme Landmaschinen GmbH & Co. KG" 108 "WTK-Elecktronik GmbH" 109 "TeeJet Technologies Denmark" 110 "EPIQ Sensor-Nite" 111 "Maschinenfabrik Bernard Krone GmbH" 112 "MECALAC" 113 "Stress-Tek, Inc." 114 "EControls, Inc." 115 "NACCO Materials Handling Group, Inc." 116 "BEELINE Technologies" 117 "HUSCO International" 118 "Intron GmbH" 119 "IntegriNautics" 120 "RDS Technology Ltd." 121 "HED (Hydro Electronic Devices, Inc.)" 122 "FG Wilson (Engineering) Limited" 123 "Basler Electric" 124 "Hydac Electronic" 125 "Nevada Automotive Test Center" 126 "Driver Tech" 127 "Holland USA" 128 "Gerhard Duecker GmbH & Co. KG" 129 "OMNEX Control Systems, Inc." 130 "Nido - Universal Machines B.V." 131 "ITT Industries" 132 "Mulag-Fahrzeugwerk" 133 "Bucher Schoerling GmbH" 134 "Iris Technology Ltd." 135 "Airmar Technology Corporation" 136 "Komatsu Ltd." 137 "Maretron" 138 "Georg Fritzmeier GmbH & Co. KG" 139 "Caterpillar Trimble Control Technologies (CTCT), LLC" 140 "Lowrance Electronics, Inc." 141 "Thales Navigation Ltd." 142 "TRW Automotive (Commercial Steering Systems)" 143 "W. Gmeiner GmbH & Co." 144 "Mercury Marine" 145 "MurCal Controls" 146 "Maxima Technologies" 147 "Nautibus Electronic GmbH" 148 "Blue Water Data, Inc." 149 "Holset" 150 "Fleetguard" 151 "Raven Industries Inc. - Flow Controls Division" 152 "elobau GmbH & Co. KG" 153 "Woodward, Industrial Controls Division" 154 "Westerbeke Corporation" 155 "Vetronix Corporation" 156 "ITT Industries - Cannon" 157 "ISSPRO Inc." 158 "Firestone Industrial Products Company" 159 "NTech Industries Inc." 160 "Nido" 161 "Offshore Systems (UK) Limited" 162 "Axiomatic Technologies" 163 "BRP Inc." 164 "DaimlerChrysler Off-Highway" 165 "CPAC Systems AB" 166 "Phoenix International" 167 "JLG Industries Inc." 168 "Xantrex" 169 "Marlin Technologies Inc." 170 "Computronics Corporation Ltd." 171 "Wachendorff Elektronik GmbH & Co. KG" 172 "Yanmar Marine USA" 173 "Ryeso, Inc." 174 "AB Volvo Penta" 175 "Veris Technologies, Inc." 176 "Moritz Aerospace" 177 "Diagnostic System Associates" 178 "Siemens VDO Automotive AG" 179 "TeeJet Technologies Denmark" 180 "Smart Power Systems" 181 "Coretronics, Inc." 182 "Vehicle Systems Engineering B.V." 183 "KDS Controls, Inc." 184 "EIA Electronics" 185 "Beede Electrical Instrument Company" 186 "Altronic, Inc." 187 "Air-Weigh" 188 "EMP Corp." 189 "QUALCOMM" 190 "Hella KGaA Hueck & Co." 191 "XRS Corporation" 192 "Floscan" 193 "Nobletec" 194 "TriMark Corporation" 195 "General Engine Products" 196 "LEMKEN GmbH & Co. KG" 197 "Mechron Power Systems" 198 "Mystic Valley Communications" 199 "Actia Corp." 200 "MGM Brakes" 201 "Disenos y Tecnologia S.A." 202 "Curtis Instruments, Inc." 203 "MILtronik GmbH" 204 "The Morey Corporation" 205 "SmarTire Systems Inc" 206 "port GmbH" 207 "Otto Engineering" 208 "Drew Technologies, Inc." 209 "Bell Equip. Co. SA (PTY) LTD" 210 "Iteris, Inc." 211 "DNA Group" 212 "Sure Power Industries, Inc." 213 "CNH Belgium N.V." 214 "MC elettronica Srl" 215 "Aetna Engineering/Fireboy-Xintex" 216 "Paneltronics Inc." 217 "RM Michaelides Software & Elektronik GmbH" 218 "Gits Manufacturing Company" 219 "Cat OEM Solutions" 220 "Beede Electrical Instrument Company, Inc." 221 "SiE" 222 "Generac Power Systems, Inc." 1850 "Teleflex" 1851 "Raymarine" 1852 "Navionics" 1853 "Japan Radio Co." 1854 "Northstar Technologies" 1855 "Furuno USA" 1856 "Trimble" 1857 "Simrad" 1858 "Litton" 1859 "Kvasar AB" 1860 "MMP" 1861 "Vector North America" 1862 "Sanshin" 1863 "Thomas G. Faria Co." 232 "TSD Integrated Controls" 233 "Yacht Monitoring Solutions Inc." 249 "Schaltbau GmbH" 250 "Kuhn Group" 251 "German Agricultural Society" 252 "Sensor-Technik Wiedemann GmbH" 328 "Qwerty Electronik AB" 329 "Deif A/S" 330 "Kidde Aerospace and Defense" 331 "Horton, Inc." 332 "HWH Corporation" 333 "Hadley Products Corporation" 334 "Takata-Petri AG" 335 "Evo Electric Ltd" 336 "APE s.r.o." 337 "Carraro S.p.A." 338 "GRAF-SYTECO" 339 "Competence Center ISOBUS e.V." 340 "Continental AG" 341 "Boning GmbH & Co" 342 "THOMAS MAGNETE GmbH" 343 "Baumer Group" 344 "Parvus Corporation" 345 "Korean Maritime University" 346 "Control Solutions" 347 "Honeywell" 348 "Amazonen Werke H. Dreyer" 349 "Suonentiet" 350 "Noris Marine Systems GmbH & Co KG" 351 "Thrane & Thrane" 352 "SAME DEUTZ-FAHR" 353 "Hegemon Electronics, Inc." 354 "Junkkari OY" 355 "Mastervolt International B.V." 356 "Fischer Panda Generators, Inc" 357 "Hardi International A/S" 358 "Victron Energy BV" 359 "Ludwig Bergmann GmbH" 360 "HJS Emission Technology GmbH & Co KG" 361 "InMach" 362 "Alois Poettinger Maschinenfabrik GmbH" 363 "BEI Duncan" 364 "OEM Controls Inc." 365 "Digi-Star, LLC" 366 "Viewnyx Corp." 367 "Fliegl Agrartechnik" 368 "HANSENHOF_electronic" 369 "Power Torque Engineering Ltd" 370 "Rolls-Royce Marine AS" 371 "Heinzmann GmbH & Co. KG" 373 "Electronic Design Inc." 374 "Northern Lights, Inc." 381 "B&G" 372 "Delphi" 375 "Williams Controls Inc." 376 "Quake Global" 377 "ifm electronic gmbh" 378 "Glendinning Marine Products" 379 "Yamabiko Corporation" 380 "Suntech International Ltd." 382 "National Agricultural and Food Research Organization" 383 "MCL Industries" 384 "Camano Light" 385 "Johnson Outdoor Marine Electronics" 386 "JLG Automation BVBA" 387 "Orscheln Products, LLC" 388 "Innomatix, LLC" 389 "Benchmark Electronics, Minnesota Division" 390 "Partech Inc." 391 "Electronic Design for Industry, Inc" 392 "Tianyuan Technology Co Ltd." 393 "Harvest Tec, Inc" 394 "Capi 2 Nederland BV" 395 "GENTEC S.R.L." 396 "Beyond Measure" 397 "Sanyo-kiki Co Ltd." 398 "Hilite International" 399 "ISEKI & Co., Ltd." 400 "Livorsi Marine" 401 "Torqeedo GmbH" 402 "Simma Software, Inc." 403 "Trackwell ADS, Inc." 404 "Com Nav Marine Ltd" 405 "Wema System AS" 406 "Vecima Networks Inc." 407 "Comtech Mobile Datacom" 408 "Corvus Energy Ltd." 409 "Transfluid S.r.L." 410 "COBO S.p.A. Divisione 3B6" 411 "Hy-Drive Technologies Ltd." 412 "WebTech Wireless Inc." 413 "Datapross Nijbroek bv" 414 "Cattron Group International" 415 "Valid Manufacturing Ltd." 416 "Kubota Corporation" 417 "KZValve" 418 "Intellistick Inc" 419 "Fusion Electronics Ltd" 420 "Vermeer Corporation, ACS Group" 421 "Vertex Standard Co., Ltd" 422 "True Heading AB" 423 "BSM Wireless, Inc." 424 "Odyne LLC" 425 "Methode Electronics Inc, MDI" 426 "Egersund Marine Electronics AS" 427 "em-trak Marine Electronics Ltd" 428 "Mfg_428" 429 "Rota Engineering Ltd." 455 "ADZ NAGANO GmbH" 456 "General Kinetics" 457 "RUSELPROM-ElectricDrive Ltd" 458 "Control Solutions, Inc." 459 "Alltek Marine Electronics Corp" 460 "San Giorgio S.E.I.N." 461 "HAWE Hydraulik SE" 462 "IHI Shibaura Machinery Corporation" 463 "PROBOTIQ" 464 "Leach International Corporation" 465 "Ashcroft Inc" 466 "Veethree Electronics and Marine LLC" 467 "Lely Industries N.V." 468 "Tyco Fire Protection Products" 469 "RA Consulting GmbH" 470 "SI-TEX Marine Electronics" 471 "Sea Cross Marine AB" 472 "Tenneco Inc." 473 "Boss Industries, Inc." 474 "Persen Technologies Inc." 475 "GME" 476 "Hummingbird Marine Electronics" 477 "OilQuick AB" 478 "OceanSat BV" 479 "Vapor Bus International" 430 "Auteq Telematica S.A." 431 "Tohatsu Corporation" 432 "S&A Systems, Inc." 433 "Rowe Electronics" 434 "Stored Energy Systems" 435 "Zunhammer GmbH" 436 "Kinze Manufacturing" 437 "Digital Yacht Limited" 438 "Comar Systems Ltd" 439 "Hyundai Heavy Industries" 440 "Cummins Power Generation" 441 "PTG Reifendruckregelsysteme GmbH" 442 "Horsch Maschinen GmbH" 443 "SignalQuest, Inc." 444 "ITT Power Solutions" 445 "KAT MECHATRONIC, Electronic Product Division" 446 "CertTech, L.L.C." 447 "Great Plains Mfg." 448 "Stanadyne Corporation, Electronics Systems" 449 "Polaris Industries Inc" 450 "Dycor Technologies Ltd." 451 "Parker Hannifin Corp" 452 "WIKA Alexander Wiegand SE & Co. KG" 453 "Cooper Bussmann" 454 "NGK Spark Plug Co. Ltd" 480 "EnerDel, Inc." 481 "Chetco Digital Instruments" 482 "Tricon Electronics" 483 "Valeo" 484 "Headsight Inc." 485 "MATT automotive" 486 "Westport Innovations Inc." 487 "DSE Test Solutions A/S" 488 "The Charles Machine Works, Inc." 489 "Appareo Systems" 490 "QuikQ" 491 "Penny and Giles Ltd" 492 "Inergy Automotive Systems" 493 "Watcheye" 494 "Synerject" 495 "HOLMER Maschinenbau GmbH" 496 "W. Gessmann GmbH" 497 "SENTRON Sistemas Embarcados" 498 "Innovative Design Solutions, Inc." 499 "LCJ Capteurs" 500 "Oxbo International Corporation" 501 "Agrotronix S.A." 502 "Attwood Corporation" 503 "Naviop S.R.L." 504 "Vesper Marine" 505 "Yetter Farm Equipment" 506 "IHI STAR Machinery Corporation" 507 "Test Center ISOBUS" 508 "Transtech Innovations" 509 "MOTORTECH GmbH" 510 "Marinesoft Co. Ltd" 511 "Sulky" 512 "Inpower LLC" 513 "FarmscanAg" 514 "DISTek Integration, Inc." 515 "GINAF Trucks Nederland B.V." 516 "AVAT Automation GmbH" 517 "Noland Engineering" 518 "Transas USA Inc." 519 "Peeters Landbouwmachines b.v." 520 "Trapeze" ;
VAL_ 2632384130 ErrorCodePoolDeleted 1 "PoolBeingDeleted" 0 "NoErrors" ;
VAL_ 2632384130 Hardware5 1 "VT supports simultaneous activations of softkeys" 0 "VT does not support simultaneous activations of softkeys" ;
VAL_ 2632384130 ErrorCodeChangeActiveMask5 1 "GeneralError" 0 "NoErrors" ;
VAL_ 2632384130 ErrorCodeChangeFillAttributes5 1 "GeneralError" 0 "NoErrors" ;
VAL_ 2632384130 ErrorCodeChangeLineAttribute4 1 "GeneralError" 0 "NoErrors" ;
VAL_ 2632384130 ErrorCodeChangeFont5 1 "InvalidStyle" 0 "NoErrors" ;
VAL_ 2632384130 ErrorCodeChangeEditPoint3 1 "GeneralError" 0 "NoErrors" ;
VAL_ 2632384130 ErrorCodeObjToSize4 1 "GeneralError" 0 "NoErrors" ;
VAL_ 2632384130 ErrorCodeEscapeObj2 1 "GeneralError" 0 "NoErrors" ;
VAL_ 2632384130 ErrorCodeAnyOtherError 1 "GeneralError" 0 "NoErrors" ;
VAL_ 2632384130 ErrorCodeVTEsc2 1 "GeneralError" 0 "NoError" ;
VAL_ 2632384130 ErrorCodeChangeNumValue4 1 "ValueInUse" 0 "NoErrors" ;
VAL_ 2632384130 Hardware4 1 "VT has adjustable volume audio output" 0 "VT has no adjustable volume audio output" ;
VAL_ 2632384130 ErrorCodeChangeActiveMask4 1 "MaskOrChildObjectHasErrors" 0 "NoErrors" ;
VAL_ 2632384130 ErrorCodeChangeFillAttributes4 1 "InvalidPatternObjectID" 0 "NoErrors" ;
VAL_ 2632384130 ErrorCodeChangeFont4 1 "InvalidType" 0 "NoErrors" ;
VAL_ 2632384130 ErrorCodeMaskOrChildObjectError 1 "MaskOrChildObjectHasErrors" 0 "NoErrors" ;
VAL_ 2632384130 ErrorCodeChangeNumValue3 1 "ValueInUse" 0 "NoErrors" ;
VAL_ 2632384130 Hardware3 1 "VT has multiple frequency audio output" 0 "VT has no multiple frequency audio output" ;
VAL_ 2632384130 ErrorCodeChangePoygonPoint3 0 "NoError" 1 "GeneralError" ;
VAL_ 2632384130 ErrorCodeChangeActiveMask3 1 "MissingObjects" 0 "NoErrors" ;
VAL_ 2632384130 ErrorCodeChangeFillAttributes3 1 "InvalidColour" 0 "NoErrors" ;
VAL_ 2632384130 ErrorCodeChangeLineAttribute3 1 "InvalidWidth" 0 "NoErrors" ;
VAL_ 2632384130 ErrorCodeChangeFont3 1 "InvalidSize" 0 "NoErrors" ;
VAL_ 2632384130 ErrorCodeObjToSize3 1 "InvalidHeight" 0 "NoErrors" ;
VAL_ 2632384130 ErrorCodeMissingObjects 1 "MissingObjects" 0 "NoErrors" ;
VAL_ 2632384130 ErrorCodeExecuteExtendedMacro3 0 "NoError" 1 "GeneralError" ;
VAL_ 2632384130 Hardware2 1 "VT reports drag operation" 0 "VT does not report drag operation" ;
VAL_ 2632384130 ErrorCodeSelectColourMap2 0 "NoError" 1 "GeneralError" ;
VAL_ 2632384130 ErrorCodeChangePoygonPoint2 0 "NoError" 1 "InvalidPointIndex" ;
VAL_ 2632384130 ErrorCodeChangeActiveMask2 1 "InvalidMaskObjectID" 0 "NoErrors" ;
VAL_ 2632384130 ErrorCodeChangeFillAttributes2 1 "InvalidType" 0 "NoErrors" ;
VAL_ 2632384130 ErrorCodeChangeLineAttribute2 1 "InvalidObjectColour" 0 "NoErrors" ;
VAL_ 2632384130 ErrorCodeChangeFont2 1 "InvalidColour" 0 "NoErrors" ;
VAL_ 2632384130 ErrorCodeChangeEditPoint2 1 "InvalidLineDirection" 0 "NoErrors" ;
VAL_ 2632384130 ErrorCodeChangeNumValue2 1 "InvalidValue" 0 "NoErrors" ;
VAL_ 2632384130 ErrorCodeObjToSize2 1 "InvalidWidth" 0 "NoErrors" ;
VAL_ 2632384130 ErrorCodeExecuteExtendedMacro2 0 "NoError" 1 "ObjectIdIsNoMacro" ;
VAL_ 2632384130 Hardware1 1 "VT has a touch screen or pointing device" 0 "VT has no touch screen and no pointing device" ;
VAL_ 2632384130 ErrorCodeSelectColourMap1 0 "NoError" 1 "InvalidObjectID" ;
VAL_ 2632384130 SubCommandID 0 "SetGraphicsCursor" 1 "MoveGraphicsCursor" 2 "SetForegroundColour" 3 "SetBackgroundColour" 4 "SetLineAttributesObjectID" 5 "SetFillAttributesObjectID" 6 "SetFontAttributesID" 7 "EraseRectangle" 8 "DrawPoint" 9 "DrawLine" 10 "DrawRectangle" 11 "DrawClosedEllipse" 12 "DrawPolygon" 13 "DrawText" 14 "PanViewport" 15 "ZoomViewport" 16 "PanAndZoomViewport" 17 "ChangeViewportSize" 18 "DrawVTObject" 19 "CopyCanvasToPictureGraphic" 20 "CopyViewportToPictureGraphic" ;
VAL_ 2632384130 ErrorCodeChangePoygonPoint1 0 "NoError" 1 "InvalidObjectId" ;
VAL_ 2632384130 ErrorCodeChangeActiveMask1 1 "InvalidWorkingSetObject" 0 "NoErrors" ;
VAL_ 2632384130 ErrorCodeChangeFillAttributes1 1 "InvalidObjectID" 0 "NoErrors" ;
VAL_ 2632384130 ErrorCodeChangeLineAttribute1 1 "InvalidObjectID" 0 "NoErrors" ;
VAL_ 2632384130 ErrorCodeChangeFont1 1 "InvalidObjectID" 0 "NoErrors" ;
VAL_ 2632384130 ErrorCodeChangeEditPoint1 1 "InvalidObjectID" 0 "NoErrors" ;
VAL_ 2632384130 ErrorCodeChangeNumValue1 1 "InvalidObjectID" 0 "NoErrors" ;
VAL_ 2632384130 ErrorCodeObjToSize1 1 "InvalidObjectID" 0 "NoErrors" ;
VAL_ 2632384130 ObjectSelectStatus 1 "ObjectIsSelected" 0 "ObjectIsDeselectedOrObjectIDIsNullObject" 2 "ObjectIsOpenedForEdit" ;
VAL_ 2632384130 ObjectEnableStatus 1 "ObjectIsEnabled" 0 "ObjectIsDisabled" ;
VAL_ 2632384130 ObjectShowStatus 1 "ObjectIsShown" 0 "ObjectIsHidden" ;
VAL_ 2632384130 ErrorCodeEscapeObj1 1 "NoInputFieldIsOpenForInput" 0 "NoErrors" ;
VAL_ 2632384130 ErrorCodeVTEsc1 1 "NoInputFieldSelected ESC_Ignored" 0 "NoError" ;
VAL_ 2632384130 VTSelectInputObjectStatus 1 "ObjectIsSelected" 0 "ObjectIsDeselected" ;
VAL_ 2632384130 Status_1 0 "Hidden" 1 "Shown" ;
VAL_ 2632384130 ErrorCodeExecuteExtendedMacro1 0 "NoError" 1 "ObjectIdNotExist" ;
VAL_ 2632384130 ErrorCodeLockUnlockMask8 0 "NoError" 1 "GeneralError" ;
VAL_ 2632384130 ErrorCodeLockUnlockMask7 0 "NoError" 1 "UnsolicitedUnlock_OperatorInduce" ;
VAL_ 2632384130 ErrorCodeLockUnlockMask6 0 "NoError" 1 "UnsolicitedUnlock_MaskChanged" ;
VAL_ 2632384130 ErrorCodeLockUnlockMask5 0 "NoError" 1 "UnsolicitedUnlock_TimeoutOccured" ;
VAL_ 2632384130 ErrorCodeLockUnlockMask4 0 "NoError" 1 "AlarmMaskIsActive" ;
VAL_ 2632384130 ErrorCodeExecuteMacro3 0 "NoError" 1 "GeneralError" ;
VAL_ 2632384130 ErrorCodeLockUnlockMask3 0 "NoError" 1 "MaskNotLocked" ;
VAL_ 2632384130 ErrorCodeExecuteMacro2 0 "NoError" 1 "ObjectIdIsNoMacro" ;
VAL_ 2632384130 ErrorCodeLockUnlockMask2 0 "NoError" 1 "MaskAlreadyLocked" ;
VAL_ 2632384130 SupportedGraphicMode 2 "Colour256" 1 "Colour16" 0 "Monocrome" ;
VAL_ 2632384130 MemoryStatus 1 "NotEnoughMemoryAvailable" 0 "EnoughMemoryMayBeAvailable" ;
VAL_ 2632384130 ErrorCodeExecuteMacro1 0 "NoError" 1 "ObjectIdNotExist" ;
VAL_ 2632384130 ErrorCodeLockUnlockMask1 0 "NoError" 1 "MaskNotVisibleOrInvalidObjectId" ;
VAL_ 2632384130 ButtonObjectID 2 "KeyIsStillPressed" 1 "KeyHasBeenPressed" 0 "KeyHasBeenReleased" ;
VAL_ 2632384130 KeyObjectID 2 "KeyIsStillPressed" 1 "KeyHasBeenPressed" 0 "KeyHasBeenReleased" ;
VAL_ 2632384130 ErrorCodeSetObjectLabel6 0 "NoError" 1 "GeneralError" ;
VAL_ 2632384130 ErrorCodeSetObjectLabel5 0 "NoError" 1 "DesignatorReferencesInvalidObjects" ;
VAL_ 2632384130 ErrorCodeDeleteObjectPool2 1 "GeneralError" 0 "NoErrors" ;
VAL_ 2632384130 ErrorCodeAudioVolume2 1 "GeneralError" 0 "NoErrors" ;
VAL_ 2632384130 ErrorCodeControlAudioDevice2 1 "GeneralError" 0 "NoErrors" ;
VAL_ 2632384130 ErrorCodeEndOfObjectPool3 1 "GeneralError" 0 "NoErrors" ;
VAL_ 2632384130 AuxPreferredAssignmentRespError5 0 "NoErrors" 1 "GeneralError" ;
VAL_ 2632384130 ErrorCodeSetObjectLabel4 0 "NoError" 1 "InvalidDesignatorObjectReference" ;
VAL_ 2632384130 AuxPreferredAssignmentRespError4 0 "NoErrors" 1 "DuplicateObjectIdOfAuxFct" ;
VAL_ 2632384130 ErrorCodeSetObjectLabel3 0 "NoError" 1 "InvalidFontType" ;
VAL_ 2632384130 AuxPreferredAssignmentRespError3 0 "NoErrors" 1 "InputObjectID(s)NotValid" ;
VAL_ 2632384130 ErrorCodeSetObjectLabel2 0 "NoError" 1 "InvalidStringVariableObjectId" ;
VAL_ 2632384130 AuxPreferredAssignmentRespError2 0 "NoErrors" 1 "FunctionObjectID(s)NotValid" ;
VAL_ 2632384130 ErrorCodeEndOfObjectPool2 1 "VTRanOutOfMemoryDuringTransfer" 0 "NoErrors" ;
VAL_ 2632384130 VersionNumberISO11783Part6 50 "VersionOfThe50PublishedEdition" 49 "VersionOfThe48PublishedEdition" 48 "VersionOfThe47PublishedEdition" 47 "VersionOfThe46PublishedEdition" 46 "VersionOfThe45PublishedEdition" 45 "VersionOfThe44PublishedEdition" 44 "VersionOfThe43PublishedEdition" 43 "VersionOfThe42PublishedEdition" 42 "VersionOfThe41PublishedEdition" 41 "VersionOfThe40PublishedEdition" 40 "VersionOfThe39PublishedEdition" 39 "VersionOfThe38PublishedEdition" 38 "VersionOfThe37PublishedEdition" 37 "VersionOfThe36PublishedEdition" 36 "VersionOfThe35PublishedEdition" 35 "VersionOfThe34PublishedEdition" 34 "VersionOfThe33PublishedEdition" 33 "VersionOfThe32PublishedEdition" 32 "VersionOfThe31PublishedEdition" 31 "VersionOfThe30PublishedEdition" 30 "VersionOfThe29PublishedEdition" 29 "VersionOfThe28PublishedEdition" 28 "VersionOfThe27PublishedEdition" 27 "VersionOfThe26PublishedEdition" 26 "VersionOfThe25PublishedEdition" 25 "VersionOfThe24PublishedEdition" 24 "VersionOfThe23PublishedEdition" 23 "VersionOfThe22PublishedEdition" 22 "VersionOfThe21PublishedEdition" 21 "VersionOfThe20PublishedEdition" 20 "VersionOfThe19PublishedEdition" 19 "VersionOfThe18PublishedEdition" 18 "VersionOfThe17PublishedEdition" 17 "VersionOfThe16PublishedEdition" 16 "VersionOfThe15PublishedEdition" 15 "VersionOfThe14PublishedEdition" 14 "VersionOfThe13PublishedEdition" 13 "VersionOfThe12PublishedEdition" 12 "VersionOfThe11PublishedEdition" 11 "VersionOfThe10PublishedEdition" 10 "VersionOfThe9PublishedEdition" 9 "VersionOfThe8PublishedEdition" 8 "VersionOfThe7PublishedEdition" 7 "VersionOfThe6PublishedEdition" 6 "VersionOfThe5PublishedEdition" 5 "VersionOfThe4PublishedEdition" 4 "VersionOfThe3PublishedEdition" 3 "VersionOfThe2PublishedEdition" 2 "VersionOfThe1PublishedEdition" 1 "FDIS_Version" 0 "Hannover Agritechnica 2001 limit" ;
VAL_ 2632384130 LockUnlockCommand 0 "UnlockMask" 1 "LockMask" ;
VAL_ 2632384130 ErrorCodeSetObjectLabel1 0 "NoError" 1 "InvalidObjectId" ;
VAL_ 2632384130 ErrorCodeDeleteObjectPool1 1 "DeletionError" 0 "NoErrors" ;
VAL_ 2632384130 ErrorCodeAudioVolume1 1 "AudioDeviceIsBusy" 0 "NoErrors" ;
VAL_ 2632384130 ErrorCodeControlAudioDevice1 1 "AudioDeviceIsBusy" 0 "NoErrors" ;
VAL_ 2632384130 AuxPreferredAssignmentRespError1 0 "NoErrors" 1 "AuxiliaryInputUnit(s)NotValid" ;
VAL_ 2632384130 ErrorCodeEndOfObjectPool1 0 "NoErrors" 1 "ErrorsInTheObjectPool" ;
VAL_ 2632384130 ButtonActivationCode 2 "ButtonIsStillHeld" 1 "ButtonHasBeenLatched" 0 "ButtonHasBeenUnlatched" 3 "ButtonPressAborted" ;
VAL_ 2632384130 KeyActivationCode 2 "KeyIsStillPressed" 1 "KeyHasBeenPressed" 0 "KeyHasBeenReleased" 3 "KeyPressAborted" ;
VAL_ 2632384130 TerminationCause 1 "AudioWasTerminated" ;
VAL_ 2632384130 BootTime 255 "Information not available" ;
VAL_ 2632384130 VTFunctionVTtoECU 253 "VTUnsupportedVTFunction" 34 "AuxiliaryPreferredAssignmentResponse" 180 "ChangeChildPositionResponse" 179 "ChangeStringValueResponse" 240 "VTObjectPoolErrorMessage" 196 "GetWindowMaskDataResponse" 8 "VTChangeStringValue" 7 "VTChangeSoftKeyMask" 6 "VTChangeActiveMask" 5 "VTChangeNumericValue" 4 "VTESC" 3 "VTSelectInputObject" 33 "AuxiliaryInputStatus" 254 "VTStatusMessage" 224 "GetVersionsResponse" 210 "DeleteVersionResponse" 209 "LoadVersionResponse" 208 "StoreVersionResponse" 199 "GetHardwareResponse" 195 "GetTextFontDataResponse" 194 "GetNumberOfSoftKeysResponse" 192 "GetMemoryResponse" 178 "DeleteObjectPoolResponse" 177 "ChangeListItemResponse" 176 "ChangePriorityResponse" 175 "ChangeAttributeResponse" 174 "ChangeSoftKeyMaskResponse" 173 "ChangeActiveMaskResponse" 172 "ChangeFillAttributesResponse" 171 "ChangeLineAttributesResponse" 170 "ChangeFontAttributesResponse" 169 "ChangeEndPointResponse" 168 "ChangeNumericValueResponse" 167 "ChangeBackgroundColourResponse" 166 "ChangeSizeResponse" 165 "ChangeChildLocationResponse" 164 "SetAudioVolumeResponse" 163 "ControlAudioDeviceResponse" 162 "SelectInputObjectResponse" 161 "EnableDisableObjectResponse" 160 "ShowHideObjectResponse" 146 "ESCResponse" 32 "AuxiliaryAssignmentCommand" 18 "EndOfObjectPoolResponse" 2 "PointingEvent" 1 "ButtonActivation" 0 "SoftKeyActivation" 181 "SetObjectLabelResponse" 182 "ChangePolygonPointResponse" 183 "ChangePolygonScaleResponse" 184 "GraphicsContextCommandResponse" 185 "GetAttributeValueResponse" 186 "SelectColourMapResponse" 9 "VTOnUserLayoutHideShow" 10 "VTControlAudioDeviceTermination" 35 "AuxiliaryInputMaintenance" 189 "LockUnlockMaskResponse" 190 "ExecuteMacroResponse" 37 "AuxiliaryInputStatusEnableCommand" 193 "GetSupported WideCharsResponse" 36 "AuxiliaryAssignmentCommandType2" 38 "AuxiliaryInputStatusType2" 187 "IdentifyVTResponse" 197 "GetSupportedObjectsResponse" 188 "ExecuteExtendedMacroResponse" 211 "ExtendedGetVersionsResponse" 212 "ExtendedStoreVersionResponse" 213 "ExtendedLoadVersionResponse" 214 "ExtendedDeleteVersionResponse" 39 " AuxiliaryCapabilitiesResponse" ;
VAL_ 2565799554 IndustryGroup 0 "Global" 1 "OnHighway" 2 "AgriculturalAndForestry" 3 "Construction" 4 "Marine" 5 "Reserved" 7 "NotAvailable" ;
VAL_ 2565799554 Function 43 "Transmission Display" 44 "Exhaust Emission Control" 45 "Vehicle Dynamic Stability Control" 46 "Oil Sensor Unit" 47 "Information System Controller" 48 "Ramp Control" 49 "Clutch/Converter Control" 50 "Auxiliary Heater" 51 "Forward-Looking Collision Warning System" 52 "Chassis Controller" 53 "Alternator/Charging System" 54 "Communications Unit, Cellular" 55 "Communications Unit, Satellite" 56 "Communications Unit, Radio" 57 "Steering Column Unit" 58 "Fan Drive Control" 59 "Starter" 60 "Cab Display" 61 "File Server/Printer" 62 "On-Board Diagnostic Unit" 63 "Engine Valve Controller" 64 "Endurance Braking" 65 "Gas Flow Measurement" 66 "I/O Controller" 67 "Electrical System Controller" 68 "Aftertreatment system gas measurement" 69 "Engine Emission Aftertreatement System" 70 "Auxiliary Regeneration Device" 71 "Transfer Case Control" 72 "Coolant Valve Controller" 73 "Rollover Detection Control" 74 "Lubrication System" 75 "Supplemental Fan" 76 "Temperature Sensor" 77 "Fuel Properties Sensor" 78 "Fire Suppression System" 79 "Power Systems Manager" 80 "Electric Powertrain" 81 "Hydraulic Powertrain" 82 "File Server" 83 "Printer" 84 "Start Aid Device" 85 "Engine Injection Control Module" 86 "Reserved" 87 "Reserved" 88 "Reserved" 89 "Reserved" 90 "Reserved" 91 "Reserved" 92 "Reserved" 93 "Reserved" 94 "Reserved" 95 "Reserved" 96 "Reserved" 97 "Reserved" 98 "Reserved" 99 "Reserved" 100 "Reserved" 0 "Engine" 1 "Auxiliary Power Unit (APU)" 2 "Electric Propulsion Control" 3 "Transmission" 4 "Battery Pack Monitor" 5 "Shift Control/Console" 6 "Power TakeOff - (Main or Rear)" 7 "Axle - Steering" 8 "Axle - Drive" 9 "Brakes - System Controller" 10 "Brakes - Steer Axle" 11 "Brakes - Drive Axle" 12 "Retarder - Engine" 13 "Retarder - Driveline" 14 "Cruise Control" 15 "Fuel System" 16 "Steering Controller" 17 "Suspension - Steer Axle" 18 "Suspension - Drive Axle" 19 "Instrument Cluster" 20 "Trip Recorder" 21 "Cab Climate Control" 22 "Aerodynamic Control" 23 "Vehicle Navigation" 24 "Vehicle Security" 25 "Network Interconnect ECU" 26 "Body Controller" 27 "Power TakeOff (Secondary or Front)" 28 "Off Vehicle Gateway" 29 "Virtual Terminal (in cab)" 30 "Management Computer" 31 "Propulsion Battery Charger" 32 "Headway Controller" 33 "System Monitor" 34 "Hydraulic Pump Controller" 35 "Suspension - System Controller" 36 "Pneumatic - System Controller" 37 "Cab Controller" 38 "Tire Pressure Control" 39 "Ignition Control Module" 40 "Seat Control" 41 "Lighting - Operator Controls" 42 "Water Pump Control" 101 "Reserved" 102 "Reserved" 103 "Reserved" 104 "Reserved" 105 "Reserved" 106 "Reserved" 107 "Reserved" 108 "Reserved" 109 "Reserved" 110 "Reserved" 111 "Reserved" 112 "Reserved" 113 "Reserved" 114 "Reserved" 115 "Reserved" 116 "Reserved" 117 "Reserved" 118 "Reserved" 119 "Reserved" 120 "Reserved" 121 "Reserved" 122 "Reserved" 123 "Reserved" 124 "Reserved" 125 "Reserved" 126 "Reserved" 127 "Reserved" 255 "Not Available" ;
VAL_ 2565799554 ManufacturerCode 1863 "Thomas G. Faria Co." 1862 "Sanshin" 1861 "Vector North America" 1860 "MMP" 1859 "Kvasar AB" 1858 "Litton" 1857 "Simrad" 1856 "Trimble" 1855 "Furuno USA" 1854 "Northstar Technologies" 1853 "Japan Radio Co." 1852 "Navionics" 1851 "Raymarine" 1850 "Teleflex" 222 "Generac Power Systems, Inc." 221 "SiE" 220 "Beede Electrical Instrument Company, Inc." 219 "Cat OEM Solutions" 218 "Gits Manufacturing Company" 217 "RM Michaelides Software & Elektronik GmbH" 216 "Paneltronics Inc." 215 "Aetna Engineering/Fireboy-Xintex" 214 "MC elettronica Srl" 213 "CNH Belgium N.V." 212 "Sure Power Industries, Inc." 211 "DNA Group" 210 "Iteris, Inc." 209 "Bell Equip. Co. SA (PTY) LTD" 208 "Drew Technologies, Inc." 207 "Otto Engineering" 206 "port GmbH" 205 "SmarTire Systems Inc" 204 "The Morey Corporation" 203 "MILtronik GmbH" 202 "Curtis Instruments, Inc." 201 "Disenos y Tecnologia S.A." 200 "MGM Brakes" 199 "Actia Corp." 198 "Mystic Valley Communications" 197 "Mechron Power Systems" 196 "LEMKEN GmbH & Co. KG" 195 "General Engine Products" 194 "TriMark Corporation" 193 "Jeppesen Marine" 192 "Floscan" 191 "XATA Corporation" 190 "Hella KGaA Hueck & Co." 189 "QUALCOMM" 188 "EMP Corp." 187 "Air-Weigh" 186 "Altronic, Inc." 185 "Beede Electrical Instrument Company" 184 "EIA Electronics" 183 "KDS Controls, Inc." 182 "Vehicle Systems Engineering B.V." 181 "Coretronics, Inc." 180 "Smart Power Systems" 179 "TeeJet Technologies Denmark" 178 "Siemens VDO Automotive AG" 177 "Diagnostic System Associates" 176 "Moritz Aerospace" 175 "Veris Technologies, Inc." 174 "AB Volvo Penta" 173 "Ryeso, Inc." 172 "Yanmar Marine USA" 171 "Wachendorff Elektronik GmbH & Co. KG" 170 "Computronics Corporation Ltd." 169 "Marlin Technologies Inc." 168 "Xantrex" 167 "JLG Industries Inc." 166 "Phoenix International" 165 "CPAC Systems AB" 164 "DaimlerChrysler Off-Highway" 163 "BRP Inc." 162 "Axiomatic Technologies" 161 "Offshore Systems (UK) Limited" 160 "Nido" 159 "NTech Industries Inc." 158 "Firestone Industrial Products Company" 157 "ISSPRO Inc." 156 "ITT Industries - Cannon" 155 "Vetronix Corporation" 154 "Westerbeke Corporation" 153 "Woodward, Industrial Controls Division" 152 "Elobau Elektrobauelemente GmbH & Co. KG" 151 "Raven Industries Inc. - Flow Controls Division" 150 "Fleetguard" 149 "Holset" 148 "Blue Water Data, Inc." 147 "Nautibus Electronic GmbH" 146 "Maxima Technologies" 145 "MurCal Controls" 144 "Mercury Marine" 143 "W. Gmeiner GmbH & Co." 142 "TRW Automotive (Commercial Steering Systems)" 141 "Thales Navigation Ltd." 140 "Lowrance Electronics, Inc." 139 "Caterpillar Trimble Control Technologies (CTCT), LLC" 138 "Georg Fritzmeier GmbH & Co. KG" 137 "Maretron" 136 "Komatsu Ltd." 135 "Airmar Technology Corporation" 134 "Iris Technology Ltd." 133 "Bucher Schoerling GmbH" 132 "Mulag-Fahrzeugwerk" 131 "ITT Industries" 130 "Nido - Universal Machines B.V." 129 "OMNEX Control Systems, Inc." 128 "Gerhard Duecker GmbH & Co. KG" 127 "Holland USA" 126 "Driver Tech" 125 "Nevada Automotive Test Center" 124 "Hydac Electronic" 123 "Basler Electric" 122 "FG Wilson (Engineering) Limited" 121 "HED (Hydro Electronic Devices, Inc.)" 120 "RDS Technology Ltd." 119 "IntegriNautics" 118 "Intron GmbH" 117 "HUSCO International" 116 "BEELINE Technologies" 115 "NACCO Materials Handling Group, Inc." 114 "EControls, Inc." 113 "Stress-Tek, Inc." 112 "MECALAC" 111 "Maschinenfabrik Bernhard Krone GmbH" 110 "EPIQ Sensor-Nite" 109 "TeeJet Technologies Denmark" 108 "WTK-Elecktronik GmbH" 107 "Grimme Landmaschinen GmbH & Co. KG" 106 "BAE Systems Controls, Inc." 105 "Kiepe Elektrik GmbH & Co. KG" 104 "Claas Selbstfahrende Erntemaschinen GmbH" 103 "Agrocom GmbH & Co. Agrarsystem KG" 102 "AGCO GmbH & Co." 101 "Sensoria" 100 "VDO Technik AG" 99 "International Transmissions Ltd (ITL)" 98 "Mueller-Elektronik GmbH & Co." 97 "Ag Leader Technology, Inc." 96 "Mech@tronic IT GmbH" 95 "Pacific Insight Electronics Corp." 94 "CNH Global N.V." 93 "Perkins Engines Company Ltd." 92 "Ag-Chem Equipment Co., Inc." 91 "BSG Bodensee Steuergeraete GmbH" 90 "Knorr-Bremse SfN GmbH" 89 "Kverneland Group, Electronics Division" 88 "Satloc Precision GPS" 87 "J.C. Bamford Excavators Ltd (JCB)" 86 "C.E. Niehoff & Company" 85 "Kohler Co." 84 "New Holland UK Limited" 83 "Eaton VORAD Technologies" 82 "Bobcat/Ingersoll-Rand" 81 "Fire Research Corp" 80 "Twin Disc, Inc." 79 "Daimler Benz AG - Engine Division (PBM)" 78 "Frank W. Murphy Manufacturing, Inc." 77 "Deere Power Systems Group" 76 "unused" 75 "Deere & Co. Agricultural Division" 74 "Eaton Axle-Brake Division" 73 "LeTourneau, Inc." 72 "Sisu Corporation" 71 "Vansco Electronics Ltd." 70 "Flex-Coil Limited" 69 "Trimble Navigation" 68 "Scania" 67 "Funk Manufacturing Company" 66 "John Deere Construction Equipment Division" 65 "MAN Nutzfahrzeuge AG" 64 "unused" 63 "ZF Industries Inc." 62 "Wabco" 61 "Volvo Truck Corp." 60 "Volvo Trucks North America Inc." 59 "VES Inc." 58 "SPX Corporation, OTC Division" 57 "Sauer-Danfoss Co." 56 "SAIC" 55 "Ryder System Inc." 54 "Meritor Wabco" 53 "Continental Automotive Systems US, Inc." 52 "Meritor Automotive, Inc." 51 "Robert Bosch GmbH" 50 "Robert Bosch Corp" 49 "RE America Inc." 48 "Pollak Alphabet" 47 "Phillips Semiconductor" 46 "Parasoft Computing Solutions" 45 "PACCAR" 44 "Nippondenso Co. Ltd." 43 "International Truck and Engine Corp. Vehicle Electronics" 42 "International Truck and Engine Corp. Engine Electronics" 41 "Motorola Inc." 40 "Motorola AIEG Inc." 39 "Microfirm Inc." 38 "Micro Processor Systems Inc." 37 "Mack Trucks Inc." 36 "Lucas Ltd." 35 "Kenworth Truck Co." 34 "Kelsey Hayes Co." 33 "John Deere" 32 "Jacobs Vehicle Systems" 31 "J Pollak Corp." 30 "Isuzu Motors Ltd." 29 "Hino Motors Ltd." 28 "Grote Ind. Inc." 27 "GMC" 26 "General Motors Corp., Service Technology Group" 25 "Daimler Trucks North America LLC" 24 "Ford Motor Co., Vehicle Controls" 23 "Ford Motor Co., Heavy Truck" 22 "Ford Motor Co., Electronic Concepts $ Systems" 21 "Echilin Inc., Midland Brake Inc." 20 "Eaton Ltd" 19 "Eaton Corp. Trucking Info Services" 18 "Eaton Corp, Transmission Division" 17 "Eaton Corp. Res & Dev" 16 "Eaton Corp." 15 "Dickey-John Corp." 14 "Detroit Diesel Corporation" 13 "Delco Electronics" 12 "Deere & Company, Precision Farming" 11 "Dearborn Group Inc." 10 "Cummins Engine Co." 9 "Chrysler Corp." 8 "Caterpillar Inc." 7 "Case Corp." 6 "Berifors Electronics AB" 5 "AMP Inc." 4 "Ametek-Dixson" 3 "Ametek, US Gauge Division" 2 "Allison Transmission, GMC" 1 "Allied Signal Inc." 0 "Reserved" ;
VAL_ 2565799554 VehicleSystem 0 "Non-specific System" 127 "Not Available" ;
VAL_ 2565799554 VehicleSystem5 127 "Not Available" 0 "Ind. Process Control Stationary" ;
VAL_ 2565799554 VehicleSystem4 100 "Deck/Cargo/Fishing equip. sys" 90 "Environmental (HVAC) Systems" 80 "Instrumentation/General Systems" 70 "Communications Systems" 60 "Navigation Systems" 50 "Propulsion Systems" 40 "Steering Systems" 30 "Power Mgmt and lighting systems" 25 "Gateway" 20 "Safety Systems" 10 "System Tools" 127 "Not Available" 0 "Non-specific System" ;
VAL_ 2565799554 VehicleSystem3 8 "Grader" 7 "Four Wheel Drive Loader" 6 "Forklift" 5 "Excavator" 4 "Crawler" 3 "Backhoe" 2 "Articulated Dump Truck" 1 "Skid Steer Loader" 127 "Not Available" 0 "Non-specific System" ;
VAL_ 2565799554 VehicleSystem2 16 "Skidder" 15 "Earth Work" 14 "Special Crops" 13 "Powered Auxiliary Device" 12 "Farm Yard Operations" 11 "Transport/Trailer" 10 "Irrigation" 9 "Forage" 8 "Root Harvesters" 7 "Harvesters" 6 "Sprayers" 5 "Fertilizers" 4 "Planters/Seeders" 3 "Secondary Tillage" 2 "Tillage" 1 "Tractor" 127 "Not Available" 0 "Non-specific System" ;
VAL_ 2565799554 VehicleSystem1 2 "Trailer" 1 "Tractor" 127 "Not Available" 0 "Non-specific System" ;
VAL_ 2565340802 VTFunctionECUtoVT 193 "GetSupported WideChars" 37 "AuxiliaryInputStatusEnableCommandResponse" 35 "AuxiliaryInputMaintenance" 190 "ExecuteMacro" 189 "LockUnlockMask" 34 "AuxiliaryPreferredAssignment" 9 "DisplayActivationResponse" 186 "SelectColourMap" 185 "GetAttribute" 184 "GraphicsContextCommand" 183 "ChangePolygonScale" 182 "ChangePolygonPoint" 181 "SetObjectLabel" 0 "SoftKeyActivationResponse" 1 "ButtonActivationResponse" 2 "PointingEventResponse" 18 "EndOfObjectPool" 32 "AuxiliaryAssignmentResponse" 146 "ESC" 160 "ShowHideObject" 161 "EnableDisableObject" 162 "SelectInputObject" 163 "ControlAudioDevice" 164 "SetAudioVolume" 165 "ChangeChildLocation" 166 "ChangeSize" 167 "ChangeBackgroundColour" 168 "ChangeNumericValue" 169 "ChangeEndPoint" 170 "ChangeFontAttributes" 171 "ChangeLineAttributes" 172 "ChangeFillAttributes" 173 "ChangeActiveMask" 174 "ChangeSoftKeyMask" 175 "ChangeAttribute" 176 "ChangePriority" 177 "ChangeListItem" 178 "DeleteObjectPool" 192 "GetMemory" 194 "GetNumberOfSoftKeys" 195 "GetTextFontData" 199 "GetHardware" 208 "StoreVersion" 209 "LoadVersion" 210 "DeleteVersion" 223 "GetVersions" 255 "WorkingSetMaintenance" 179 "ChangeStringValue" 3 "VTSelectInputObjectResponse" 4 "VTESCResponse" 5 "VTChangeNumericValueResponse" 6 "VTChangeActiveMaskResponse" 7 "VTChangeSoftKeyMaskResponse" 196 "GetFillAndLineData" 17 "ObjectPoolTransfer" 180 "ChangeChildPosition" 8 "VTChangeStringValueResponse" ;
VAL_ 2565340802 KeyActivationCode 3 "KeyPressAborted" 0 "KeyHasBeenReleased" 1 "KeyHasBeenPressed" 2 "KeyIsStillHeld" ;
VAL_ 2565340802 KeyObjectParentID 0 "KeyHasBeenReleased" 1 "KeyHasBeenPressed" 2 "KeyIsStillHeld" ;
VAL_ 2565340802 KeyObjectID 0 "KeyHasBeenReleased" 1 "KeyHasBeenPressed" 2 "KeyIsStillHeld" ;
VAL_ 2565340802 ButtonActivationCode 3 "ButtonPressAborted" 0 "ButtonHasBeenUnlatched" 1 "ButtonHasBeenLatched" 2 "ButtonsStillHeld" ;
VAL_ 2565340802 ButtonObjectID 0 "ButtonHasBeenUnlatched" 1 "ButtonHasBeenLatched" 2 "ButtonsStillHeld" ;
VAL_ 2565340802 ButtonObjectParentID 0 "ButtonHasBeenUnlatched" 1 "ButtonHasBeenLatched" 2 "ButtonsStillHeld" ;
VAL_ 2565340802 AssignmentErrorNotAccepted 0 "AssignmentAccepted" 1 "Rejected_InputAlreadyAssigned" ;
VAL_ 2565340802 IsEnabled 0 "Disabled" 1 "Enabled" 255 "InputTypeIsAnalog" ;
VAL_ 2565340802 ShowOrHide 0 "Hide" 1 "Show" ;
VAL_ 2565340802 EnableOrDisable 0 "Disable" 1 "Enable" ;
VAL_ 2565340802 MaskType 1 "Data" 2 "Alarm" ;
VAL_ 2314732286 COGReference 3 "Null" 2 "Error" 1 "Magnetic" 0 "True" ;
VAL_ 2566688384 Functionality 0 "Minimum control function  " 1 "Universal terminal (server)" 2 "Universal terminal working set (client) " 3 "Aux-O inputs " 4 "Aux-O functions " 5 "Aux-N inputs " 6 "Aux-N functions " 7 "Task controller basic (server) " 8 "Task controller basic working set (client)" 9 "Task controller geo (server) " 10 "Task controller geo working set (client) " 11 "Task controller section control (server) " 12 "Task controller section control working set (client)" 13 "Basic Tractor ECU (server) " 14 "Basic Tractor ECU implement set (client) " ;
VAL_ 2566688510 Functionality 0 "Minimum control function  " 1 "Universal terminal (server)" 2 "Universal terminal working set (client) " 3 "Aux-O inputs " 4 "Aux-O functions " 5 "Aux-N inputs " 6 "Aux-N functions " 7 "Task controller basic (server) " 8 "Task controller basic working set (client)" 9 "Task controller geo (server) " 10 "Task controller geo working set (client) " 11 "Task controller section control (server) " 12 "Task controller section control working set (client)" 13 "Basic Tractor ECU (server) " 14 "Basic Tractor ECU implement set (client) " ;
VAL_ 2566786944 TimeFormatCmd 0 "Hour24" 1 "Hour12" 3 "NoAction" ;
VAL_ 2566786944 DecimalSymbolCmd 0 "CommaIsUsed" 1 "PointIsUsed" 3 "NoAction" ;
VAL_ 2566786944 DateFormatCmd 0 "ddmmyyyy" 1 "ddyyyymm" 2 "mmyyyydd" 3 "mmddyyyy" 4 "yyyymmdd" 5 "yyyyddmm" ;
VAL_ 2566786944 MassUnitCmd 0 "Metric" 1 "Imperial" 2 "TonsPounds" 3 "NoAction" ;
VAL_ 2566786944 VolumeUnitCmd 0 "Metric" 1 "Imperial" 2 "US" 3 "NoAction" ;
VAL_ 2566786944 AreaUnitCmd 0 "Metric" 1 "Imperial" 3 "NoAction" ;
VAL_ 2566786944 DistanceUnitCmd 0 "Metric" 1 "Imperial" 3 "NoAction" ;
VAL_ 2566786944 UnitsSystem 0 "Metric" 1 "Imperial" 2 "US" 3 "NoAction" ;
VAL_ 2566786944 ForceUnits 0 "Metric" 1 "Imperial" 2 "Reserved" 3 "NoAction" ;
VAL_ 2566786944 PressureUnits 0 "Metric" 1 "Imperial" 2 "Reserved" 3 "NoAction" ;
VAL_ 2566786944 TemperatureUnits 0 "Metric" 1 "Imperial" 2 "Reserved" 3 "NoAction" ;
VAL_ 2566835072 MalfunctionIndicatorLampStatus 3 "Not available" 2 "Reserved" 1 "Lamp on" 0 "Lamp off" ;
VAL_ 2566835072 RedStopLampState 3 "Not available" 2 "Reserved" 1 "Lamp on" 0 "Lamp off" ;
VAL_ 2566835072 AmberWarningLampStatus 3 "Not available" 2 "Reserved" 1 "Lamp on" 0 "Lamp off" ;
VAL_ 2566835072 ProtectLampStatus 3 "Not available" 2 "Reserved" 1 "Lamp on" 0 "Lamp off" ;
VAL_ 2566835072 FlashRedStopLamp 3 "Unavailable / Do Not Flash" 2 "Reserved" 1 "Fast Flash" 0 "Slow Flash" ;
VAL_ 2566835072 FlashProtectLamp 3 "Unavailable / Do Not Flash" 2 "Reserved" 1 "Fast Flash" 0 "Slow Flash" ;
VAL_ 2566835072 FlashMalfuncIndicatorLamp 3 "Unavailable / Do Not Flash" 2 "Reserved" 1 "Fast Flash" 0 "Slow Flash" ;
VAL_ 2566835072 FlashAmberWarningLamp 3 "Unavailable / Do Not Flash" 2 "Reserved" 1 "Fast Flash" 0 "Slow Flash" ;
VAL_ 2566834816 FlashRedStopLamp 3 "Unavailable / Do Not Flash" 2 "Reserved" 1 "Fast Flash" 0 "Slow Flash" ;
VAL_ 2566834816 FlashProtectLamp 3 "Unavailable / Do Not Flash" 2 "Reserved" 1 "Fast Flash" 0 "Slow Flash" ;
VAL_ 2566834816 FlashMalfuncIndicatorLamp 3 "Unavailable / Do Not Flash" 2 "Reserved" 1 "Fast Flash" 0 "Slow Flash" ;
VAL_ 2566834816 FlashAmberWarningLamp 3 "Unavailable / Do Not Flash" 2 "Reserved" 1 "Fast Flash" 0 "Slow Flash" ;
VAL_ 2566834816 MalfunctionIndicatorLampStatus 3 "Not available" 2 "Reserved" 1 "Lamp on" 0 "Lamp off" ;
VAL_ 2566834816 AmberWarningLampStatus 3 "Not available" 2 "Reserved" 1 "Lamp on" 0 "Lamp off" ;
VAL_ 2566834816 RedStopLampState 3 "Not available" 2 "Reserved" 1 "Lamp on" 0 "Lamp off" ;
VAL_ 2566834816 ProtectLampStatus 3 "Not available" 2 "Reserved" 1 "Lamp on" 0 "Lamp off" ;
VAL_ 2566835184 MalfunctionIndicatorLampStatus 3 "Not available" 2 "Reserved" 1 "Lamp on" 0 "Lamp off" ;
VAL_ 2566835184 RedStopLampState 3 "Not available" 2 "Reserved" 1 "Lamp on" 0 "Lamp off" ;
VAL_ 2566835184 AmberWarningLampStatus 3 "Not available" 2 "Reserved" 1 "Lamp on" 0 "Lamp off" ;
VAL_ 2566835184 ProtectLampStatus 3 "Not available" 2 "Reserved" 1 "Lamp on" 0 "Lamp off" ;
VAL_ 2566835184 FlashRedStopLamp 3 "Unavailable / Do Not Flash" 2 "Reserved" 1 "Fast Flash" 0 "Slow Flash" ;
VAL_ 2566835184 FlashProtectLamp 3 "Unavailable / Do Not Flash" 2 "Reserved" 1 "Fast Flash" 0 "Slow Flash" ;
VAL_ 2566835184 FlashMalfuncIndicatorLamp 3 "Unavailable / Do Not Flash" 2 "Reserved" 1 "Fast Flash" 0 "Slow Flash" ;
VAL_ 2566835184 FlashAmberWarningLamp 3 "Unavailable / Do Not Flash" 2 "Reserved" 1 "Fast Flash" 0 "Slow Flash" ;
VAL_ 2566834928 FlashRedStopLamp 3 "Unavailable / Do Not Flash" 2 "Reserved" 1 "Fast Flash" 0 "Slow Flash" ;
VAL_ 2566834928 FlashProtectLamp 3 "Unavailable / Do Not Flash" 2 "Reserved" 1 "Fast Flash" 0 "Slow Flash" ;
VAL_ 2566834928 FlashMalfuncIndicatorLamp 3 "Unavailable / Do Not Flash" 2 "Reserved" 1 "Fast Flash" 0 "Slow Flash" ;
VAL_ 2566834928 FlashAmberWarningLamp 3 "Unavailable / Do Not Flash" 2 "Reserved" 1 "Fast Flash" 0 "Slow Flash" ;
VAL_ 2566834928 MalfunctionIndicatorLampStatus 3 "Not available" 2 "Reserved" 1 "Lamp on" 0 "Lamp off" ;
VAL_ 2566834928 AmberWarningLampStatus 3 "Not available" 2 "Reserved" 1 "Lamp on" 0 "Lamp off" ;
VAL_ 2566834928 RedStopLampState 3 "Not available" 2 "Reserved" 1 "Lamp on" 0 "Lamp off" ;
VAL_ 2566834928 ProtectLampStatus 3 "Not available" 2 "Reserved" 1 "Lamp on" 0 "Lamp off" ;
